VERSION ""

NS_ :

BS_:

BU_:

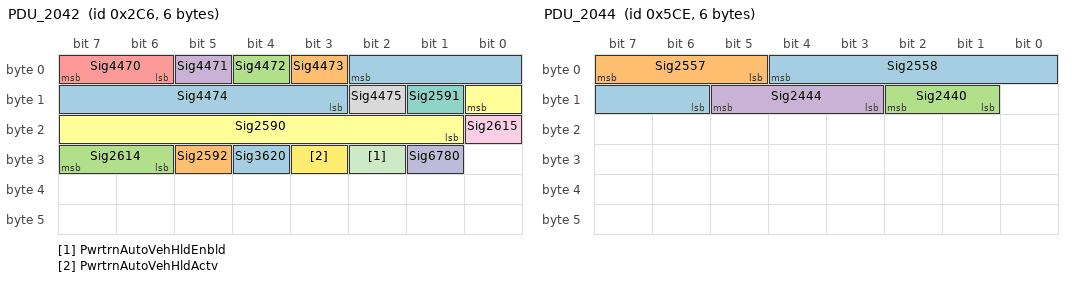
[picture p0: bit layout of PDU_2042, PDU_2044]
BO_ 710 PDU_2042: 6 Vector__XXX
 SG_ Sig4474 : 2|8@0+ (0.1,0) [0|25.5] "Volt" BSM
 SG_ Sig4473 : 3|1@0+ (1,0) [0|1] "" BSM
 SG_ Sig4472 : 4|1@0+ (1,0) [0|1] "" BSM
 SG_ Sig4471 : 5|1@0+ (1,0) [0|1] "" BSM
 SG_ Sig4470 : 7|2@0+ (1,0) [0|3] "" BSM
 SG_ Sig2590 : 8|8@0+ (0.392157,0) [0|100] "%" CGM
 SG_ Sig2591 : 9|1@0+ (1,0) [0|1] "" CGM
 SG_ Sig4475 : 10|1@0+ (1,0) [0|1] "" BSM
 SG_ Sig2615 : 16|1@0+ (1,0) [0|1] "" TCM
 SG_ Sig6780 : 25|1@0+ (1,0) [0|1] "" BSM
 SG_ PwrtrnAutoVehHldEnbld : 26|1@0+ (1,0) [0|1] "" EBCM
 SG_ PwrtrnAutoVehHldActv : 27|1@0+ (1,0) [0|1] "" EBCM
 SG_ Sig3620 : 28|1@0+ (1,0) [0|1] "" BSM,ECP_X1
 SG_ Sig2592 : 29|1@0+ (1,0) [0|1] "" TCM
 SG_ Sig2614 : 31|2@0+ (1,0) [0|3] "" TCM

BO_ 948 PDU_2043: 12 Vector__XXX
 SG_ Sig2550 : 2|12@0+ (0.5,-848) [-848|1199.5] "Nm" RDCM,TCCM,TCM
 SG_ Sig2549 : 6|4@0+ (1,0) [0|15] "" TCM
 SG_ Sig2548 : 7|1@0+ (1,0) [0|1] "" TCM
 SG_ Sig2551 : 22|12@0+ (0.5,-848) [-848|1199.5] "Nm" TCM
 SG_ Sig2552 : 26|12@0+ (0.5,-848) [-848|1199.5] "Nm" TCM
 SG_ Sig2553 : 46|8@0+ (32,0) [0|8160] "rpm" TCM
 SG_ BarPrsAbs : 53|8@0+ (0.5,0) [0|127.5] "kPa" BSM,VICM,CGM,TCM
 SG_ BarPrsAbs_Inv : 54|1@0+ (1,0) [0|1] "" BSM,VICM,CGM,TCM
 SG_ Sig2640 : 60|8@0+ (4,0) [0|1020] "kPa" CGM
 SG_ Sig2642 : 61|1@0+ (1,0) [0|1] "" CGM
 SG_ Sig4942 : 68|8@0+ (0.5,0) [0|127.5] "%" TCM

BO_ 1486 PDU_2044: 6 Vector__XXX
 SG_ Sig2558 : 4|7@0+ (1,0) [0|127] "%" CGM
 SG_ Sig2557 : 7|3@0+ (1,0) [0|5] "" CGM
 SG_ Sig2440 : 10|2@0+ (1,0) [0|1] "" CGM
 SG_ Sig2444 : 13|3@0+ (1,0) [0|7] "" CGM

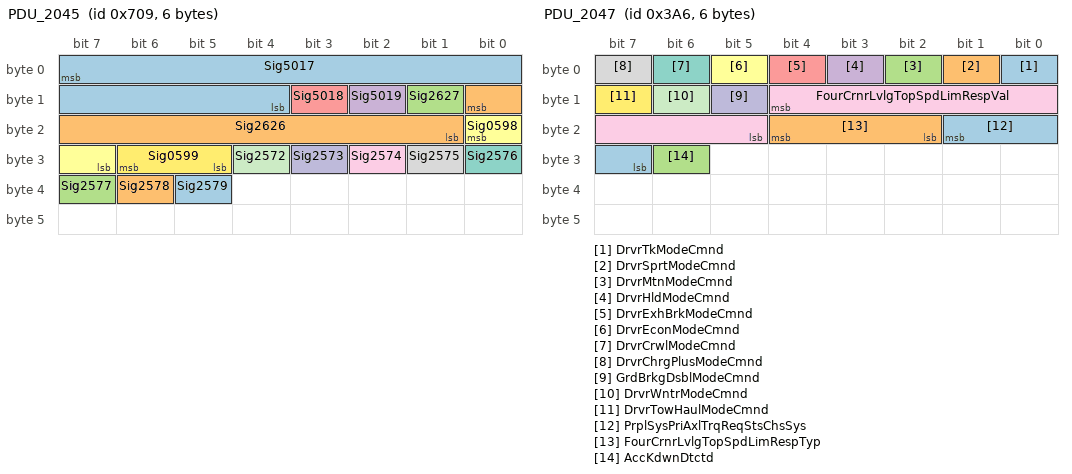
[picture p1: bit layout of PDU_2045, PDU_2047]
BO_ 1801 PDU_2045: 6 Vector__XXX
 SG_ Sig5017 : 7|12@0+ (0.5,0) [0|2047.5] "min" TCM
 SG_ Sig2626 : 8|8@0+ (1,-40) [-40|215] "Deg C" CGM,TCM
 SG_ Sig2627 : 9|1@0+ (1,0) [0|1] "" CGM,TCM
 SG_ Sig5019 : 10|1@0+ (1,0) [0|1] "" TCM
 SG_ Sig5018 : 11|1@0+ (1,0) [0|1] "" TCM
 SG_ Sig0598 : 16|2@0+ (1,0) [0|3] "" TCM
 SG_ Sig2576 : 24|1@0+ (1,0) [0|1] "" CGM
 SG_ Sig2575 : 25|1@0+ (1,0) [0|1] "" CGM
 SG_ Sig2574 : 26|1@0+ (1,0) [0|1] "" CGM
 SG_ Sig2573 : 27|1@0+ (1,0) [0|1] "" CGM
 SG_ Sig2572 : 28|1@0+ (1,0) [0|1] "" CGM
 SG_ Sig0599 : 30|2@0+ (1,0) [0|3] "" TCM
 SG_ Sig2579 : 37|1@0+ (1,0) [0|1] "" CGM
 SG_ Sig2578 : 38|1@0+ (1,0) [0|1] "" CGM
 SG_ Sig2577 : 39|1@0+ (1,0) [0|1] "" CGM

BO_ 63 PDU_2046: 4 Vector__XXX
 SG_ RdLdNomAxlTrq : 7|19@0+ (0.125,-22534) [-22534|43001.9] "Nm" ACP2_MCU,CGM,EOCM,EOCM_HC_Superset,FCM

BO_ 934 PDU_2047: 6 Vector__XXX
 SG_ DrvrTkModeCmnd : 0|1@0+ (1,0) [0|1] "" PCM,TCM,ECP_X1
 SG_ DrvrSprtModeCmnd : 1|1@0+ (1,0) [0|1] "" PCM,TCM,ECP_X1
 SG_ DrvrMtnModeCmnd : 2|1@0+ (1,0) [0|1] "" ECP_X1
 SG_ DrvrHldModeCmnd : 3|1@0+ (1,0) [0|1] "" ECP_X1
 SG_ DrvrExhBrkModeCmnd : 4|1@0+ (1,0) [0|1] "" PCM,TCM
 SG_ DrvrEconModeCmnd : 5|1@0+ (1,0) [0|1] "" PCM,TCM
 SG_ DrvrCrwlModeCmnd : 6|1@0+ (1,0) [0|1] "" CGM,PCM,TCM
 SG_ DrvrChrgPlusModeCmnd : 7|1@0+ (1,0) [0|1] "" ECP_X1
 SG_ FourCrnrLvlgTopSpdLimRespVal : 12|8@0+ (2,0) [0|510] "km/h" CGM
 SG_ GrdBrkgDsblModeCmnd : 13|1@0+ (1,0) [0|1] "" PCM,TCM,ECP_X1
 SG_ DrvrWntrModeCmnd : 14|1@0+ (1,0) [0|1] "" PCM,TCM
 SG_ DrvrTowHaulModeCmnd : 15|1@0+ (1,0) [0|1] "" ACP2_MCU,EOCM,EOCM_HC_Superset,FCM,PCM,TCM,ECP_X1
 SG_ PrplSysPriAxlTrqReqStsChsSys : 17|3@0+ (1,0) [0|6] "" EBCM
 SG_ FourCrnrLvlgTopSpdLimRespTyp : 20|3@0+ (1,0) [0|6] "" CGM
 SG_ AccKdwnDtctd : 30|1@0+ (1,0) [0|1] "" ACP2_MCU,EOCM,EOCM_HC_Superset,FCM,PCM,TCM

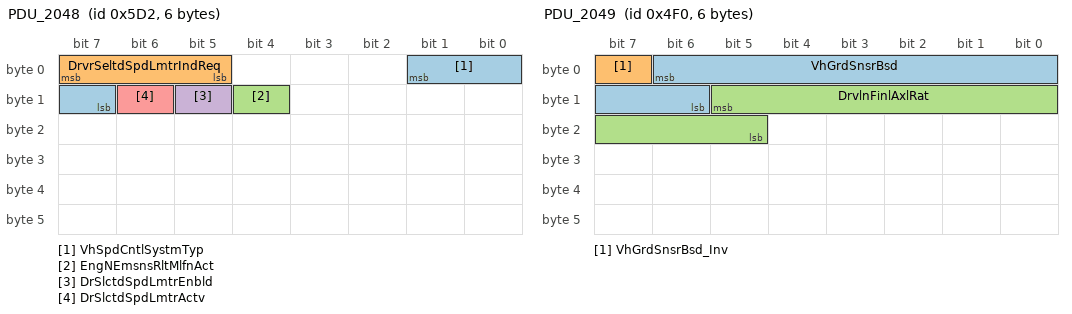
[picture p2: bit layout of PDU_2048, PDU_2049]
BO_ 1490 PDU_2048: 6 Vector__XXX
 SG_ VhSpdCntlSystmTyp : 1|3@0+ (1,0) [0|2] "" ACP2_MCU,CGM,EOCM,EOCM_HC_Superset,FCM
 SG_ DrvrSeltdSpdLmtrIndReq : 7|3@0+ (1,0) [0|4] "" CGM
 SG_ EngNEmsnsRltMlfnAct : 12|1@0+ (1,0) [0|1] "" CGM
 SG_ DrSlctdSpdLmtrEnbld : 13|1@0+ (1,0) [0|1] "" CGM
 SG_ DrSlctdSpdLmtrActv : 14|1@0+ (1,0) [0|1] "" CGM

BO_ 1264 PDU_2049: 6 Vector__XXX
 SG_ VhGrdSnsrBsd : 6|9@0- (0.1945,0) [-49.792|49.5975] "%" ACP2_MCU,VICM,EOCM,EOCM_HC_Superset,E44,PCM,TCM,ECP_S,ECP_S2,ECP_X1
 SG_ VhGrdSnsrBsd_Inv : 7|1@0+ (1,0) [0|1] "" ACP2_MCU,VICM,EOCM,EOCM_HC_Superset,E44,PCM,TCM,ECP_S,ECP_S2,ECP_X1
 SG_ DrvlnFinlAxlRat : 13|9@0+ (0.01,2) [2|7.11] "" DCM,RDCM,TCCM

BO_ 52 PDU_2050: 4 Vector__XXX
 SG_ TrnsOvrllEstTrqRt : 6|15@0- (0.00390625,0) [-64|63.9961] "" CGM,EBCM,ECM,RDCM,TCCM
 SG_ TrnsOvrllEstTrqRt_Inv : 7|1@0+ (1,0) [0|1] "" EBCM,ECM,RDCM,TCCM

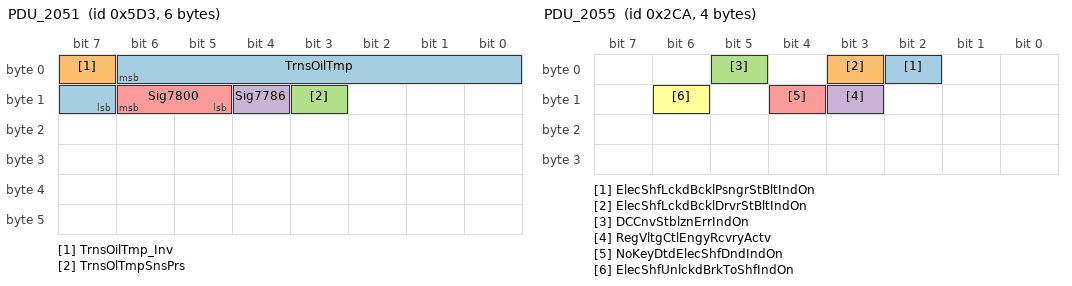
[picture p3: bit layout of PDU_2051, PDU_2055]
BO_ 1491 PDU_2051: 6 Vector__XXX
 SG_ TrnsOilTmp : 6|8@0+ (1,-40) [-40|215] "deg C" BSM,VICM,CGM,DCM,EBCM,ECM,PCM,TCCM,ECP_S,ECP_X1
 SG_ TrnsOilTmp_Inv : 7|1@0+ (1,0) [0|1] "" BSM,VICM,CGM,DCM,EBCM,ECM,PCM,TCCM,ECP_S
 SG_ TrnsOlTmpSnsPrs : 11|1@0+ (1,0) [0|1] "" CGM,TCCM
 SG_ Sig7786 : 12|1@0+ (1,0) [0|1] "" CGM,ECM
 SG_ Sig7800 : 14|2@0+ (1,0) [0|2] "" CGM,ECM

BO_ 99 PDU_2052: 2 Vector__XXX
 SG_ LoVltgSetptCmd : 7|8@0+ (0.07843,0) [0|19.9996] "volt" ECP_X1

BO_ 203 PDU_2053: 2 Vector__XXX
 SG_ RegVltgCtlPwrtrnOvrrdInhbd : 7|1@0+ (1,0) [0|1] "" CGM

BO_ 936 PDU_2054: 6 Vector__XXX
 SG_ GenStptDtCycPtOvrAct : 7|1@0+ (1,0) [0|1] "" CGM

BO_ 714 PDU_2055: 4 Vector__XXX
 SG_ ElecShfLckdBcklPsngrStBltIndOn : 2|1@0+ (1,0) [0|1] "" CGM
 SG_ ElecShfLckdBcklDrvrStBltIndOn : 3|1@0+ (1,0) [0|1] "" CGM
 SG_ DCCnvStblznErrIndOn : 5|1@0+ (1,0) [0|1] "" CGM
 SG_ RegVltgCtlEngyRcvryActv : 11|1@0+ (1,0) [0|1] "" CGM
 SG_ NoKeyDtdElecShfDndIndOn : 12|1@0+ (1,0) [0|1] "" CGM
 SG_ ElecShfUnlckdBrkToShfIndOn : 14|1@0+ (1,0) [0|1] "" CGM

BO_ 1492 PDU_2056: 6 Vector__XXX
 SG_ ElecShfPriTransCtlrMalfIndOn : 0|1@0+ (1,0) [0|1] "" CGM
 SG_ ElecShfPriShfToDrvTryAgnIndOn : 1|1@0+ (1,0) [0|1] "" CGM
 SG_ ElecShfPriRdcSpdForReqdShfIndOn : 2|1@0+ (1,0) [0|1] "" CGM
 SG_ AirCndOffIO : 3|1@0+ (1,0) [0|1] "" CGM
 SG_ EngCmptHotWrnIndReq : 5|2@0+ (1,0) [0|3] "" CGM
 SG_ ElecShftPrTwoGrsSelIndRq : 7|2@0+ (1,0) [0|3] "" CGM
 SG_ ElecShftPrLtdPrfMdIO : 8|1@0+ (1,0) [0|1] "" CGM
 SG_ ElecShftPrHldShftLevEngRngIO : 9|1@0+ (1,0) [0|1] "" CGM
 SG_ ElecShftPrDrPrkIntShftAtmpIO : 10|1@0+ (1,0) [0|1] "" CGM
 SG_ ElecShftPrDrIntShftAtmpIO : 11|1@0+ (1,0) [0|1] "" CGM
 SG_ ElecShftPrDrExitIO : 12|1@0+ (1,0) [0|1] "" CGM
 SG_ ElecShftPrDrDoorStIndIO : 13|1@0+ (1,0) [0|1] "" CGM
 SG_ ElecShftPrAtPrkIO : 14|1@0+ (1,0) [0|1] "" CGM
 SG_ ElecShfPriTrnVehOffForPrkIndOn : 15|1@0+ (1,0) [0|1] "" CGM
 SG_ ElecShftrLckdHldBrkToOvrrdIndOn : 20|1@0+ (1,0) [0|1] "" CGM
 SG_ ElecShftPrTrnMlfIO : 21|1@0+ (1,0) [0|1] "" CGM
 SG_ ElecShftPrRngInvRqIO : 22|1@0+ (1,0) [0|1] "" CGM
 SG_ ElecShftPrPrkInvRqIO : 23|1@0+ (1,0) [0|1] "" CGM

BO_ 1802 PDU_2057: 6 Vector__XXX
 SG_ UndrHdAirFlwCap : 7|9@0+ (2,0) [0|1022] "m^3/min" BSM,PCM,TCM
 SG_ UndrHdAirFlwActPrcnt : 14|7@0+ (0.787402,0) [0|100] "%" BSM,PCM,TCM

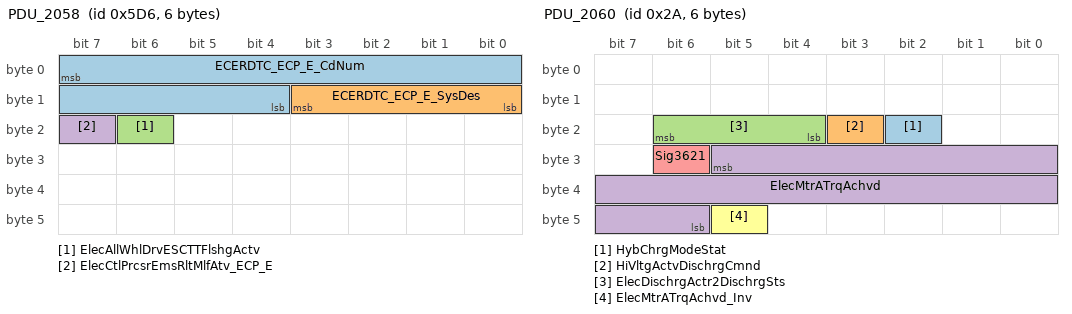
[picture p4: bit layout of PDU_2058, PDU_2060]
BO_ 1494 PDU_2058: 6 Vector__XXX
 SG_ ECERDTC_ECP_E_CdNum : 7|12@0+ (1,0) [0|4095] "count" ECM,PCM
 SG_ ECERDTC_ECP_E_SysDes : 11|4@0+ (1,0) [0|15] "" ECM,PCM
 SG_ ElecAllWhlDrvESCTTFlshgActv : 22|1@0+ (1,0) [0|1] "" EBCM
 SG_ ElecCtlPrcsrEmsRltMlfAtv_ECP_E : 23|1@0+ (1,0) [0|1] "" ECM,PCM

BO_ 1803 PDU_2059: 6 Vector__XXX
 SG_ DrvMtrInvrtMaxTemp : 6|8@0+ (1,-40) [-40|215] "deg C" BSM,VICM,VDM,ECP_S
 SG_ DrvMtrInvrtMaxTemp_Inv : 7|1@0+ (1,0) [0|1] "" BSM,VICM,VDM,ECP_S

BO_ 42 PDU_2060: 6 Vector__XXX
 SG_ HybChrgModeStat : 18|1@0+ (1,0) [0|1] "" BSM,VICM
 SG_ HiVltgActvDischrgCmnd : 19|1@0+ (1,0) [0|1] "" BSM,VICM
 SG_ ElecDischrgActr2DischrgSts : 22|3@0+ (1,0) [0|2] "" BSM,VICM
 SG_ ElecMtrATrqAchvd : 29|16@0- (0.125,0) [-4096|4095.88] "Nm" BSM,VICM,CGM,VDM
 SG_ Sig3621 : 30|1@0+ (1,0) [0|1] "" ECM,PCM
 SG_ ElecMtrATrqAchvd_Inv : 45|1@0+ (1,0) [0|1] "" VDM

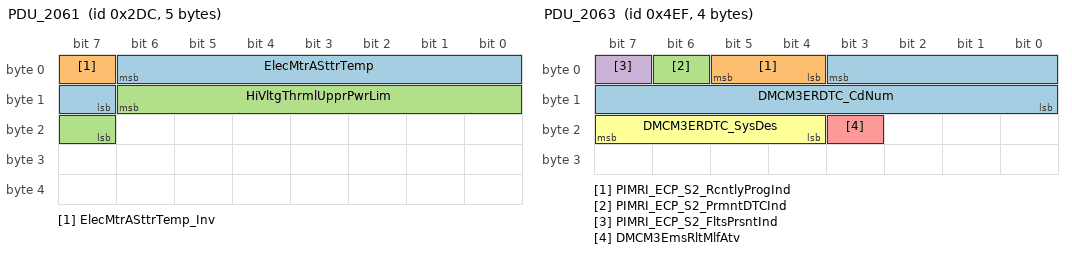
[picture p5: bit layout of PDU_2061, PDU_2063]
BO_ 732 PDU_2061: 5 Vector__XXX
 SG_ ElecMtrASttrTemp : 6|8@0+ (1,-40) [-40|215] "deg C" CGM,VDM
 SG_ ElecMtrASttrTemp_Inv : 7|1@0+ (1,0) [0|1] "" CGM,VDM
 SG_ HiVltgThrmlUpprPwrLim : 14|8@0+ (0.2,0) [0|51] "kW" BSM,VICM

BO_ 43 PDU_2062: 2 Vector__XXX
 SG_ ElecDischrgActr4DischrgSts : 7|3@0+ (1,0) [0|2] "" VICM

BO_ 1263 PDU_2063: 4 Vector__XXX
 SG_ DMCM3ERDTC_CdNum : 3|12@0+ (1,0) [0|4095] "Counts" ECP_E
 SG_ PIMRI_ECP_S2_RcntlyProgInd : 5|2@0+ (1,0) [0|3] "" ECP_E
 SG_ PIMRI_ECP_S2_PrmntDTCInd : 6|1@0+ (1,0) [0|1] "" ECP_E
 SG_ PIMRI_ECP_S2_FltsPrsntInd : 7|1@0+ (1,0) [0|1] "" ECP_E
 SG_ DMCM3EmsRltMlfAtv : 19|1@0+ (1,0) [0|1] "" ECP_E
 SG_ DMCM3ERDTC_SysDes : 23|4@0+ (1,0) [0|15] "" ECP_E

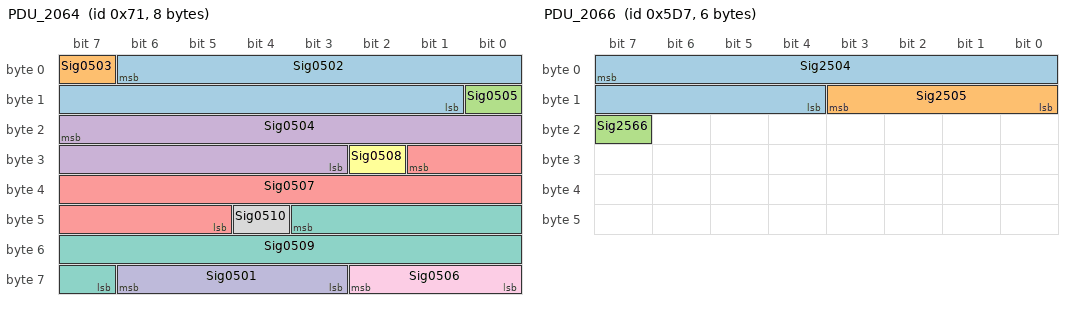
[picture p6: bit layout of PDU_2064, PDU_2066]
BO_ 113 PDU_2064: 8 Vector__XXX
 SG_ Sig0502 : 6|14@0- (0.1,0) [-819.2|819.1] "A" ECM,PCM
 SG_ Sig0503 : 7|1@0+ (1,0) [0|1] "" ECM,PCM
 SG_ Sig0505 : 8|1@0+ (1,0) [0|1] "" ECM,PCM
 SG_ Sig0504 : 23|13@0+ (0.0624,0) [0|511.118] "v" ECM,PCM
 SG_ Sig0507 : 25|13@0- (0.125,0) [-512|511.875] "Nm" ECM,PCM
 SG_ Sig0508 : 26|1@0+ (1,0) [0|1] "" ECM,PCM
 SG_ Sig0509 : 43|13@0- (0.125,0) [-512|511.875] "Nm" ECM,PCM
 SG_ Sig0510 : 44|1@0+ (1,0) [0|1] "" ECM,PCM
 SG_ Sig0506 : 58|3@0+ (1,0) [0|1] "" ECM,PCM
 SG_ Sig0501 : 62|4@0+ (1,0) [0|5] "" ECM,PCM

BO_ 733 PDU_2065: 2 Vector__XXX
 SG_ Sig0511 : 6|7@0+ (1,0) [0|127] "%" ECM,PCM
 SG_ Sig0512 : 7|1@0+ (1,0) [0|1] "" ECM,PCM

BO_ 1495 PDU_2066: 6 Vector__XXX
 SG_ Sig2504 : 7|12@0+ (1,0) [0|4095] "count" ECM,PCM
 SG_ Sig2505 : 11|4@0+ (1,0) [0|15] "" ECM,PCM
 SG_ Sig2566 : 23|1@0+ (1,0) [0|1] "" ECM,PCM

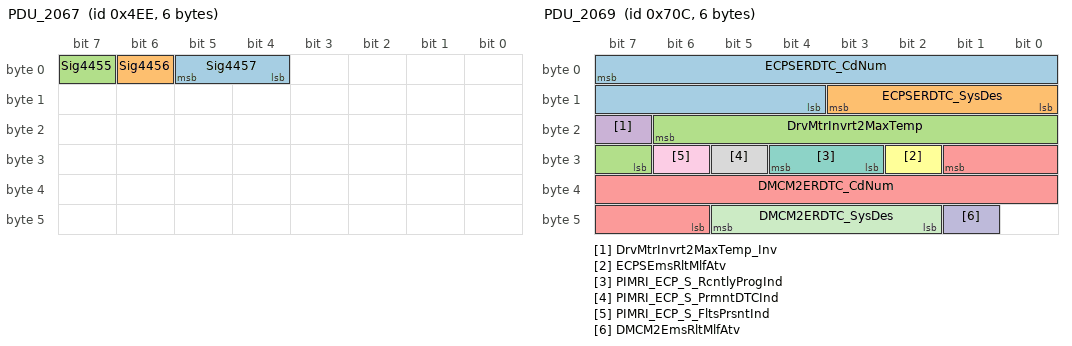
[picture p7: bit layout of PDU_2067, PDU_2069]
BO_ 1262 PDU_2067: 6 Vector__XXX
 SG_ Sig4457 : 5|2@0+ (1,0) [0|3] "" ECM,PCM
 SG_ Sig4456 : 6|1@0+ (1,0) [0|1] "" ECM,PCM
 SG_ Sig4455 : 7|1@0+ (1,0) [0|1] "" ECM,PCM

BO_ 41 PDU_2068: 2 Vector__XXX
 SG_ ElecDischrgActr3DischrgSts : 7|3@0+ (1,0) [0|2] "" VICM

BO_ 1804 PDU_2069: 6 Vector__XXX
 SG_ ECPSERDTC_CdNum : 7|12@0+ (1,0) [0|4095] "" ECP_E
 SG_ ECPSERDTC_SysDes : 11|4@0+ (1,0) [0|15] "" ECP_E
 SG_ DrvMtrInvrt2MaxTemp : 22|8@0+ (1,-40) [-40|215] "deg C" VICM,VDM,ECP_E
 SG_ DrvMtrInvrt2MaxTemp_Inv : 23|1@0+ (1,0) [0|1] "" VICM,VDM,ECP_E
 SG_ DMCM2ERDTC_CdNum : 25|12@0+ (1,0) [0|4095] "Counts" ECP_E
 SG_ ECPSEmsRltMlfAtv : 26|1@0+ (1,0) [0|1] "" ECP_E
 SG_ PIMRI_ECP_S_RcntlyProgInd : 28|2@0+ (1,0) [0|3] "" ECP_E
 SG_ PIMRI_ECP_S_PrmntDTCInd : 29|1@0+ (1,0) [0|1] "" ECP_E
 SG_ PIMRI_ECP_S_FltsPrsntInd : 30|1@0+ (1,0) [0|1] "" ECP_E
 SG_ DMCM2EmsRltMlfAtv : 41|1@0+ (1,0) [0|1] "" ECP_E
 SG_ DMCM2ERDTC_SysDes : 45|4@0+ (1,0) [0|15] "" ECP_E

BO_ 512 PDU_2070: 6 Vector__XXX
 SG_ Sig4937 : 7|19@0- (0.25,0) [-65536|65535.8] "Nm" ECM,PCM
 SG_ Sig4938 : 20|19@0- (0.25,0) [-65536|65535.8] "Nm" ECM,PCM

BO_ 734 PDU_2071: 4 Vector__XXX
 SG_ ElecMtrARotrTemp : 6|8@0+ (1,-40) [-40|215] "deg C" CGM,VDM
 SG_ ElecMtrARotrTemp_Inv : 7|1@0+ (1,0) [0|1] "" CGM,VDM

BO_ 1497 PDU_2072: 6 Vector__XXX
 SG_ Sig2564 : 5|2@0+ (1,0) [0|2] "" CGM
 SG_ Sig2563 : 7|2@0+ (1,0) [0|2] "" CGM

BO_ 1415 PDU_2073: 8 Vector__XXX
 SG_ RCMHSR_HptcStReqSeqNum : 1|2@0+ (1,0) [0|3] "counts" CGM
 SG_ RCMHSR_HptcStReqPuls : 7|6@0+ (1,0) [0|63] "pulses" CGM
 SG_ HtdStrgWhlDrvOutStsGtd : 9|3@0+ (1,0) [0|7] "" CGM
 SG_ HtdStrgWhlDrvOutStsGtd_Inv : 10|1@0+ (1,0) [0|1] "" CGM
 SG_ LnCntrWrnIndRqst : 15|5@0+ (1,0) [0|16] "" CGM
 SG_ LnFllwgHzrdLgtsReq : 16|2@0+ (1,0) [0|2] "" CGM
 SG_ LnCntrEsclnSts : 18|2@0+ (1,0) [0|3] "" CGM
 SG_ HtdStrgWhlStkSwGtd : 19|1@0+ (1,0) [0|1] "" CGM
 SG_ HtdStrgWhlStkSwGtd_Inv : 20|1@0+ (1,0) [0|1] "" CGM
 SG_ HtdStrgWhlExtrnFltPrsntGtd : 21|1@0+ (1,0) [0|1] "" CGM
 SG_ HtdStrgWhlExtrnFltPrsntGtd_Inv : 22|1@0+ (1,0) [0|1] "" CGM
 SG_ CIBAutoBrkRelIndOn : 24|1@0+ (1,0) [0|1] "" CGM
 SG_ RIMIntCllnChmEvStat : 26|2@0+ (1,0) [0|2] "" CGM
 SG_ RIMBrkPlsChEvStat : 28|2@0+ (1,0) [0|2] "" CGM
 SG_ ManHtdStrgWhlReqdGtd : 29|1@0+ (1,0) [0|1] "" CGM
 SG_ ManHtdStrgWhlReqdGtd_Inv : 30|1@0+ (1,0) [0|1] "" CGM
 SG_ RIM_BrkPrfllReq : 32|1@0+ (1,0) [0|1] "" EBCM
 SG_ RIMUnIndOn : 33|1@0+ (1,0) [0|1] "" CGM
 SG_ RIMONIndOn : 34|1@0+ (1,0) [0|1] "" CGM
 SG_ RIMOFFIndOn : 35|1@0+ (1,0) [0|1] "" CGM
 SG_ LnCntrMisuseCond : 36|1@0+ (1,0) [0|1] "" CGM
 SG_ LnCntrDrvAwrIndOn : 37|1@0+ (1,0) [0|1] "" CGM
 SG_ HtdStrgWhlSwActvGtd : 38|1@0+ (1,0) [0|1] "" CGM
 SG_ FIM_CIS_BrkPrfllReq : 39|1@0+ (1,0) [0|1] "" EBCM
 SG_ SuprRmtPrkSptSeltnRmtReq : 40|2@0+ (1,0) [0|3] "" CGM
 SG_ SuprRmtPrkSptSeltnKeepLkReq : 42|2@0+ (1,0) [0|3] "" CGM
 SG_ SuprRmtPrkSptSeltnAcceptReq : 44|2@0+ (1,0) [0|3] "" CGM
 SG_ TnDrvRIMOFFUnvIndOn : 45|1@0+ (1,0) [0|1] "" CGM
 SG_ RrVirtBmpAutoBrkRelIndOn : 46|1@0+ (1,0) [0|1] "" CGM
 SG_ RIM_BrkPulsReq : 47|1@0+ (1,0) [0|1] "" EBCM
 SG_ SuprRmtPrkUnabletoCnctTryAgnReq : 52|2@0+ (1,0) [0|3] "" CGM
 SG_ SuprRmtPrkUnabletoCnctExtReq : 54|2@0+ (1,0) [0|3] "" CGM

BO_ 1431 PDU_2074: 6 Vector__XXX
 SG_ LnChgDmndMomtryLnChgDsbl : 5|1@0+ (1,0) [0|1] "" CGM
 SG_ LnChgDmndLnChgReq : 7|2@0+ (1,0) [0|2] "" CGM

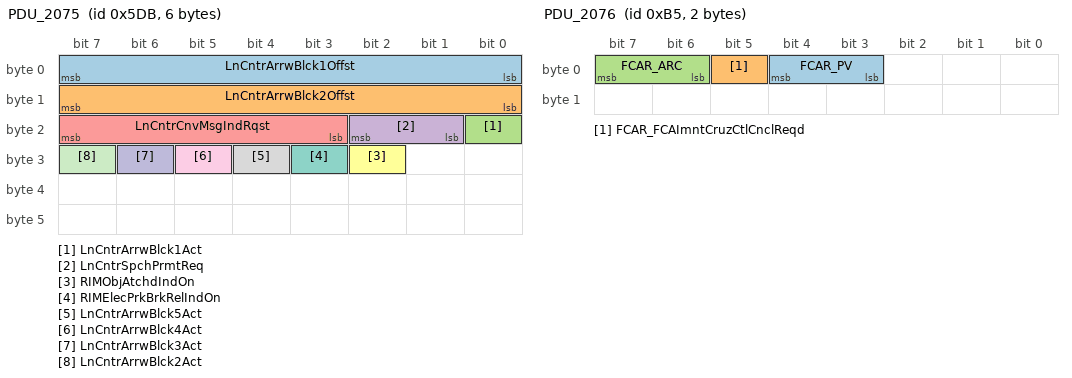
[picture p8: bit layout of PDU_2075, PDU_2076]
BO_ 1499 PDU_2075: 6 Vector__XXX
 SG_ LnCntrArrwBlck1Offst : 7|8@0- (1,0) [-128|127] "" CGM
 SG_ LnCntrArrwBlck2Offst : 15|8@0- (1,0) [-128|127] "" CGM
 SG_ LnCntrArrwBlck1Act : 16|1@0+ (1,0) [0|1] "" CGM
 SG_ LnCntrSpchPrmtReq : 18|2@0+ (1,0) [0|2] "" CGM
 SG_ LnCntrCnvMsgIndRqst : 23|5@0+ (1,0) [0|21] "" CGM
 SG_ RIMObjAtchdIndOn : 26|1@0+ (1,0) [0|1] "" CGM
 SG_ RIMElecPrkBrkRelIndOn : 27|1@0+ (1,0) [0|1] "" CGM
 SG_ LnCntrArrwBlck5Act : 28|1@0+ (1,0) [0|1] "" CGM
 SG_ LnCntrArrwBlck4Act : 29|1@0+ (1,0) [0|1] "" CGM
 SG_ LnCntrArrwBlck3Act : 30|1@0+ (1,0) [0|1] "" CGM
 SG_ LnCntrArrwBlck2Act : 31|1@0+ (1,0) [0|1] "" CGM

BO_ 181 PDU_2076: 2 Vector__XXX
 SG_ FCAR_PV : 4|2@0+ (1,0) [0|3] "" ECM,PCM,ECP_E
 SG_ FCAR_FCAImntCruzCtlCnclReqd : 5|1@0+ (1,0) [0|1] "" ECM,PCM,ECP_E
 SG_ FCAR_ARC : 7|2@0+ (1,0) [0|3] "" ECM,PCM,ECP_E

BO_ 1416 PDU_2077: 12 Vector__XXX
 SG_ ACCHSR_HptcStReqSeqNum : 1|2@0+ (1,0) [0|3] "counts" CGM
 SG_ ACCHSR_HptcStReqPuls : 7|6@0+ (1,0) [0|63] "pulses" CGM
 SG_ FPCMHSR_HptcStReqSeqNum : 9|2@0+ (1,0) [0|3] "counts" CGM
 SG_ FPCMHSR_HptcStReqPuls : 15|6@0+ (1,0) [0|63] "pulses" CGM
 SG_ FCAIAHSR_HptcStReqSeqNum : 17|2@0+ (1,0) [0|3] "pulses" CGM
 SG_ FCAIAHSR_HptcStReqPuls : 23|6@0+ (1,0) [0|63] "pulses" CGM
 SG_ LDWCLHSHSR_HptcStReqSeqNum : 25|2@0+ (1,0) [0|3] "counts" CGM
 SG_ LDWCLHSHSR_HptcStReqPuls : 31|6@0+ (1,0) [0|63] "pulses" CGM
 SG_ LDWCRHSHSR_HptcStReqSeqNum : 33|2@0+ (1,0) [0|3] "counts" CGM
 SG_ LDWCRHSHSR_HptcStReqPuls : 39|6@0+ (1,0) [0|63] "pulses" CGM
 SG_ LKALnMrkgIndLt : 41|3@0+ (1,0) [0|4] "" CGM
 SG_ GoNotfrCstCrStVal : 44|3@0+ (1,0) [0|7] "" CGM
 SG_ FrwdVhImAlrtIndRqst : 47|3@0+ (1,0) [0|7] "" CGM
 SG_ LnDtWrnCntrlVsAlrtCmdGnc : 48|3@0+ (1,0) [0|4] "" CGM
 SG_ LnDtWrnCntrlFtrSt : 51|3@0+ (1,0) [0|4] "" CGM
 SG_ LKALnMrkgIndRt : 54|3@0+ (1,0) [0|4] "" CGM
 SG_ LDWCtrlHndOff1ChmEvntStat : 57|2@0+ (1,0) [0|2] "" CGM
 SG_ FrwdCllsnAlrtImAlrtDrIntAlrtChmE : 59|2@0+ (1,0) [0|2] "" CGM
 SG_ FrntPCMChmEvntStat : 61|2@0+ (1,0) [0|2] "" CGM
 SG_ LDWCtrlRtHndSdChmEvntStat : 65|2@0+ (1,0) [0|2] "" CGM
 SG_ LDWCtrlLtHndSdChmEvntStat : 67|2@0+ (1,0) [0|2] "" CGM
 SG_ LDWCtrlHndOff3ChmEvntStat : 69|2@0+ (1,0) [0|2] "" CGM
 SG_ LDWCtrlHndOff2ChmEvntStat : 71|2@0+ (1,0) [0|2] "" CGM
 SG_ LDWCtrlAudAttnReqd : 75|1@0+ (1,0) [0|1] "" CGM
 SG_ GoNotfrCstStAvl : 76|1@0+ (1,0) [0|1] "" CGM
 SG_ FrwdVhHdwyAlrtIndOn : 77|1@0+ (1,0) [0|1] "" CGM
 SG_ FCA_BrkPrfllReq : 78|1@0+ (1,0) [0|1] "" EBCM
 SG_ AdptCrsCntrlEngd : 79|1@0+ (1,0) [0|1] "" CGM

BO_ 1500 PDU_2078: 8 Vector__XXX
 SG_ ACCTrlrGapSetIndOn : 0|1@0+ (1,0) [0|1] "" CGM
 SG_ FllwgTmIndVal : 7|7@0+ (0.1,0) [0|12.7] "s" CGM
 SG_ FllwgTmDsplyMd : 9|5@0+ (1,0) [0|4] "" CGM
 SG_ FrwdHdwyVisIndCtl : 11|2@0+ (1,0) [0|2] "" CGM
 SG_ FCA_ACCGapSetIndOn : 12|1@0+ (1,0) [0|1] "" CGM
 SG_ FCAACCGapSeltn : 15|3@0+ (1,0) [0|4] "" CGM
 SG_ LAOA_LatAsstHoLFOptAval : 16|1@0+ (1,0) [0|1] "" CGM
 SG_ AdpAndCnvntlCruzCtlIndReq : 20|4@0+ (1,0) [0|9] "" CGM
 SG_ LtAstStsIndRq : 25|3@0+ (1,0) [0|4] "" CGM
 SG_ FCAGpSet : 28|3@0+ (1,0) [0|5] "" CGM
 SG_ LAOA_LatAsstOffOptAval : 29|1@0+ (1,0) [0|1] "" CGM
 SG_ LAOA_LatAsstLKAOptAval : 30|1@0+ (1,0) [0|1] "" CGM
 SG_ LAOA_LatAsstLDWOptAval : 31|1@0+ (1,0) [0|1] "" CGM
 SG_ PdWrnIndRqst : 32|2@0+ (1,0) [0|3] "" CGM
 SG_ LnDprtrWrnCtlSdThrtRtMirIndReq : 34|2@0+ (1,0) [0|3] "" CGM
 SG_ LnDprtrWrnCtlSdThrtLtMirIndReq : 36|2@0+ (1,0) [0|3] "" CGM
 SG_ ACCHdwySttng : 38|2@0+ (1,0) [0|2] "" CGM
 SG_ FrtPedtrnBrkgWrnIndOn : 40|1@0+ (1,0) [0|1] "" CGM
 SG_ ACCTmpUnvIndOn : 41|1@0+ (1,0) [0|1] "" CGM
 SG_ ACCSysSlctdMdDspIndOn : 42|1@0+ (1,0) [0|1] "" CGM
 SG_ ACCShftToPrkBfrExIndOn : 43|1@0+ (1,0) [0|1] "" CGM
 SG_ ACCRtSpdAdVsIndOn : 44|1@0+ (1,0) [0|1] "" CGM
 SG_ ACCHdwySttngIndOn : 45|1@0+ (1,0) [0|1] "" CGM
 SG_ ACCDsngIndOn : 46|1@0+ (1,0) [0|1] "" CGM
 SG_ SrvDvrAsstSystVslMsgRqstOn : 48|1@0+ (1,0) [0|1] "" CGM
 SG_ LnKpAsstUnAvIndOn : 49|1@0+ (1,0) [0|1] "" CGM
 SG_ LnDprtrWrngUnAvIndOn : 50|1@0+ (1,0) [0|1] "" CGM
 SG_ FrwdClsnSysIndOn : 51|1@0+ (1,0) [0|1] "" CGM
 SG_ FrwdCllsnSysUnIndOn : 52|1@0+ (1,0) [0|1] "" CGM
 SG_ FrwdCllsnSysRdIndOn : 53|1@0+ (1,0) [0|1] "" CGM
 SG_ FrwdCllsnSysOffIndOn : 54|1@0+ (1,0) [0|1] "" CGM
 SG_ FrwdCllsnAlrtOffIndOn : 55|1@0+ (1,0) [0|1] "" CGM
 SG_ TnDrvGapAdjUnvIndOn : 61|1@0+ (1,0) [0|1] "" CGM
 SG_ TeenDrvrLnDprtrWrnOffUnvIndOn : 62|1@0+ (1,0) [0|1] "" CGM
 SG_ SrvFrwdCllsnSysIndOn : 63|1@0+ (1,0) [0|1] "" CGM

BO_ 941 PDU_2079: 6 Vector__XXX
 SG_ HstVehTrlrDtd : 7|2@0+ (1,0) [0|3] "" CGM

BO_ 1261 PDU_2080: 12 Vector__XXX
 SG_ Sig6920 : 0|1@0+ (1,0) [0|1] "" ADIMa,ADIMb
 SG_ Sig6919 : 7|7@0+ (1,0) [0|127] "%" ADIMa,ADIMb
 SG_ Sig6922 : 14|7@0+ (1,0) [0|127] "%" ADIMa,ADIMb
 SG_ Sig6921 : 15|1@0+ (1,0) [0|1] "" ADIMa,ADIMb
 SG_ Sig6926 : 21|7@0+ (1,0) [0|127] "%" ADIMa,ADIMb
 SG_ Sig6924 : 22|1@0+ (1,0) [0|1] "" ADIMa,ADIMb
 SG_ Sig6923 : 23|1@0+ (1,0) [0|1] "" ADIMa,ADIMb
 SG_ Sig6929 : 28|7@0+ (1,0) [0|127] "%" ADIMa,ADIMb
 SG_ Sig6928 : 29|1@0+ (1,0) [0|1] "" ADIMa,ADIMb
 SG_ Sig6927 : 30|1@0+ (1,0) [0|1] "" ADIMa,ADIMb
 SG_ Sig6932 : 35|7@0+ (1,0) [0|127] "%" ADIMa,ADIMb
 SG_ Sig6931 : 36|1@0+ (1,0) [0|1] "" ADIMa,ADIMb
 SG_ Sig6930 : 37|1@0+ (1,0) [0|1] "" ADIMa,ADIMb
 SG_ Sig6925 : 42|7@0+ (1,0) [0|127] "%" ADIMa,ADIMb
 SG_ Sig6934 : 43|1@0+ (1,0) [0|1] "" ADIMa,ADIMb
 SG_ Sig6933 : 44|1@0+ (1,0) [0|1] "" ADIMa,ADIMb
 SG_ Sig6935 : 51|7@0+ (1,0) [0|127] "%" ADIMa,ADIMb
 SG_ Sig6954 : 60|7@0+ (1,0) [0|127] "%" ADIMa,ADIMb
 SG_ Sig6955 : 69|7@0+ (1,0) [0|127] "%" ADIMa,ADIMb,CGM

BO_ 1418 PDU_2081: 6 Vector__XXX
 SG_ LSCMB_BrkPrfllReq : 6|1@0+ (1,0) [0|1] "" EBCM
 SG_ Sig4119 : 7|1@0+ (1,0) [0|1] "" CGM

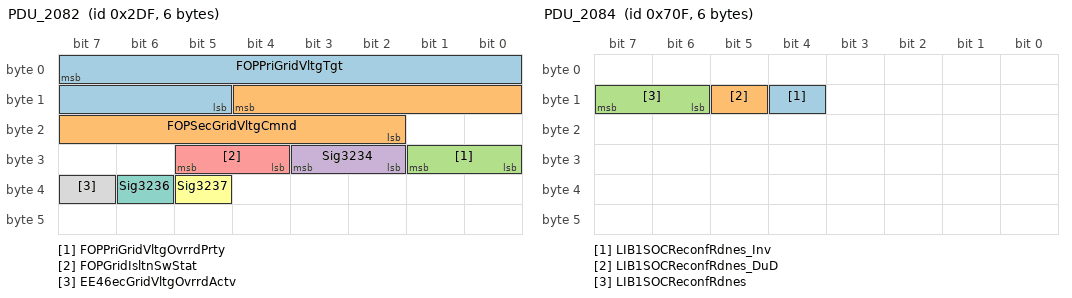
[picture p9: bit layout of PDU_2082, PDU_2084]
BO_ 735 PDU_2082: 6 Vector__XXX
 SG_ FOPPriGridVltgTgt : 7|11@0+ (0.01,0) [0|20.47] "Volts" CGM
 SG_ FOPSecGridVltgCmnd : 12|11@0+ (0.01,0) [0|20.47] "Volts" CGM
 SG_ FOPPriGridVltgOvrrdPrty : 25|2@0+ (1,0) [0|3] "" CGM
 SG_ Sig3234 : 27|2@0+ (1,0) [0|2] "" LIB1
 SG_ FOPGridIsltnSwStat : 29|2@0+ (1,0) [0|3] "" CGM
 SG_ Sig3237 : 37|1@0+ (1,0) [0|1] "" ADIMa,ADIMb
 SG_ Sig3236 : 38|1@0+ (1,0) [0|1] "" ADIMa,ADIMb
 SG_ EE46ecGridVltgOvrrdActv : 39|1@0+ (1,0) [0|1] "" CGM

BO_ 663 PDU_2083: 12 Vector__XXX
 SG_ LIB1PackIntrnlVltg : 6|11@0+ (0.01,3) [3|23.47] "Volts" CGM,FOPM
 SG_ LIB1PackIntrnlVltg_Inv : 7|1@0+ (1,0) [0|1] "" CGM,FOPM
 SG_ LIB1CellMaxVltg : 11|10@0+ (0.005,1.4) [1.4|6.515] "Volts" CGM,FOPM
 SG_ LIB1CellMaxVltg_Inv : 16|1@0+ (1,0) [0|1] "" CGM,FOPM
 SG_ LIB1CellMaxVltg_DuD : 17|1@0+ (1,0) [0|1] "" CGM
 SG_ LIB1CellMinVltg : 30|10@0+ (0.005,1.4) [1.4|6.515] "Volts" CGM,FOPM
 SG_ LIB1CellMinVltg_Inv : 31|1@0+ (1,0) [0|1] "" CGM,FOPM
 SG_ LIB1SOH : 35|8@0+ (0.392156,0) [0|99.9998] "%" CGM,FOPM
 SG_ LIB1SOH_Inv : 36|1@0+ (1,0) [0|1] "" CGM,FOPM
 SG_ Sig3999 : 42|5@0+ (20,0) [0|620] "A" FOPM
 SG_ Sig4000 : 43|1@0+ (1,0) [0|1] "" FOPM
 SG_ Sig4001 : 52|5@0+ (20,0) [0|620] "A" FOPM
 SG_ Sig4002 : 53|1@0+ (1,0) [0|1] "" FOPM
 SG_ Sig4005 : 56|5@0+ (20,0) [0|620] "A" FOPM
 SG_ Sig4006 : 57|1@0+ (1,0) [0|1] "" FOPM
 SG_ Sig4003 : 62|5@0+ (20,0) [0|620] "A" FOPM
 SG_ Sig4004 : 63|1@0+ (1,0) [0|1] "" FOPM
 SG_ LIB1CntctrSlfTstRslts : 66|3@0+ (1,0) [0|2] "" CGM,FOPM
 SG_ LIB1CntctrSlfTstRslts_Inv : 67|1@0+ (1,0) [0|1] "" CGM,FOPM
 SG_ LIB1EOLFlt : 74|2@0+ (1,0) [0|3] "" CGM,FOPM
 SG_ LIB1EOLFlt_Inv : 75|1@0+ (1,0) [0|1] "" CGM,FOPM
 SG_ LIB1TempFlt_Inv : 76|1@0+ (1,0) [0|1] "" ADIMa,ADIMb,CGM,FOPM
 SG_ LIB1TempFlt_DuD : 77|1@0+ (1,0) [0|1] "" CGM
 SG_ LIB1TempFlt : 79|2@0+ (1,0) [0|3] "" ADIMa,ADIMb,CGM,FOPM
 SG_ LIB1CurrFlt : 82|1@0+ (1,0) [0|1] "" CGM,FOPM
 SG_ LIB1CurrFlt_Inv : 83|1@0+ (1,0) [0|1] "" CGM,FOPM
 SG_ Sig3997 : 84|1@0+ (1,0) [0|1] "" FOPM
 SG_ Sig3998 : 85|1@0+ (1,0) [0|1] "" FOPM

BO_ 1807 PDU_2084: 6 Vector__XXX
 SG_ LIB1SOCReconfRdnes_Inv : 12|1@0+ (1,0) [0|1] "" CGM,FOPM
 SG_ LIB1SOCReconfRdnes_DuD : 13|1@0+ (1,0) [0|1] "" CGM
 SG_ LIB1SOCReconfRdnes : 15|2@0+ (1,0) [0|3] "" CGM,FOPM

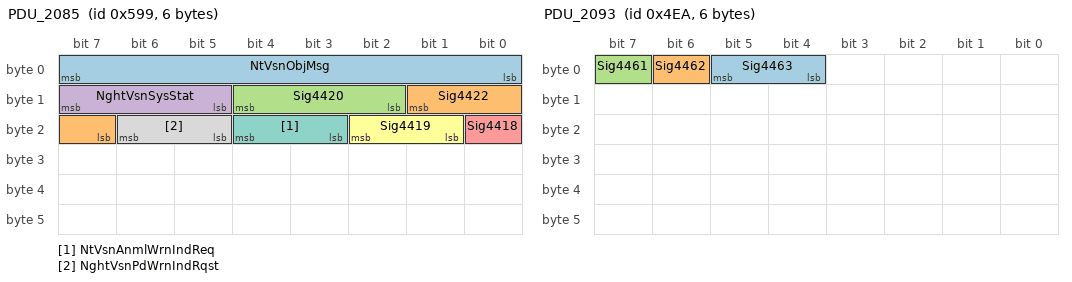
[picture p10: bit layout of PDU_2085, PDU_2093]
BO_ 1433 PDU_2085: 6 Vector__XXX
 SG_ NtVsnObjMsg : 7|8@0+ (1,0) [0|255] "counts" ACP2_MCU,EOCM,EOCM_HC_Superset,FCM
 SG_ Sig4422 : 9|3@0+ (1,0) [0|7] "" CGM
 SG_ Sig4420 : 12|3@0+ (1,0) [0|7] "" CGM
 SG_ NghtVsnSysStat : 15|3@0+ (1,0) [0|7] "" ACP2_MCU,CGM,EOCM,EOCM_HC_Superset,FCM
 SG_ Sig4418 : 16|1@0+ (1,0) [0|1] "" CGM
 SG_ Sig4419 : 18|2@0+ (1,0) [0|3] "" CGM
 SG_ NtVsnAnmlWrnIndReq : 20|2@0+ (1,0) [0|3] "" ACP2_MCU,EOCM,EOCM_HC_Superset,FCM
 SG_ NghtVsnPdWrnIndRqst : 22|2@0+ (1,0) [0|3] "" ACP2_MCU,EOCM,EOCM_HC_Superset,FCM

BO_ 1434 PDU_2086: 6 Vector__XXX
 SG_ Sig8061 : 3|8@0+ (1,0) [0|255] "km/h" CGM
 SG_ Sig3405 : 7|4@0+ (1,0) [0|15] "" CGM

BO_ 1502 PDU_2087: 6 Vector__XXX
 SG_ SecAxl4WDAWDThrCap : 7|9@0+ (0.2,0) [0|102.2] "%" EBCM
 SG_ SecAxlThrmCapPrtRqAct : 14|1@0+ (1,0) [0|1] "" EBCM

BO_ 111 PDU_2088: 12 Vector__XXX
 SG_ Sig7791 : 6|16@0+ (0.0078125,0) [0|511.992] "rot" ECM
 SG_ Sig7793 : 7|1@0+ (1,0) [0|1] "" ECM
 SG_ Sig7794 : 21|15@0- (0.00390625,0) [-64|63.9961] "" ECM
 SG_ Sig7795 : 22|1@0+ (1,0) [0|1] "" ECM
 SG_ Sig7772 : 37|12@0+ (0.5,-848) [-848|1199.5] "Nm" ECM
 SG_ Sig7773 : 38|1@0+ (1,0) [0|1] "" ECM
 SG_ Sig0609 : 41|10@0+ (0.015625,0) [0|15.9844] "" ECM
 SG_ Sig0610 : 63|10@0+ (0.015625,0) [0|15.9844] "" ECM
 SG_ Sig7629 : 69|8@0+ (0.0156,0) [0|3.978] "" ECM
 SG_ Sig7792 : 75|1@0+ (1,0) [0|1] "" ECM
 SG_ AtTrnsGrSftDrct : 77|2@0+ (1,0) [0|2] "" ACP2_MCU,CGM,ECM,EOCM,EOCM_HC_Superset,FCM,PCM,RDCM,TCCM

BO_ 196 PDU_2089: 8 Vector__XXX
 SG_ Sig0589 : 0|1@0+ (1,0) [0|1] "" ECM
 SG_ Sig0588 : 1|1@0+ (1,0) [0|1] "" ECM
 SG_ Sig0587 : 2|1@0+ (1,0) [0|1] "" ECM
 SG_ Sig0586 : 3|1@0+ (1,0) [0|1] "" ECM
 SG_ Sig0585 : 4|1@0+ (1,0) [0|1] "" ECM
 SG_ Sig0584 : 5|1@0+ (1,0) [0|1] "" ECM
 SG_ Sig0583 : 6|1@0+ (1,0) [0|1] "" ECM
 SG_ Sig0582 : 7|1@0+ (1,0) [0|1] "" ECM
 SG_ Sig0597 : 8|1@0+ (1,0) [0|1] "" ECM
 SG_ Sig0596 : 9|1@0+ (1,0) [0|1] "" ECM
 SG_ Sig0595 : 10|1@0+ (1,0) [0|1] "" ECM
 SG_ Sig0594 : 11|1@0+ (1,0) [0|1] "" ECM
 SG_ Sig0593 : 12|1@0+ (1,0) [0|1] "" ECM
 SG_ Sig0592 : 13|1@0+ (1,0) [0|1] "" ECM
 SG_ Sig0591 : 14|1@0+ (1,0) [0|1] "" ECM
 SG_ Sig0590 : 15|1@0+ (1,0) [0|1] "" ECM
 SG_ Sig7803 : 23|12@0- (1,0) [-2048|2047] "rpm" ECM
 SG_ Sig7804 : 27|8@0+ (4,0) [0|1020] "Nm" ECM
 SG_ Sig7621 : 32|1@0+ (1,0) [0|1] "" ECM
 SG_ Sig7801 : 35|3@0+ (1,0) [0|4] "" CGM,ECM
 SG_ Sig7802 : 46|1@0+ (1,0) [0|1] "" CGM,ECM
 SG_ Sig7628 : 47|1@0+ (1,0) [0|1] "" ECM

BO_ 719 PDU_2090: 2 Vector__XXX
 SG_ Sig7775 : 7|1@0+ (1,0) [0|1] "" ECM

BO_ 937 PDU_2091: 12 Vector__XXX
 SG_ Sig7652 : 7|8@0+ (2,0) [0|510] "km / h" ECM
 SG_ Sig7785 : 15|8@0+ (0.07843,0) [0|19.9996] "volts" ECM
 SG_ Sig7784 : 16|1@0+ (1,0) [0|1] "" ECM
 SG_ TrnsTUTDMdSt : 18|2@0+ (1,0) [0|2] "" VICM,CGM,ECM,PCM
 SG_ Sig2416 : 22|4@0+ (1,0) [0|10] "" CGM
 SG_ DrvShftCntrlReqDndIO : 23|1@0+ (1,0) [0|1] "" CGM
 SG_ Sig7796 : 25|3@0+ (1,0) [0|4] "" CGM
 SG_ Sig2421 : 28|3@0+ (1,0) [0|3] "" ECM
 SG_ Sig7783 : 31|3@0+ (1,0) [0|7] "" ECM
 SG_ Sig7643 : 32|2@0+ (1,0) [0|3] "" ECM
 SG_ Sig7642 : 34|2@0+ (1,0) [0|2] "" ECM
 SG_ Sig7630 : 36|2@0+ (1,0) [0|3] "" ECM
 SG_ Sig3595 : 38|2@0+ (1,0) [0|3] "" ECM
 SG_ Sig7647 : 40|2@0+ (1,0) [0|3] "" ECM
 SG_ Sig7646 : 42|2@0+ (1,0) [0|3] "" ECM
 SG_ Sig7645 : 44|2@0+ (1,0) [0|3] "" ECM
 SG_ Sig7644 : 46|2@0+ (1,0) [0|3] "" ECM
 SG_ Sig7782 : 48|2@0+ (1,0) [0|2] "" ECM
 SG_ Sig7774 : 50|2@0+ (1,0) [0|2] "" ECM
 SG_ Sig7649 : 52|2@0+ (1,0) [0|3] "" ECM
 SG_ Sig7648 : 54|2@0+ (1,0) [0|3] "" ECM
 SG_ Sig0436 : 56|1@0+ (1,0) [0|1] "" ECM
 SG_ Sig7797 : 65|1@0+ (1,0) [0|1] "" ECM
 SG_ Sig7781 : 66|1@0+ (1,0) [0|1] "" ECM
 SG_ Sig7779 : 67|1@0+ (1,0) [0|1] "" ECM
 SG_ Sig7641 : 68|1@0+ (1,0) [0|1] "" ECM,ECP_X1
 SG_ Sig7640 : 69|1@0+ (1,0) [0|1] "" ECM
 SG_ Sig2588 : 70|1@0+ (1,0) [0|1] "" ECM
 SG_ DCTLnchCtlAllwd : 71|1@0+ (1,0) [0|1] "" EBCM

BO_ 1256 PDU_2092: 12 Vector__XXX
 SG_ Sig7521 : 3|8@0+ (0.392157,0) [0|100] "%" CGM
 SG_ Sig7520 : 7|4@0+ (1,0) [0|8] "" CGM
 SG_ Sig7522 : 11|8@0+ (0.392157,0) [0|100] "%" CGM
 SG_ Sig7528 : 19|12@0+ (1,0) [0|4095] "" ECM
 SG_ Sig7529 : 39|4@0+ (1,0) [0|15] "" ECM
 SG_ Sig7638 : 41|8@0+ (1,-40) [-40|215] "C" ECM
 SG_ Sig7789 : 49|8@0+ (0.392157,0) [0|100] "%" CGM
 SG_ Sig7639 : 57|3@0+ (1,0) [0|4] "" ECM
 SG_ Sig3509 : 64|1@0+ (1,0) [0|1] "" CGM
 SG_ Sig7798 : 67|3@0+ (1,0) [0|3] "" CGM
 SG_ Sig7650 : 70|3@0+ (1,0) [0|6] "" ECM
 SG_ Sig7790 : 77|1@0+ (1,0) [0|1] "" CGM,ECM
 SG_ Sig7787 : 78|1@0+ (1,0) [0|1] "" CGM
 SG_ Sig7776 : 79|1@0+ (1,0) [0|1] "" CGM,ECM

BO_ 1258 PDU_2093: 6 Vector__XXX
 SG_ Sig4463 : 5|2@0+ (1,0) [0|3] "" ECM
 SG_ Sig4462 : 6|1@0+ (1,0) [0|1] "" ECM
 SG_ Sig4461 : 7|1@0+ (1,0) [0|1] "" ECM

BO_ 737 PDU_2094: 6 Vector__XXX
 SG_ APMLoVltgEnblCmd : 39|4@0+ (1,0) [0|13] "" FOPM

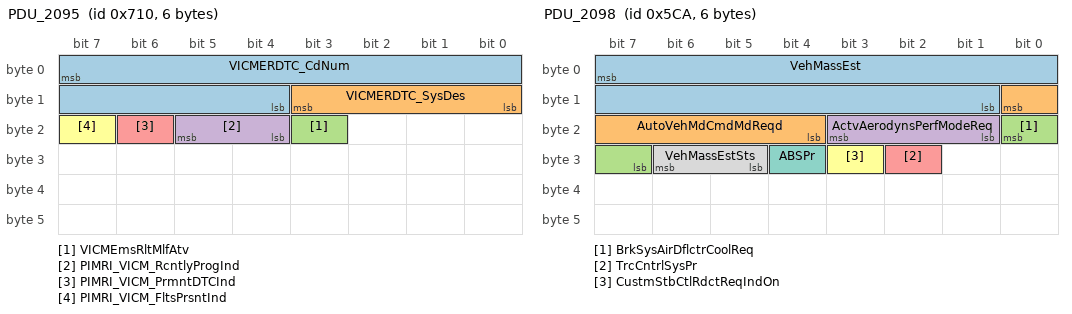
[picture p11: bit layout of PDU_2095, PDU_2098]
BO_ 1808 PDU_2095: 6 Vector__XXX
 SG_ VICMERDTC_CdNum : 7|12@0+ (1,0) [0|4095] "" ECP_E
 SG_ VICMERDTC_SysDes : 11|4@0+ (1,0) [0|15] "" ECP_E
 SG_ VICMEmsRltMlfAtv : 19|1@0+ (1,0) [0|1] "" ECP_E
 SG_ PIMRI_VICM_RcntlyProgInd : 21|2@0+ (1,0) [0|3] "" ECP_E
 SG_ PIMRI_VICM_PrmntDTCInd : 22|1@0+ (1,0) [0|1] "" ECP_E
 SG_ PIMRI_VICM_FltsPrsntInd : 23|1@0+ (1,0) [0|1] "" ECP_E

BO_ 1469 PDU_2097: 6 Vector__XXX
 SG_ SuprCruzSbscrptnActv : 7|1@0+ (1,0) [0|1] "" EOCM_HC_Superset

BO_ 1482 PDU_2098: 6 Vector__XXX
 SG_ VehMassEst : 7|15@0+ (1,0) [0|32767] "kg" CGM
 SG_ AutoVehMdCmdMdReqd : 8|5@0+ (1,0) [0|31] "" CGM
 SG_ BrkSysAirDflctrCoolReq : 16|2@0+ (1,0) [0|3] "" CGM
 SG_ ActvAerodynsPerfModeReq : 19|3@0+ (1,0) [0|7] "" CGM
 SG_ TrcCntrlSysPr : 26|1@0+ (1,0) [0|1] "" CGM,ECM,PCM,TCM
 SG_ CustmStbCtlRdctReqIndOn : 27|1@0+ (1,0) [0|1] "" CGM
 SG_ ABSPr : 28|1@0+ (1,0) [0|1] "" ACP2_MCU,CGM,ECM,EOCM,EOCM_HC_Superset,EPS,EPSb,FCM,PCM,ECP_E
 SG_ VehMassEstSts : 30|2@0+ (1,0) [0|2] "" CGM

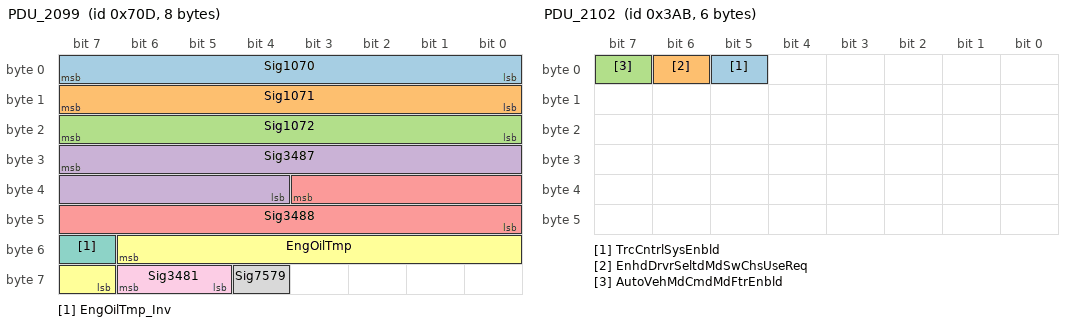
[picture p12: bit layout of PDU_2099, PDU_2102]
BO_ 1805 PDU_2099: 8 Vector__XXX
 SG_ Sig1070 : 7|8@0+ (1,0) [0|255] "km / h" CGM
 SG_ Sig1071 : 15|8@0+ (1,0) [0|255] "km / h" CGM
 SG_ Sig1072 : 23|8@0+ (1,0) [0|255] "km / h" CGM
 SG_ Sig3487 : 31|12@0+ (0.125,0) [0|511.875] "liters" CGM
 SG_ Sig3488 : 35|12@0+ (0.125,0) [0|511.875] "liters" CGM
 SG_ EngOilTmp : 54|8@0+ (1,-40) [-40|215] "deg C" CGM,EPS,EPSb,ECP_X1
 SG_ EngOilTmp_Inv : 55|1@0+ (1,0) [0|1] "" CGM,EPS,EPSb,ECP_X1
 SG_ Sig7579 : 60|1@0+ (1,0) [0|1] "" CGM
 SG_ Sig3481 : 62|2@0+ (1,0) [0|2] "" CGM

BO_ 1487 PDU_2100: 8 Vector__XXX
 SG_ Sig2442 : 3|4@0+ (1,0) [0|15] "" Vector__XXX
 SG_ Sig2441 : 7|4@0+ (1,0) [0|15] "" Vector__XXX
 SG_ Sig2447 : 11|4@0+ (1,0) [0|15] "" Vector__XXX
 SG_ Sig2443 : 15|4@0+ (1,0) [0|15] "" Vector__XXX
 SG_ Sig2450 : 23|15@0+ (2,0) [0|65534] "km" Vector__XXX
 SG_ Sig2451 : 24|1@0+ (1,0) [0|1] "" Vector__XXX
 SG_ Sig2453 : 35|15@0+ (2,0) [0|65534] "km" Vector__XXX
 SG_ Sig2452 : 39|4@0+ (1,0) [0|15] "" Vector__XXX
 SG_ Sig0309 : 48|1@0+ (1,0) [0|1] "" Vector__XXX
 SG_ Sig0308 : 49|1@0+ (1,0) [0|1] "" Vector__XXX
 SG_ Sig0307 : 50|1@0+ (1,0) [0|1] "" Vector__XXX
 SG_ Sig0306 : 51|1@0+ (1,0) [0|1] "" Vector__XXX
 SG_ Sig0305 : 52|1@0+ (1,0) [0|1] "" Vector__XXX
 SG_ Sig0626 : 58|1@0+ (1,0) [0|1] "" Vector__XXX
 SG_ Sig0614 : 59|1@0+ (1,0) [0|1] "" Vector__XXX
 SG_ Sig0434 : 60|1@0+ (1,0) [0|1] "" Vector__XXX
 SG_ Sig0312 : 61|1@0+ (1,0) [0|1] "" Vector__XXX
 SG_ Sig0311 : 62|1@0+ (1,0) [0|1] "" Vector__XXX
 SG_ Sig0310 : 63|1@0+ (1,0) [0|1] "" Vector__XXX

BO_ 1488 PDU_2101: 8 Vector__XXX
 SG_ Sig4815 : 3|4@0+ (1,0) [0|15] "" Vector__XXX
 SG_ Sig4610 : 7|4@0+ (1,0) [0|15] "" Vector__XXX
 SG_ Sig4250 : 8|3@0+ (1,0) [0|3] "" Vector__XXX
 SG_ Sig2586 : 11|3@0+ (1,0) [0|5] "" Vector__XXX
 SG_ Sig4838 : 15|4@0+ (1,0) [0|15] "" Vector__XXX
 SG_ Sig4885 : 18|3@0+ (1,0) [0|7] "" Vector__XXX
 SG_ Sig4863 : 21|3@0+ (1,0) [0|7] "" Vector__XXX
 SG_ Sig2621 : 24|1@0+ (1,0) [0|1] "" Vector__XXX
 SG_ Sig2620 : 25|1@0+ (1,0) [0|1] "" Vector__XXX
 SG_ Sig4689 : 27|2@0+ (1,0) [0|2] "" Vector__XXX
 SG_ Sig4638 : 29|2@0+ (1,0) [0|3] "" Vector__XXX
 SG_ Sig4627 : 31|2@0+ (1,0) [0|2] "" Vector__XXX
 SG_ Sig2671 : 32|1@0+ (1,0) [0|1] "" Vector__XXX
 SG_ Sig2668 : 33|1@0+ (1,0) [0|1] "" Vector__XXX
 SG_ Sig2667 : 34|1@0+ (1,0) [0|1] "" Vector__XXX
 SG_ Sig2644 : 35|1@0+ (1,0) [0|1] "" Vector__XXX
 SG_ Sig2641 : 36|1@0+ (1,0) [0|1] "" Vector__XXX
 SG_ Sig2639 : 37|1@0+ (1,0) [0|1] "" Vector__XXX
 SG_ Sig2637 : 38|1@0+ (1,0) [0|1] "" Vector__XXX
 SG_ Sig2636 : 39|1@0+ (1,0) [0|1] "" Vector__XXX
 SG_ Sig4675 : 40|1@0+ (1,0) [0|1] "" Vector__XXX
 SG_ Sig4636 : 41|1@0+ (1,0) [0|1] "" Vector__XXX
 SG_ Sig4629 : 42|1@0+ (1,0) [0|1] "" Vector__XXX
 SG_ Sig4612 : 43|1@0+ (1,0) [0|1] "" Vector__XXX
 SG_ Sig4539 : 44|1@0+ (1,0) [0|1] "" Vector__XXX
 SG_ Sig4496 : 45|1@0+ (1,0) [0|1] "" Vector__XXX
 SG_ Sig4481 : 46|1@0+ (1,0) [0|1] "" Vector__XXX
 SG_ Sig4479 : 47|1@0+ (1,0) [0|1] "" Vector__XXX
 SG_ Sig4840 : 48|1@0+ (1,0) [0|1] "" Vector__XXX
 SG_ Sig4817 : 49|1@0+ (1,0) [0|1] "" Vector__XXX
 SG_ Sig4798 : 50|1@0+ (1,0) [0|1] "" Vector__XXX
 SG_ Sig4730 : 51|1@0+ (1,0) [0|1] "" Vector__XXX
 SG_ Sig4728 : 52|1@0+ (1,0) [0|1] "" Vector__XXX
 SG_ Sig4726 : 53|1@0+ (1,0) [0|1] "" Vector__XXX
 SG_ Sig4712 : 54|1@0+ (1,0) [0|1] "" Vector__XXX
 SG_ Sig4691 : 55|1@0+ (1,0) [0|1] "" Vector__XXX
 SG_ Sig7799 : 57|1@0+ (1,0) [0|1] "" Vector__XXX
 SG_ Sig6769 : 58|1@0+ (1,0) [0|1] "" Vector__XXX
 SG_ Sig4906 : 59|1@0+ (1,0) [0|1] "" Vector__XXX
 SG_ Sig4893 : 60|1@0+ (1,0) [0|1] "" Vector__XXX
 SG_ Sig4887 : 61|1@0+ (1,0) [0|1] "" Vector__XXX
 SG_ Sig4865 : 62|1@0+ (1,0) [0|1] "" Vector__XXX
 SG_ Sig4846 : 63|1@0+ (1,0) [0|1] "" Vector__XXX

BO_ 939 PDU_2102: 6 Vector__XXX
 SG_ TrcCntrlSysEnbld : 5|1@0+ (1,0) [0|1] "" ECM,PCM,TCM,ECP_E,ECP_S,ECP_S2
 SG_ EnhdDrvrSeltdMdSwChsUseReq : 6|1@0+ (1,0) [0|1] "" Vector__XXX
 SG_ AutoVehMdCmdMdFtrEnbld : 7|1@0+ (1,0) [0|1] "" Vector__XXX

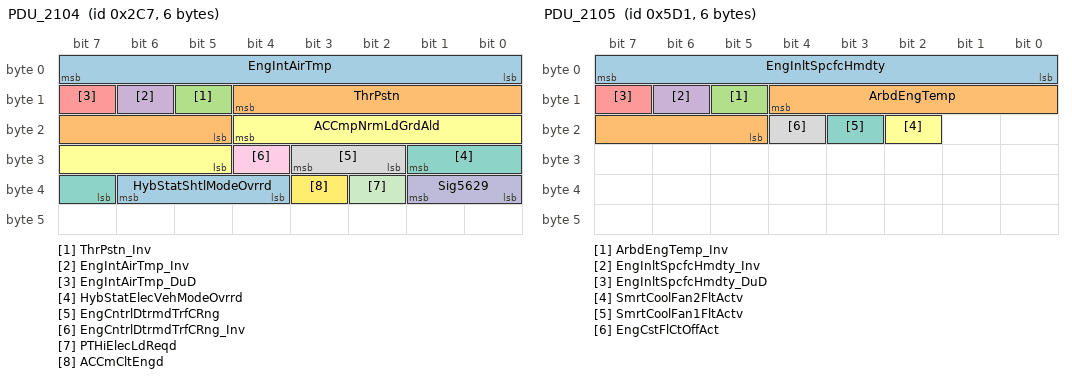
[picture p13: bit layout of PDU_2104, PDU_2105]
BO_ 711 PDU_2104: 6 Vector__XXX
 SG_ EngIntAirTmp : 7|8@0+ (1,-40) [-40|215] "deg C" ADIMa,ADIMb,BSM,VICM,CGM,EBCM,RDCM,TCCM,TCM,ECP_E
 SG_ ThrPstn : 12|8@0+ (0.392157,0) [0|100] "%" CGM,RDCM,TCCM
 SG_ ThrPstn_Inv : 13|1@0+ (1,0) [0|1] "" CGM,RDCM,TCCM
 SG_ EngIntAirTmp_Inv : 14|1@0+ (1,0) [0|1] "" ADIMa,ADIMb,BSM,VICM,CGM,EBCM,RDCM,TCCM,TCM,ECP_E
 SG_ EngIntAirTmp_DuD : 15|1@0+ (1,0) [0|1] "" BSM,VICM,CGM
 SG_ ACCmpNrmLdGrdAld : 20|8@0+ (0.1,0) [0|25.5] "dm3/m/s" CGM
 SG_ HybStatElecVehModeOvrrd : 25|3@0+ (1,0) [0|7] "" CGM
 SG_ EngCntrlDtrmdTrfCRng : 27|2@0+ (1,0) [0|3] "" CGM,TCM
 SG_ EngCntrlDtrmdTrfCRng_Inv : 28|1@0+ (1,0) [0|1] "" CGM,TCM
 SG_ Sig5629 : 33|2@0+ (1,0) [0|3] "" BSM
 SG_ PTHiElecLdReqd : 34|1@0+ (1,0) [0|1] "" CGM
 SG_ ACCmCltEngd : 35|1@0+ (1,0) [0|1] "" CGM,TCM
 SG_ HybStatShtlModeOvrrd : 38|3@0+ (1,0) [0|7] "" CGM

BO_ 1489 PDU_2105: 6 Vector__XXX
 SG_ EngInltSpcfcHmdty : 7|8@0+ (0.0196078,0) [0|4.99999] "% water" CGM,EBCM
 SG_ ArbdEngTemp : 12|8@0+ (1,-40) [-40|215] "deg C" ADIMa,ADIMb,BSM,VICM,CGM,EBCM,EPS,EPSb,TCM,ECP_E,ECP_X1
 SG_ ArbdEngTemp_Inv : 13|1@0+ (1,0) [0|1] "" ADIMa,ADIMb,BSM,VICM,CGM,EBCM,TCM,ECP_E,ECP_X1
 SG_ EngInltSpcfcHmdty_Inv : 14|1@0+ (1,0) [0|1] "" CGM,EBCM
 SG_ EngInltSpcfcHmdty_DuD : 15|1@0+ (1,0) [0|1] "" CGM
 SG_ SmrtCoolFan2FltActv : 18|1@0+ (1,0) [0|1] "" CGM
 SG_ SmrtCoolFan1FltActv : 19|1@0+ (1,0) [0|1] "" CGM
 SG_ EngCstFlCtOffAct : 20|1@0+ (1,0) [0|1] "" BSM,VICM,CGM,TCM

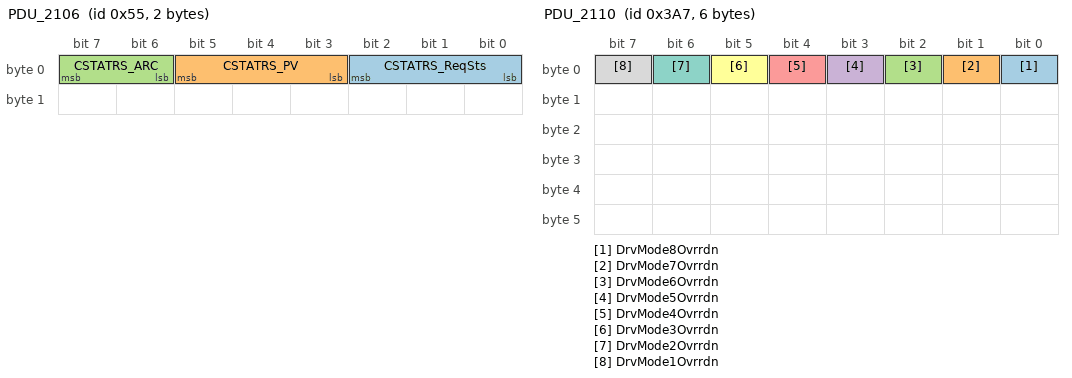
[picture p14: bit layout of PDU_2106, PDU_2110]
BO_ 85 PDU_2106: 2 Vector__XXX
 SG_ CSTATRS_ReqSts : 2|3@0+ (1,0) [0|6] "" EBCM
 SG_ CSTATRS_PV : 5|3@0+ (1,0) [0|7] "" EBCM
 SG_ CSTATRS_ARC : 7|2@0+ (1,0) [0|3] "" EBCM

BO_ 1260 PDU_2107: 6 Vector__XXX
 SG_ OTARC_RejCrdntnECP_X1 : 0|1@0+ (1,0) [0|1] "" BSM,VECM,VICM,BSM_MH,CGM,EBCM,ECP_MC,LIB1,PCM,TCM,ECP_S,ECP_S2,ECP_X1
 SG_ OTARC_RejCrdntnECP_S : 1|1@0+ (1,0) [0|1] "" BSM,VECM,VICM,BSM_MH,CGM,EBCM,ECP_MC,LIB1,PCM,TCM,ECP_S,ECP_S2,ECP_X1
 SG_ OTARC_RejCrdntnECP_MC : 2|1@0+ (1,0) [0|1] "" BSM,VECM,VICM,BSM_MH,CGM,EBCM,ECP_MC,LIB1,PCM,TCM,ECP_S,ECP_S2,ECP_X1
 SG_ OTARC_RejCrdntnECM : 3|1@0+ (1,0) [0|1] "" BSM,VECM,VICM,BSM_MH,CGM,EBCM,ECP_MC,LIB1,PCM,TCM,ECP_S,ECP_S2,ECP_X1
 SG_ OTARC_RejCrdntnEBCM : 4|1@0+ (1,0) [0|1] "" BSM,VECM,VICM,BSM_MH,CGM,EBCM,ECP_MC,LIB1,PCM,TCM,ECP_S,ECP_S2,ECP_X1
 SG_ OTARC_RejCrdntnBSM_MH : 5|1@0+ (1,0) [0|1] "" BSM,VECM,VICM,BSM_MH,CGM,EBCM,ECP_MC,LIB1,PCM,TCM,ECP_S,ECP_S2,ECP_X1
 SG_ OTARC_RejCrdntnBSM : 6|1@0+ (1,0) [0|1] "" BSM,VECM,VICM,BSM_MH,CGM,EBCM,ECP_MC,LIB1,PCM,TCM,ECP_S,ECP_S2,ECP_X1
 SG_ OTARC_RejCrdntnBCM : 7|1@0+ (1,0) [0|1] "" BSM,VECM,VICM,BSM_MH,CGM,EBCM,ECP_MC,LIB1,PCM,TCM,ECP_S,ECP_S2,ECP_X1
 SG_ OTARC_RejCrdntnECU_19 : 8|1@0+ (1,0) [0|1] "" BSM,VECM,VICM,BSM_MH,CGM,EBCM,ECP_MC,LIB1,PCM,TCM,ECP_S,ECP_S2,ECP_X1
 SG_ OTARC_RejCrdntnECU_18 : 9|1@0+ (1,0) [0|1] "" BSM,VECM,VICM,BSM_MH,CGM,EBCM,ECP_MC,LIB1,PCM,TCM,ECP_S,ECP_S2,ECP_X1
 SG_ OTARC_RejCrdntnECU_17 : 10|1@0+ (1,0) [0|1] "" BSM,VECM,VICM,BSM_MH,CGM,EBCM,ECP_MC,LIB1,PCM,TCM,ECP_S,ECP_S2,ECP_X1
 SG_ OTARC_RejCrdntnECU_16 : 11|1@0+ (1,0) [0|1] "" BSM,VECM,VICM,BSM_MH,CGM,EBCM,ECP_MC,LIB1,PCM,TCM,ECP_S,ECP_S2,ECP_X1
 SG_ OTARC_RejCrdntnECU_15 : 12|1@0+ (1,0) [0|1] "" BSM,VECM,VICM,BSM_MH,CGM,EBCM,ECP_MC,LIB1,PCM,TCM,ECP_S,ECP_S2,ECP_X1
 SG_ OTARC_RejCrdntnSBM : 13|1@0+ (1,0) [0|1] "" BSM,VECM,VICM,BSM_MH,CGM,EBCM,ECP_MC,LIB1,PCM,TCM,ECP_S,ECP_S2,ECP_X1
 SG_ OTARC_RejCrdntnCGM : 14|1@0+ (1,0) [0|1] "" BSM,VECM,VICM,BSM_MH,CGM,EBCM,ECP_MC,LIB1,PCM,TCM,ECP_S,ECP_S2,ECP_X1
 SG_ OTARC_RejCrdntnECP_X2 : 15|1@0+ (1,0) [0|1] "" BSM,VECM,VICM,BSM_MH,CGM,EBCM,ECP_MC,LIB1,PCM,TCM,ECP_S,ECP_S2,ECP_X1
 SG_ OTARC_RejCrdntnECU_27 : 16|1@0+ (1,0) [0|1] "" BSM,VECM,VICM,BSM_MH,CGM,EBCM,ECP_MC,LIB1,PCM,TCM,ECP_S,ECP_S2,ECP_X1
 SG_ OTARC_RejCrdntnECU_26 : 17|1@0+ (1,0) [0|1] "" BSM,VECM,VICM,BSM_MH,CGM,EBCM,ECP_MC,LIB1,PCM,TCM,ECP_S,ECP_S2,ECP_X1
 SG_ OTARC_RejCrdntnECU_25 : 18|1@0+ (1,0) [0|1] "" BSM,VECM,VICM,BSM_MH,CGM,EBCM,ECP_MC,LIB1,PCM,TCM,ECP_S,ECP_S2,ECP_X1
 SG_ OTARC_RejCrdntnECU_24 : 19|1@0+ (1,0) [0|1] "" BSM,VECM,VICM,BSM_MH,CGM,EBCM,ECP_MC,LIB1,PCM,TCM,ECP_S,ECP_S2,ECP_X1
 SG_ OTARC_RejCrdntnECU_23 : 20|1@0+ (1,0) [0|1] "" BSM,VECM,VICM,BSM_MH,CGM,EBCM,ECP_MC,LIB1,PCM,TCM,ECP_S,ECP_S2,ECP_X1
 SG_ OTARC_RejCrdntnECU_22 : 21|1@0+ (1,0) [0|1] "" BSM,VECM,VICM,BSM_MH,CGM,EBCM,ECP_MC,LIB1,PCM,TCM,ECP_S,ECP_S2,ECP_X1
 SG_ OTARC_RejCrdntnECU_21 : 22|1@0+ (1,0) [0|1] "" BSM,VECM,VICM,BSM_MH,CGM,EBCM,ECP_MC,LIB1,PCM,TCM,ECP_S,ECP_S2,ECP_X1
 SG_ OTARC_RejCrdntnECU_20 : 23|1@0+ (1,0) [0|1] "" BSM,VECM,VICM,BSM_MH,CGM,EBCM,ECP_MC,LIB1,PCM,TCM,ECP_S,ECP_S2,ECP_X1
 SG_ OTARC_RejCrdntnTCM : 24|1@0+ (1,0) [0|1] "" BSM,VECM,VICM,BSM_MH,CGM,EBCM,ECP_MC,LIB1,PCM,TCM,ECP_S,ECP_S2,ECP_X1
 SG_ OTARC_RejCrdntnICCM : 25|1@0+ (1,0) [0|1] "" BSM,VECM,VICM,BSM_MH,CGM,EBCM,ECP_MC,LIB1,PCM,TCM,ECP_S,ECP_S2,ECP_X1
 SG_ OTARC_RejCrdntnFICM : 26|1@0+ (1,0) [0|1] "" BSM,VECM,VICM,BSM_MH,CGM,EBCM,ECP_MC,LIB1,PCM,TCM,ECP_S,ECP_S2,ECP_X1
 SG_ OTARC_RejCrdntnECU_32 : 27|1@0+ (1,0) [0|1] "" BSM,VECM,VICM,BSM_MH,CGM,EBCM,ECP_MC,LIB1,PCM,TCM,ECP_S,ECP_S2,ECP_X1
 SG_ OTARC_RejCrdntnECU_31 : 28|1@0+ (1,0) [0|1] "" BSM,VECM,VICM,BSM_MH,CGM,EBCM,ECP_MC,LIB1,PCM,TCM,ECP_S,ECP_S2,ECP_X1
 SG_ OTARC_RejCrdntnECU_30 : 29|1@0+ (1,0) [0|1] "" BSM,VECM,VICM,BSM_MH,CGM,EBCM,ECP_MC,LIB1,PCM,TCM,ECP_S,ECP_S2,ECP_X1
 SG_ OTARC_RejCrdntnECU_29 : 30|1@0+ (1,0) [0|1] "" BSM,VECM,VICM,BSM_MH,CGM,EBCM,ECP_MC,LIB1,PCM,TCM,ECP_S,ECP_S2,ECP_X1
 SG_ OTARC_RejCrdntnECU_28 : 31|1@0+ (1,0) [0|1] "" BSM,VECM,VICM,BSM_MH,CGM,EBCM,ECP_MC,LIB1,PCM,TCM,ECP_S,ECP_S2,ECP_X1

BO_ 1806 PDU_2108: 6 Vector__XXX
 SG_ DTCClrInhbd : 7|1@0+ (1,0) [0|1] "" BSM,VECM,VICM,BSM_MH,CGM,EBCM,ECP_MC,LIB1,PCM,TCM,ECP_S,ECP_S2,ECP_X1

BO_ 56 PDU_2109: 2 Vector__XXX
 SG_ PwrtrnShfLvrLckReqd : 7|1@0+ (1,0) [0|1] "" Vector__XXX

BO_ 935 PDU_2110: 6 Vector__XXX
 SG_ DrvMode8Ovrrdn : 0|1@0+ (1,0) [0|1] "" EBCM
 SG_ DrvMode7Ovrrdn : 1|1@0+ (1,0) [0|1] "" EBCM
 SG_ DrvMode6Ovrrdn : 2|1@0+ (1,0) [0|1] "" EBCM
 SG_ DrvMode5Ovrrdn : 3|1@0+ (1,0) [0|1] "" EBCM
 SG_ DrvMode4Ovrrdn : 4|1@0+ (1,0) [0|1] "" EBCM
 SG_ DrvMode3Ovrrdn : 5|1@0+ (1,0) [0|1] "" EBCM
 SG_ DrvMode2Ovrrdn : 6|1@0+ (1,0) [0|1] "" EBCM
 SG_ DrvMode1Ovrrdn : 7|1@0+ (1,0) [0|1] "" EBCM

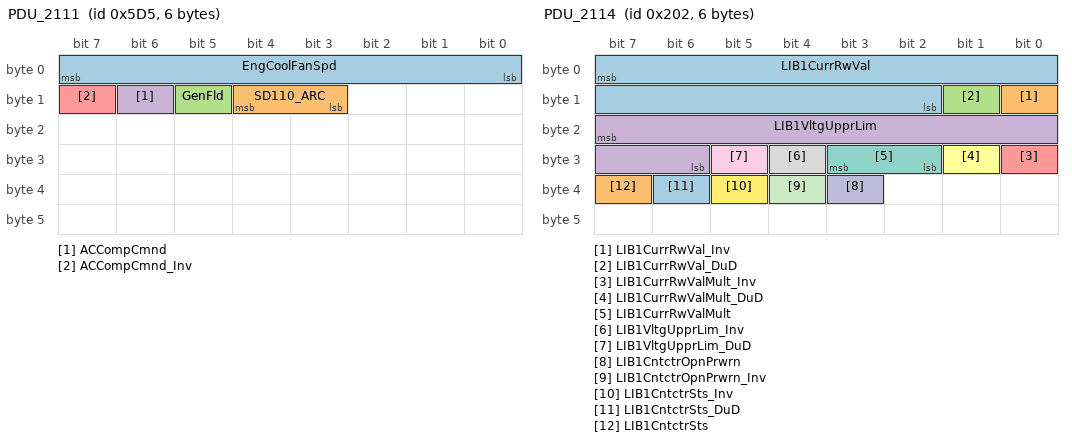
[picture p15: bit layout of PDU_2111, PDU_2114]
BO_ 1493 PDU_2111: 6 Vector__XXX
 SG_ EngCoolFanSpd : 7|8@0+ (0.392157,0) [0|100] "%" BSM,CGM
 SG_ SD110_ARC : 12|2@0+ (1,0) [0|3] "" BSM
 SG_ GenFld : 13|1@0+ (1,0) [0|1] "" CGM
 SG_ ACCompCmnd : 14|1@0+ (1,0) [0|1] "" BSM,CGM,PCM,TCM,VDM
 SG_ ACCompCmnd_Inv : 15|1@0+ (1,0) [0|1] "" BSM,VDM

BO_ 514 PDU_2114: 6 Vector__XXX
 SG_ LIB1CurrRwVal : 7|14@0+ (0.001,-8.192) [-8.192|8.191] "Amps" ECM,FOPM,PCM
 SG_ LIB1CurrRwVal_Inv : 8|1@0+ (1,0) [0|1] "" ECM,FOPM,PCM
 SG_ LIB1CurrRwVal_DuD : 9|1@0+ (1,0) [0|1] "" ECM,PCM
 SG_ LIB1VltgUpprLim : 23|10@0+ (0.01,10) [10|20.23] "Volts" FOPM
 SG_ LIB1CurrRwValMult_Inv : 24|1@0+ (1,0) [0|1] "" ECM,FOPM,PCM
 SG_ LIB1CurrRwValMult_DuD : 25|1@0+ (1,0) [0|1] "" ECM,PCM
 SG_ LIB1CurrRwValMult : 27|2@0+ (1,0) [0|3] "" ECM,FOPM,PCM
 SG_ LIB1VltgUpprLim_Inv : 28|1@0+ (1,0) [0|1] "" FOPM
 SG_ LIB1VltgUpprLim_DuD : 29|1@0+ (1,0) [0|1] "" Vector__XXX
 SG_ LIB1CntctrOpnPrwrn : 35|1@0+ (1,0) [0|1] "" Vector__XXX
 SG_ LIB1CntctrOpnPrwrn_Inv : 36|1@0+ (1,0) [0|1] "" Vector__XXX
 SG_ LIB1CntctrSts_Inv : 37|1@0+ (1,0) [0|1] "" ECM,FOPM,PCM
 SG_ LIB1CntctrSts_DuD : 38|1@0+ (1,0) [0|1] "" ECM,PCM
 SG_ LIB1CntctrSts : 39|1@0+ (1,0) [0|1] "" ECM,FOPM,PCM

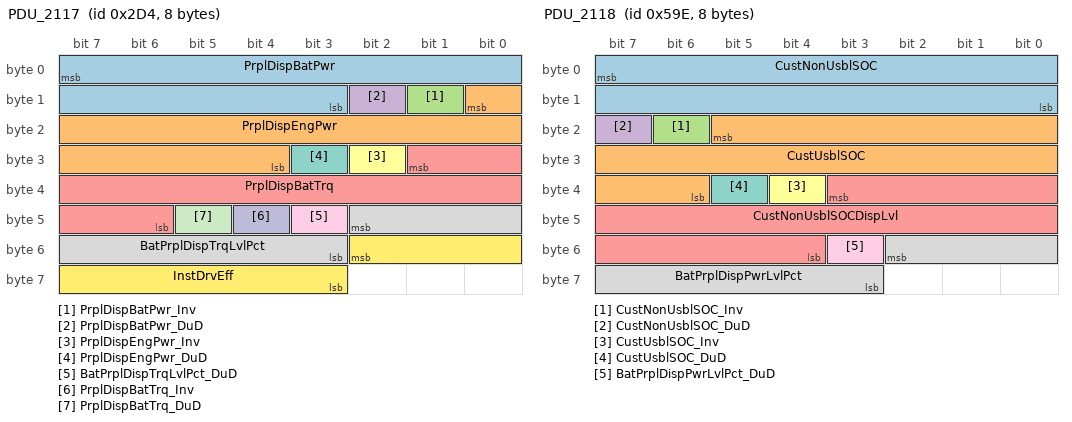
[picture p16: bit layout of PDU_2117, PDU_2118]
BO_ 724 PDU_2117: 8 Vector__XXX
 SG_ PrplDispBatPwr : 7|13@0+ (0.5,-1000) [-1000|3095.5] "" Vector__XXX
 SG_ PrplDispEngPwr : 8|13@0+ (0.5,-325) [-325|3770.5] "" Vector__XXX
 SG_ PrplDispBatPwr_Inv : 9|1@0+ (1,0) [0|1] "" Vector__XXX
 SG_ PrplDispBatPwr_DuD : 10|1@0+ (1,0) [0|1] "" Vector__XXX
 SG_ PrplDispBatTrq : 25|12@0+ (0.5,-848) [-848|1199.5] "Nm" Vector__XXX
 SG_ PrplDispEngPwr_Inv : 26|1@0+ (1,0) [0|1] "" Vector__XXX
 SG_ PrplDispEngPwr_DuD : 27|1@0+ (1,0) [0|1] "" Vector__XXX
 SG_ BatPrplDispTrqLvlPct : 42|8@0- (1,0) [-128|127] "%" Vector__XXX
 SG_ BatPrplDispTrqLvlPct_DuD : 43|1@0+ (1,0) [0|1] "" Vector__XXX
 SG_ PrplDispBatTrq_Inv : 44|1@0+ (1,0) [0|1] "" Vector__XXX
 SG_ PrplDispBatTrq_DuD : 45|1@0+ (1,0) [0|1] "" Vector__XXX
 SG_ InstDrvEff : 50|8@0- (0.78125,0) [-100|99.2188] "%" Vector__XXX

BO_ 1438 PDU_2118: 8 Vector__XXX
 SG_ CustNonUsblSOC : 7|16@0+ (0.00152588,0) [0|99.9985] "%" CGM
 SG_ CustUsblSOC : 21|16@0+ (0.00152588,0) [0|99.9985] "%" ADIMa,ADIMb,CGM,VDM
 SG_ CustNonUsblSOC_Inv : 22|1@0+ (1,0) [0|1] "" CGM
 SG_ CustNonUsblSOC_DuD : 23|1@0+ (1,0) [0|1] "" CGM
 SG_ CustNonUsblSOCDispLvl : 35|16@0+ (0.00152588,0) [0|99.9985] "%" CGM
 SG_ CustUsblSOC_Inv : 36|1@0+ (1,0) [0|1] "" ADIMa,ADIMb,CGM,VDM
 SG_ CustUsblSOC_DuD : 37|1@0+ (1,0) [0|1] "" ADIMa,ADIMb,CGM
 SG_ BatPrplDispPwrLvlPct : 50|8@0- (1,0) [-128|127] "%" CGM
 SG_ BatPrplDispPwrLvlPct_DuD : 51|1@0+ (1,0) [0|1] "" CGM

BO_ 1423 PDU_2119: 8 Vector__XXX
 SG_ EAWDMPTR_Secs : 0|6@0+ (1,0) [0|63] "seconds" Vector__XXX
 SG_ EAWDMPTR_Mins : 7|7@0+ (1,0) [0|127] "minutes" Vector__XXX
 SG_ ElecMtrATach : 10|9@0- (100,0) [-25600|25500] "rpm" Vector__XXX
 SG_ ElecMtrATach_Inv : 16|1@0+ (1,0) [0|1] "" Vector__XXX
 SG_ ElecMtrATach_DuD : 17|1@0+ (1,0) [0|1] "" Vector__XXX
 SG_ HiVltgBatAvgTemp_DuD : 24|1@0+ (1,0) [0|1] "" ECP_E,ECP_S,ECP_X1
 SG_ HiVltgBatAvgTemp : 31|7@0+ (1,-40) [-40|87] "deg C" ECP_E,ECP_S,ECP_X1
 SG_ DischrgPwrLtdDispPct : 38|8@0- (1,0) [-128|127] "%" Vector__XXX
 SG_ HiVltgBatAvgTemp_Inv : 39|1@0+ (1,0) [0|1] "" ECP_E,ECP_S,ECP_X1
 SG_ EngPrplDispPwrLvlPct : 45|7@0+ (1,0) [0|127] "%" Vector__XXX
 SG_ EngPrplDispPwrLvlPct_DuD : 46|1@0+ (1,0) [0|1] "" Vector__XXX
 SG_ EstdEleclPrplCpblty : 54|7@0+ (1,0) [0|127] "%" Vector__XXX
 SG_ EngRnngDueToVehSpdIndOn : 58|1@0+ (1,0) [0|1] "" Vector__XXX
 SG_ ElecAllWhlDrvIndOn : 59|1@0+ (1,0) [0|1] "" Vector__XXX
 SG_ DischrgPwrLtdIndOn : 60|1@0+ (1,0) [0|1] "" Vector__XXX
 SG_ DischrgPwrLtdDispPctVsbl : 61|1@0+ (1,0) [0|1] "" Vector__XXX
 SG_ HiVltgBatLmtnDueToTempInd : 63|2@0+ (1,0) [0|2] "" Vector__XXX

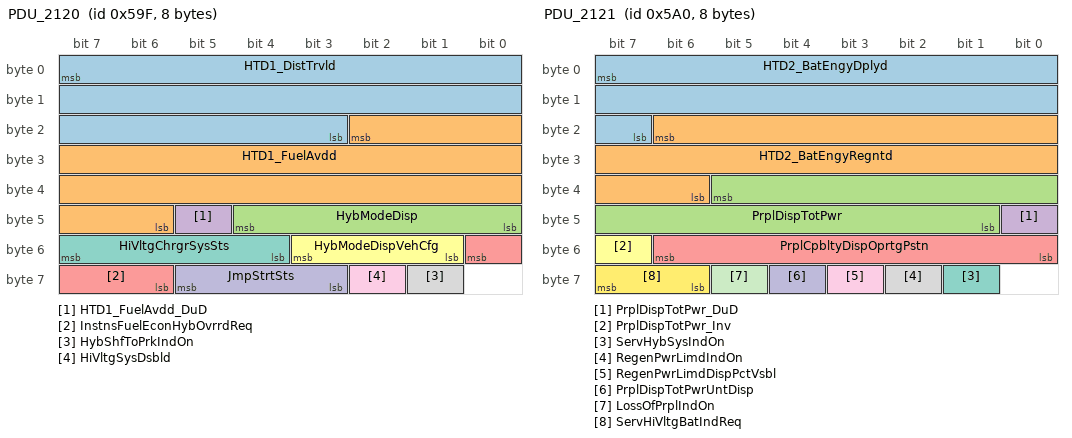
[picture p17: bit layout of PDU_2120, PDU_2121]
BO_ 1439 PDU_2120: 8 Vector__XXX
 SG_ HTD1_DistTrvld : 7|21@0+ (0.1,0) [0|209715] "Km" CGM
 SG_ HTD1_FuelAvdd : 18|21@0+ (0.0378541,0) [0|79385.8] "liters" CGM
 SG_ HybModeDisp : 44|5@0+ (1,0) [0|16] "" CGM
 SG_ HTD1_FuelAvdd_DuD : 45|1@0+ (1,0) [0|1] "" CGM
 SG_ InstnsFuelEconHybOvrrdReq : 48|3@0+ (1,0) [0|4] "" CGM
 SG_ HybModeDispVehCfg : 51|3@0+ (1,0) [0|4] "" CGM
 SG_ HiVltgChrgrSysSts : 55|4@0+ (1,0) [0|11] "" CGM,VDM
 SG_ HybShfToPrkIndOn : 57|1@0+ (1,0) [0|1] "" CGM
 SG_ HiVltgSysDsbld : 58|1@0+ (1,0) [0|1] "" CGM
 SG_ JmpStrtSts : 61|3@0+ (1,0) [0|4] "" CGM

BO_ 1440 PDU_2121: 8 Vector__XXX
 SG_ HTD2_BatEngyDplyd : 7|17@0+ (0.1,0) [0|13107.1] "kWh" Vector__XXX
 SG_ HTD2_BatEngyRegntd : 22|17@0+ (0.1,0) [0|13107.1] "kWh" Vector__XXX
 SG_ PrplDispTotPwr : 37|13@0+ (0.5,-1000) [-1000|3095.5] "" Vector__XXX
 SG_ PrplDispTotPwr_DuD : 40|1@0+ (1,0) [0|1] "" Vector__XXX
 SG_ PrplCpbltyDispOprtgPstn : 54|7@0+ (1,0) [0|127] "%" Vector__XXX
 SG_ PrplDispTotPwr_Inv : 55|1@0+ (1,0) [0|1] "" Vector__XXX
 SG_ ServHybSysIndOn : 57|1@0+ (1,0) [0|1] "" VDM
 SG_ RegenPwrLimdIndOn : 58|1@0+ (1,0) [0|1] "" Vector__XXX
 SG_ RegenPwrLimdDispPctVsbl : 59|1@0+ (1,0) [0|1] "" Vector__XXX
 SG_ PrplDispTotPwrUntDisp : 60|1@0+ (1,0) [0|1] "" Vector__XXX
 SG_ LossOfPrplIndOn : 61|1@0+ (1,0) [0|1] "" Vector__XXX
 SG_ ServHiVltgBatIndReq : 63|2@0+ (1,0) [0|2] "" Vector__XXX

BO_ 1483 PDU_2124: 8 Vector__XXX
 SG_ BrkPadLifeFrtDistRmn : 7|8@0+ (100,0) [0|25500] "counts" Vector__XXX
 SG_ BrkPadLifeRrDistRmn : 13|8@0+ (100,0) [0|25500] "counts" Vector__XXX
 SG_ BrkPadLifeFrtDistWrnIndReq : 15|2@0+ (1,0) [0|2] "" Vector__XXX
 SG_ ESCSpdLtdCntdwnVal : 16|6@0+ (1,0) [0|63] "Trips" Vector__XXX
 SG_ BrkPadLifeStsIndReq : 19|3@0+ (1,0) [0|6] "" Vector__XXX
 SG_ BrkPadLifeRrDistWrnIndReq : 21|2@0+ (1,0) [0|2] "" Vector__XXX
 SG_ ESCVehTopSpdLimDispVal : 24|7@0+ (1,0) [0|127] "kph" Vector__XXX
 SG_ ESCSpdLtdIndReq : 26|2@0+ (1,0) [0|2] "" Vector__XXX
 SG_ HillDscntCtlRdcVehSpdIndOn : 32|1@0+ (1,0) [0|1] "" Vector__XXX
 SG_ HillDscntCtlDispActvIndOn : 33|1@0+ (1,0) [0|1] "" Vector__XXX
 SG_ HillDscntCtlTgtSetSpd : 47|10@0+ (0.1,0) [0|102.3] "km/h" Vector__XXX
 SG_ BrkPadLifeFrtCnfrmRplcmtIndOn : 48|1@0+ (1,0) [0|1] "" Vector__XXX
 SG_ BrkOvrhtdIndOn : 49|1@0+ (1,0) [0|1] "" Vector__XXX
 SG_ AllWhlDrvRcmndIndOn : 50|1@0+ (1,0) [0|1] "" Vector__XXX
 SG_ CrwlModeDndRsnIndReq : 53|3@0+ (1,0) [0|4] "" Vector__XXX
 SG_ BrksOvrht : 59|1@0+ (1,0) [0|1] "" ACP2_MCU,EOCM,EOCM_HC_Superset,FCM
 SG_ BrkSysTwoFtdDrvDtdIndOn : 60|1@0+ (1,0) [0|1] "" Vector__XXX
 SG_ BrkSysHillStrtAsstAvl : 61|1@0+ (1,0) [0|1] "" PCM,TCM
 SG_ BrkPadWrnIO : 62|1@0+ (1,0) [0|1] "" Vector__XXX
 SG_ BrkPadLifeRrCnfrmRplcmtIndOn : 63|1@0+ (1,0) [0|1] "" Vector__XXX

BA_DEF_ SG_  "SignalType" STRING ;
BA_DEF_ SG_  "SignalLongName" STRING ;
BA_DEF_ BO_  "GenMsgCycleTime" INT 0 10000;
BA_DEF_ BO_  "GenMsgSendType" ENUM "cyclicX","spontanX","cyclicIfActiveX","spontanWithDelay","cyclicAndSpontanX","cyclicAndSpontanWithDelay","spontanWithRepetition","cyclicIfActiveAndSpontanWD";
BA_DEF_ BO_  "VFrameFormat" ENUM  "StandardCAN","ExtendedCAN","reserved","reserved","reserved","reserved","reserved","reserved","reserved","reserved","reserved","reserved","reserved","reserved","StandardCAN_FD","ExtendedCAN_FD";
BA_DEF_DEF_  "SignalType" "";
BA_DEF_DEF_  "SignalLongName" "";
BA_DEF_DEF_  "GenMsgCycleTime" 0;
BA_DEF_DEF_  "GenMsgSendType" "cyclicX";
BA_DEF_DEF_  "VFrameFormat" "StandardCAN";
BA_ "GenMsgCycleTime" BO_ 710 100;
BA_ "VFrameFormat" BO_ 710 14;
BA_ "GenMsgCycleTime" BO_ 948 500;
BA_ "VFrameFormat" BO_ 948 14;
BA_ "GenMsgCycleTime" BO_ 1486 1000;
BA_ "VFrameFormat" BO_ 1486 14;
BA_ "GenMsgCycleTime" BO_ 1801 1000;
BA_ "VFrameFormat" BO_ 1801 14;
BA_ "GenMsgCycleTime" BO_ 63 12.5;
BA_ "VFrameFormat" BO_ 63 14;
BA_ "GenMsgCycleTime" BO_ 934 250;
BA_ "VFrameFormat" BO_ 934 14;
BA_ "GenMsgCycleTime" BO_ 1490 1000;
BA_ "VFrameFormat" BO_ 1490 14;
BA_ "GenMsgCycleTime" BO_ 1264 1000;
BA_ "VFrameFormat" BO_ 1264 14;
BA_ "GenMsgCycleTime" BO_ 52 12.5;
BA_ "VFrameFormat" BO_ 52 14;
BA_ "GenMsgCycleTime" BO_ 1491 1000;
BA_ "VFrameFormat" BO_ 1491 14;
BA_ "GenMsgCycleTime" BO_ 99 12.5;
BA_ "VFrameFormat" BO_ 99 14;
BA_ "GenMsgCycleTime" BO_ 203 25;
BA_ "VFrameFormat" BO_ 203 14;
BA_ "GenMsgCycleTime" BO_ 936 250;
BA_ "VFrameFormat" BO_ 936 14;
BA_ "GenMsgCycleTime" BO_ 714 100;
BA_ "VFrameFormat" BO_ 714 14;
BA_ "GenMsgCycleTime" BO_ 1492 1000;
BA_ "VFrameFormat" BO_ 1492 14;
BA_ "GenMsgCycleTime" BO_ 1802 1000;
BA_ "VFrameFormat" BO_ 1802 14;
BA_ "GenMsgCycleTime" BO_ 1494 1000;
BA_ "VFrameFormat" BO_ 1494 14;
BA_ "GenMsgCycleTime" BO_ 1803 1000;
BA_ "VFrameFormat" BO_ 1803 14;
BA_ "GenMsgCycleTime" BO_ 42 12.5;
BA_ "VFrameFormat" BO_ 42 14;
BA_ "GenMsgCycleTime" BO_ 732 100;
BA_ "VFrameFormat" BO_ 732 14;
BA_ "GenMsgCycleTime" BO_ 43 12.5;
BA_ "VFrameFormat" BO_ 43 14;
BA_ "GenMsgCycleTime" BO_ 1263 1000;
BA_ "VFrameFormat" BO_ 1263 14;
BA_ "GenMsgCycleTime" BO_ 113 20;
BA_ "VFrameFormat" BO_ 113 14;
BA_ "GenMsgCycleTime" BO_ 733 100;
BA_ "VFrameFormat" BO_ 733 14;
BA_ "GenMsgCycleTime" BO_ 1495 1000;
BA_ "VFrameFormat" BO_ 1495 14;
BA_ "GenMsgCycleTime" BO_ 1262 1000;
BA_ "VFrameFormat" BO_ 1262 14;
BA_ "GenMsgCycleTime" BO_ 41 12.5;
BA_ "VFrameFormat" BO_ 41 14;
BA_ "GenMsgCycleTime" BO_ 1804 1000;
BA_ "VFrameFormat" BO_ 1804 14;
BA_ "GenMsgCycleTime" BO_ 512 25;
BA_ "VFrameFormat" BO_ 512 14;
BA_ "GenMsgCycleTime" BO_ 734 100;
BA_ "VFrameFormat" BO_ 734 14;
BA_ "GenMsgCycleTime" BO_ 1497 1000;
BA_ "VFrameFormat" BO_ 1497 14;
BA_ "GenMsgCycleTime" BO_ 1415 1000;
BA_ "VFrameFormat" BO_ 1415 14;
BA_ "GenMsgCycleTime" BO_ 1431 1000;
BA_ "VFrameFormat" BO_ 1431 14;
BA_ "GenMsgCycleTime" BO_ 1499 1000;
BA_ "VFrameFormat" BO_ 1499 14;
BA_ "GenMsgCycleTime" BO_ 181 50;
BA_ "VFrameFormat" BO_ 181 14;
BA_ "GenMsgCycleTime" BO_ 1416 1000;
BA_ "VFrameFormat" BO_ 1416 14;
BA_ "GenMsgCycleTime" BO_ 1500 1000;
BA_ "VFrameFormat" BO_ 1500 14;
BA_ "GenMsgCycleTime" BO_ 941 250;
BA_ "VFrameFormat" BO_ 941 14;
BA_ "GenMsgCycleTime" BO_ 1261 1000;
BA_ "VFrameFormat" BO_ 1261 14;
BA_ "GenMsgCycleTime" BO_ 1418 1000;
BA_ "VFrameFormat" BO_ 1418 14;
BA_ "GenMsgCycleTime" BO_ 735 100;
BA_ "VFrameFormat" BO_ 735 14;
BA_ "GenMsgCycleTime" BO_ 663 100;
BA_ "VFrameFormat" BO_ 663 14;
BA_ "GenMsgCycleTime" BO_ 1807 1000;
BA_ "VFrameFormat" BO_ 1807 14;
BA_ "GenMsgCycleTime" BO_ 1433 1000;
BA_ "VFrameFormat" BO_ 1433 14;
BA_ "GenMsgCycleTime" BO_ 1434 1000;
BA_ "VFrameFormat" BO_ 1434 14;
BA_ "GenMsgCycleTime" BO_ 1502 1000;
BA_ "VFrameFormat" BO_ 1502 14;
BA_ "GenMsgCycleTime" BO_ 111 12.5;
BA_ "VFrameFormat" BO_ 111 14;
BA_ "GenMsgCycleTime" BO_ 196 25;
BA_ "VFrameFormat" BO_ 196 14;
BA_ "GenMsgCycleTime" BO_ 719 100;
BA_ "VFrameFormat" BO_ 719 14;
BA_ "GenMsgCycleTime" BO_ 937 250;
BA_ "VFrameFormat" BO_ 937 14;
BA_ "GenMsgCycleTime" BO_ 1256 1000;
BA_ "VFrameFormat" BO_ 1256 14;
BA_ "GenMsgCycleTime" BO_ 1258 1000;
BA_ "VFrameFormat" BO_ 1258 14;
BA_ "GenMsgCycleTime" BO_ 737 100;
BA_ "VFrameFormat" BO_ 737 14;
BA_ "GenMsgCycleTime" BO_ 1808 1000;
BA_ "VFrameFormat" BO_ 1808 14;
BA_ "GenMsgCycleTime" BO_ 1469 1000;
BA_ "VFrameFormat" BO_ 1469 14;
BA_ "GenMsgCycleTime" BO_ 1482 1000;
BA_ "VFrameFormat" BO_ 1482 14;
BA_ "GenMsgCycleTime" BO_ 1805 1000;
BA_ "VFrameFormat" BO_ 1805 14;
BA_ "GenMsgCycleTime" BO_ 1487 1000;
BA_ "VFrameFormat" BO_ 1487 14;
BA_ "GenMsgCycleTime" BO_ 1488 1000;
BA_ "VFrameFormat" BO_ 1488 14;
BA_ "GenMsgCycleTime" BO_ 939 250;
BA_ "VFrameFormat" BO_ 939 14;
BA_ "GenMsgCycleTime" BO_ 711 100;
BA_ "VFrameFormat" BO_ 711 14;
BA_ "GenMsgCycleTime" BO_ 1489 1000;
BA_ "VFrameFormat" BO_ 1489 14;
BA_ "GenMsgCycleTime" BO_ 85 12.5;
BA_ "VFrameFormat" BO_ 85 14;
BA_ "GenMsgCycleTime" BO_ 1260 1000;
BA_ "VFrameFormat" BO_ 1260 14;
BA_ "GenMsgCycleTime" BO_ 1806 1000;
BA_ "VFrameFormat" BO_ 1806 14;
BA_ "GenMsgCycleTime" BO_ 56 12.5;
BA_ "VFrameFormat" BO_ 56 14;
BA_ "GenMsgCycleTime" BO_ 935 250;
BA_ "VFrameFormat" BO_ 935 14;
BA_ "GenMsgCycleTime" BO_ 1493 1000;
BA_ "VFrameFormat" BO_ 1493 14;
BA_ "GenMsgCycleTime" BO_ 514 25;
BA_ "VFrameFormat" BO_ 514 14;
BA_ "GenMsgCycleTime" BO_ 724 100;
BA_ "VFrameFormat" BO_ 724 14;
BA_ "GenMsgCycleTime" BO_ 1438 1000;
BA_ "VFrameFormat" BO_ 1438 14;
BA_ "GenMsgCycleTime" BO_ 1423 1000;
BA_ "VFrameFormat" BO_ 1423 14;
BA_ "GenMsgCycleTime" BO_ 1439 1000;
BA_ "VFrameFormat" BO_ 1439 14;
BA_ "GenMsgCycleTime" BO_ 1440 1000;
BA_ "VFrameFormat" BO_ 1440 14;
BA_ "GenMsgCycleTime" BO_ 1483 1000;
BA_ "VFrameFormat" BO_ 1483 14;
BA_ "SignalLongName" SG_ 710 Sig4474 "Signal5069";
BA_ "SignalType" SG_ 710 Sig4473 "ENM";
BA_ "SignalLongName" SG_ 710 Sig4473 "Signal5068";
BA_ "SignalType" SG_ 710 Sig4472 "ENM";
BA_ "SignalLongName" SG_ 710 Sig4472 "Signal5067";
BA_ "SignalType" SG_ 710 Sig4471 "ENM";
BA_ "SignalLongName" SG_ 710 Sig4471 "Signal5066";
BA_ "SignalLongName" SG_ 710 Sig4470 "Signal5065";
BA_ "SignalLongName" SG_ 710 Sig2590 "Signal2587";
BA_ "SignalType" SG_ 710 Sig2591 "ENM";
BA_ "SignalLongName" SG_ 710 Sig2591 "Signal2588";
BA_ "SignalType" SG_ 710 Sig4475 "ENM";
BA_ "SignalLongName" SG_ 710 Sig4475 "Signal5070";
BA_ "SignalType" SG_ 710 Sig2615 "ENM";
BA_ "SignalLongName" SG_ 710 Sig2615 "Signal2622";
BA_ "SignalType" SG_ 710 Sig6780 "ENM";
BA_ "SignalLongName" SG_ 710 Sig6780 "Signal5071";
BA_ "SignalType" SG_ 710 PwrtrnAutoVehHldEnbld "ENM";
BA_ "SignalLongName" SG_ 710 PwrtrnAutoVehHldEnbld "Powertrain Auto Vehicle Hold Enabled";
BA_ "SignalType" SG_ 710 PwrtrnAutoVehHldActv "ENM";
BA_ "SignalLongName" SG_ 710 PwrtrnAutoVehHldActv "Powertrain Auto Vehicle Hold Active";
BA_ "SignalType" SG_ 710 Sig3620 "ENM";
BA_ "SignalLongName" SG_ 710 Sig3620 "Signal3990";
BA_ "SignalType" SG_ 710 Sig2592 "ENM";
BA_ "SignalLongName" SG_ 710 Sig2592 "Signal2596";
BA_ "SignalType" SG_ 710 Sig2614 "ENM";
BA_ "SignalLongName" SG_ 710 Sig2614 "Signal2621";
BA_ "SignalLongName" SG_ 948 Sig2550 "Signal2679";
BA_ "SignalLongName" SG_ 948 Sig2549 "Signal2678";
BA_ "SignalType" SG_ 948 Sig2548 "ENM";
BA_ "SignalLongName" SG_ 948 Sig2548 "Signal2677";
BA_ "SignalLongName" SG_ 948 Sig2551 "Signal2680";
BA_ "SignalLongName" SG_ 948 Sig2552 "Signal2681";
BA_ "SignalLongName" SG_ 948 Sig2553 "Signal2682";
BA_ "SignalLongName" SG_ 948 BarPrsAbs "Barometric Pressure Absolute";
BA_ "SignalType" SG_ 948 BarPrsAbs_Inv "ENM";
BA_ "SignalLongName" SG_ 948 BarPrsAbs_Inv "Barometric Pressure Absolute Invalid";
BA_ "SignalLongName" SG_ 948 Sig2640 "Signal2646";
BA_ "SignalType" SG_ 948 Sig2642 "ENM";
BA_ "SignalLongName" SG_ 948 Sig2642 "Signal2647";
BA_ "SignalLongName" SG_ 948 Sig4942 "Signal5100";
BA_ "SignalLongName" SG_ 1486 Sig2558 "Signal2556";
BA_ "SignalType" SG_ 1486 Sig2557 "ENM";
BA_ "SignalLongName" SG_ 1486 Sig2557 "Signal2555";
BA_ "SignalType" SG_ 1486 Sig2440 "ENM";
BA_ "SignalLongName" SG_ 1486 Sig2440 "Signal1903";
BA_ "SignalType" SG_ 1486 Sig2444 "ENM";
BA_ "SignalLongName" SG_ 1486 Sig2444 "Signal2256";
BA_ "SignalLongName" SG_ 1801 Sig5017 "Signal5056";
BA_ "SignalLongName" SG_ 1801 Sig2626 "Signal2634";
BA_ "SignalType" SG_ 1801 Sig2627 "ENM";
BA_ "SignalLongName" SG_ 1801 Sig2627 "Signal2635";
BA_ "SignalType" SG_ 1801 Sig5019 "ENM";
BA_ "SignalLongName" SG_ 1801 Sig5019 "Signal5058";
BA_ "SignalType" SG_ 1801 Sig5018 "ENM";
BA_ "SignalLongName" SG_ 1801 Sig5018 "Signal5057";
BA_ "SignalLongName" SG_ 1801 Sig0598 "Signal0500";
BA_ "SignalType" SG_ 1801 Sig2576 "ENM";
BA_ "SignalLongName" SG_ 1801 Sig2576 "Signal2570";
BA_ "SignalType" SG_ 1801 Sig2575 "ENM";
BA_ "SignalLongName" SG_ 1801 Sig2575 "Signal2569";
BA_ "SignalType" SG_ 1801 Sig2574 "ENM";
BA_ "SignalLongName" SG_ 1801 Sig2574 "Signal2568";
BA_ "SignalType" SG_ 1801 Sig2573 "ENM";
BA_ "SignalLongName" SG_ 1801 Sig2573 "Signal2567";
BA_ "SignalType" SG_ 1801 Sig2572 "ENM";
BA_ "SignalLongName" SG_ 1801 Sig2572 "Signal2574";
BA_ "SignalType" SG_ 1801 Sig0599 "ENM";
BA_ "SignalLongName" SG_ 1801 Sig0599 "Signal0501";
BA_ "SignalType" SG_ 1801 Sig2579 "ENM";
BA_ "SignalLongName" SG_ 1801 Sig2579 "Signal2573";
BA_ "SignalType" SG_ 1801 Sig2578 "ENM";
BA_ "SignalLongName" SG_ 1801 Sig2578 "Signal2572";
BA_ "SignalType" SG_ 1801 Sig2577 "ENM";
BA_ "SignalLongName" SG_ 1801 Sig2577 "Signal2571";
BA_ "SignalLongName" SG_ 63 RdLdNomAxlTrq "Road Load Nominal Axle Torque";
BA_ "SignalType" SG_ 934 DrvrTkModeCmnd "ENM";
BA_ "SignalLongName" SG_ 934 DrvrTkModeCmnd "Driver Mode Commanded Information : Driver Track Mode Commanded";
BA_ "SignalType" SG_ 934 DrvrSprtModeCmnd "ENM";
BA_ "SignalLongName" SG_ 934 DrvrSprtModeCmnd "Driver Mode Commanded Information : Driver Sport Mode Commanded";
BA_ "SignalType" SG_ 934 DrvrMtnModeCmnd "ENM";
BA_ "SignalLongName" SG_ 934 DrvrMtnModeCmnd "Driver Mode Commanded Information : Driver Mountain Mode Commanded";
BA_ "SignalType" SG_ 934 DrvrHldModeCmnd "ENM";
BA_ "SignalLongName" SG_ 934 DrvrHldModeCmnd "Driver Mode Commanded Information : Driver Hold Mode Commanded";
BA_ "SignalType" SG_ 934 DrvrExhBrkModeCmnd "ENM";
BA_ "SignalLongName" SG_ 934 DrvrExhBrkModeCmnd "Driver Mode Commanded Information : Driver Exhaust Brake Mode Commanded";
BA_ "SignalType" SG_ 934 DrvrEconModeCmnd "ENM";
BA_ "SignalLongName" SG_ 934 DrvrEconModeCmnd "Driver Mode Commanded Information : Driver Economy Mode Commanded";
BA_ "SignalType" SG_ 934 DrvrCrwlModeCmnd "ENM";
BA_ "SignalLongName" SG_ 934 DrvrCrwlModeCmnd "Driver Mode Commanded Information : Driver Crawl Mode Commanded";
BA_ "SignalType" SG_ 934 DrvrChrgPlusModeCmnd "ENM";
BA_ "SignalLongName" SG_ 934 DrvrChrgPlusModeCmnd "Driver Mode Commanded Information : Driver Charge Plus Mode Commanded";
BA_ "SignalLongName" SG_ 934 FourCrnrLvlgTopSpdLimRespVal "Four Corner Leveling Top Speed Limit Response Value";
BA_ "SignalType" SG_ 934 GrdBrkgDsblModeCmnd "ENM";
BA_ "SignalLongName" SG_ 934 GrdBrkgDsblModeCmnd "Driver Mode Commanded Information : Grade Braking Disable Mode Commanded";
BA_ "SignalType" SG_ 934 DrvrWntrModeCmnd "ENM";
BA_ "SignalLongName" SG_ 934 DrvrWntrModeCmnd "Driver Mode Commanded Information : Driver Winter Mode Commanded";
BA_ "SignalType" SG_ 934 DrvrTowHaulModeCmnd "ENM";
BA_ "SignalLongName" SG_ 934 DrvrTowHaulModeCmnd "Driver Mode Commanded Information : Driver Tow Haul Mode Commanded";
BA_ "SignalType" SG_ 934 PrplSysPriAxlTrqReqStsChsSys "ENM";
BA_ "SignalLongName" SG_ 934 PrplSysPriAxlTrqReqStsChsSys "Propulsion System Primary Axle Torque Request Status Chassis System";
BA_ "SignalType" SG_ 934 FourCrnrLvlgTopSpdLimRespTyp "ENM";
BA_ "SignalLongName" SG_ 934 FourCrnrLvlgTopSpdLimRespTyp "Four Corner Leveling Top Speed Limit Response Type";
BA_ "SignalType" SG_ 934 AccKdwnDtctd "ENM";
BA_ "SignalLongName" SG_ 934 AccKdwnDtctd "Accelerator Kick Down Detected";
BA_ "SignalType" SG_ 1490 VhSpdCntlSystmTyp "ENM";
BA_ "SignalLongName" SG_ 1490 VhSpdCntlSystmTyp "Vehicle Speed Control System Type";
BA_ "SignalType" SG_ 1490 DrvrSeltdSpdLmtrIndReq "ENM";
BA_ "SignalLongName" SG_ 1490 DrvrSeltdSpdLmtrIndReq "Driver Selected Speed Limiter Indication Request";
BA_ "SignalType" SG_ 1490 EngNEmsnsRltMlfnAct "ENM";
BA_ "SignalLongName" SG_ 1490 EngNEmsnsRltMlfnAct "Engine Non Emissions Related Malfunction Active";
BA_ "SignalType" SG_ 1490 DrSlctdSpdLmtrEnbld "ENM";
BA_ "SignalLongName" SG_ 1490 DrSlctdSpdLmtrEnbld "Driver Selected Speed Limiter Enabled";
BA_ "SignalType" SG_ 1490 DrSlctdSpdLmtrActv "ENM";
BA_ "SignalLongName" SG_ 1490 DrSlctdSpdLmtrActv "Driver Selected Speed Limiter Active";
BA_ "SignalLongName" SG_ 1264 VhGrdSnsrBsd "Vehicle Grade Sensor Based";
BA_ "SignalType" SG_ 1264 VhGrdSnsrBsd_Inv "ENM";
BA_ "SignalLongName" SG_ 1264 VhGrdSnsrBsd_Inv "Vehicle Grade Sensor Based Invalid";
BA_ "SignalLongName" SG_ 1264 DrvlnFinlAxlRat "Driveline Final Axle Ratio";
BA_ "SignalLongName" SG_ 52 TrnsOvrllEstTrqRt "Transmission Overall Estimated Torque Ratio";
BA_ "SignalType" SG_ 52 TrnsOvrllEstTrqRt_Inv "ENM";
BA_ "SignalLongName" SG_ 52 TrnsOvrllEstTrqRt_Inv "Transmission Overall Estimated Torque Ratio Invalid";
BA_ "SignalLongName" SG_ 1491 TrnsOilTmp "Transmission Oil Temperature";
BA_ "SignalType" SG_ 1491 TrnsOilTmp_Inv "ENM";
BA_ "SignalLongName" SG_ 1491 TrnsOilTmp_Inv "Transmission Oil Temperature Invalid";
BA_ "SignalType" SG_ 1491 TrnsOlTmpSnsPrs "ENM";
BA_ "SignalLongName" SG_ 1491 TrnsOlTmpSnsPrs "Transmission Oil Temperature Sensor Present";
BA_ "SignalType" SG_ 1491 Sig7786 "ENM";
BA_ "SignalLongName" SG_ 1491 Sig7786 "Signal7749";
BA_ "SignalType" SG_ 1491 Sig7800 "ENM";
BA_ "SignalLongName" SG_ 1491 Sig7800 "Signal7779";
BA_ "SignalLongName" SG_ 99 LoVltgSetptCmd "Low Voltage Setpoint Command";
BA_ "SignalType" SG_ 203 RegVltgCtlPwrtrnOvrrdInhbd "ENM";
BA_ "SignalLongName" SG_ 203 RegVltgCtlPwrtrnOvrrdInhbd "Regulated Voltage Control Powertrain Override Inhibited";
BA_ "SignalType" SG_ 936 GenStptDtCycPtOvrAct "ENM";
BA_ "SignalLongName" SG_ 936 GenStptDtCycPtOvrAct "Generator Setpoint Duty Cycle Powertrain Override Active";
BA_ "SignalType" SG_ 714 ElecShfLckdBcklPsngrStBltIndOn "ENM";
BA_ "SignalLongName" SG_ 714 ElecShfLckdBcklPsngrStBltIndOn "Electronic Shift Locked Buckle Passenger Seatbelt Indication On";
BA_ "SignalType" SG_ 714 ElecShfLckdBcklDrvrStBltIndOn "ENM";
BA_ "SignalLongName" SG_ 714 ElecShfLckdBcklDrvrStBltIndOn "Electronic Shift Locked Buckle Driver Seatbelt Indication On";
BA_ "SignalType" SG_ 714 DCCnvStblznErrIndOn "ENM";
BA_ "SignalLongName" SG_ 714 DCCnvStblznErrIndOn "DCDC Converter Stabilization Error Indication On";
BA_ "SignalType" SG_ 714 RegVltgCtlEngyRcvryActv "ENM";
BA_ "SignalLongName" SG_ 714 RegVltgCtlEngyRcvryActv "Regulated Voltage Control Energy Recovery Active";
BA_ "SignalType" SG_ 714 NoKeyDtdElecShfDndIndOn "ENM";
BA_ "SignalLongName" SG_ 714 NoKeyDtdElecShfDndIndOn "No Key Detected Electronic Shift Denied Indication On";
BA_ "SignalType" SG_ 714 ElecShfUnlckdBrkToShfIndOn "ENM";
BA_ "SignalLongName" SG_ 714 ElecShfUnlckdBrkToShfIndOn "Electronic Shift Unlocked Brake To Shift Indication On";
BA_ "SignalType" SG_ 1492 ElecShfPriTransCtlrMalfIndOn "ENM";
BA_ "SignalLongName" SG_ 1492 ElecShfPriTransCtlrMalfIndOn "Electronic Shift Primary Transmission Controller Malfunction Indication On";
BA_ "SignalType" SG_ 1492 ElecShfPriShfToDrvTryAgnIndOn "ENM";
BA_ "SignalLongName" SG_ 1492 ElecShfPriShfToDrvTryAgnIndOn "Electronic Shift Primary Shift To Drive Try Again Indication On";
BA_ "SignalType" SG_ 1492 ElecShfPriRdcSpdForReqdShfIndOn "ENM";
BA_ "SignalLongName" SG_ 1492 ElecShfPriRdcSpdForReqdShfIndOn "Electronic Shift Primary Reduce Speed For Requested Shift Indication On";
BA_ "SignalType" SG_ 1492 AirCndOffIO "ENM";
BA_ "SignalLongName" SG_ 1492 AirCndOffIO "Air Conditioning Off Indication On";
BA_ "SignalType" SG_ 1492 EngCmptHotWrnIndReq "ENM";
BA_ "SignalLongName" SG_ 1492 EngCmptHotWrnIndReq "Engine Compartment Hot Warning Indication Request";
BA_ "SignalType" SG_ 1492 ElecShftPrTwoGrsSelIndRq "ENM";
BA_ "SignalLongName" SG_ 1492 ElecShftPrTwoGrsSelIndRq "Electronic Shift Primary Two Gears Selected Indication Request";
BA_ "SignalType" SG_ 1492 ElecShftPrLtdPrfMdIO "ENM";
BA_ "SignalLongName" SG_ 1492 ElecShftPrLtdPrfMdIO "Electronic Shift Primary Limited Performance Mode Indication On";
BA_ "SignalType" SG_ 1492 ElecShftPrHldShftLevEngRngIO "ENM";
BA_ "SignalLongName" SG_ 1492 ElecShftPrHldShftLevEngRngIO "Electronic Shift Primary Hold Shift Lever to Engage Range Indication On";
BA_ "SignalType" SG_ 1492 ElecShftPrDrPrkIntShftAtmpIO "ENM";
BA_ "SignalLongName" SG_ 1492 ElecShftPrDrPrkIntShftAtmpIO "Electronic Shift Primary Driver Park Interlock Shift Attempted Indication On";
BA_ "SignalType" SG_ 1492 ElecShftPrDrIntShftAtmpIO "ENM";
BA_ "SignalLongName" SG_ 1492 ElecShftPrDrIntShftAtmpIO "Electronic Shift Primary Driver Interlock Shift Attempted Indication On";
BA_ "SignalType" SG_ 1492 ElecShftPrDrExitIO "ENM";
BA_ "SignalLongName" SG_ 1492 ElecShftPrDrExitIO "Electronic Shift Primary Driver Exit Indication On";
BA_ "SignalType" SG_ 1492 ElecShftPrDrDoorStIndIO "ENM";
BA_ "SignalLongName" SG_ 1492 ElecShftPrDrDoorStIndIO "ETRS Driver Door State Indeterminate Indication On";
BA_ "SignalType" SG_ 1492 ElecShftPrAtPrkIO "ENM";
BA_ "SignalLongName" SG_ 1492 ElecShftPrAtPrkIO "Electronic Shift Primary Auto Park Indication On";
BA_ "SignalType" SG_ 1492 ElecShfPriTrnVehOffForPrkIndOn "ENM";
BA_ "SignalLongName" SG_ 1492 ElecShfPriTrnVehOffForPrkIndOn "Electronic Shift Primary Turn Vehicle Off For Park Indication On";
BA_ "SignalType" SG_ 1492 ElecShftrLckdHldBrkToOvrrdIndOn "ENM";
BA_ "SignalLongName" SG_ 1492 ElecShftrLckdHldBrkToOvrrdIndOn "Electronic Shifter Locked Hold Brake To Override Indication On";
BA_ "SignalType" SG_ 1492 ElecShftPrTrnMlfIO "ENM";
BA_ "SignalLongName" SG_ 1492 ElecShftPrTrnMlfIO "Electronic Shift Primary Transmission Malfunction Indication On";
BA_ "SignalType" SG_ 1492 ElecShftPrRngInvRqIO "ENM";
BA_ "SignalLongName" SG_ 1492 ElecShftPrRngInvRqIO "Electronic Shift Primary Range Invalid Request Indication On";
BA_ "SignalType" SG_ 1492 ElecShftPrPrkInvRqIO "ENM";
BA_ "SignalLongName" SG_ 1492 ElecShftPrPrkInvRqIO "Electronic Shift Primary Park Invalid Request Indication On";
BA_ "SignalLongName" SG_ 1802 UndrHdAirFlwCap "Under Hood Air Flow Capacity";
BA_ "SignalLongName" SG_ 1802 UndrHdAirFlwActPrcnt "Under Hood Air Flow Actual Percent";
BA_ "SignalLongName" SG_ 1494 ECERDTC_ECP_E_CdNum "Electrification Controls Processor Emissions Related DTC - ECP_E : Code Number";
BA_ "SignalType" SG_ 1494 ECERDTC_ECP_E_SysDes "ENM";
BA_ "SignalLongName" SG_ 1494 ECERDTC_ECP_E_SysDes "Electrification Controls Processor Emissions Related DTC - ECP_E : System Designator";
BA_ "SignalType" SG_ 1494 ElecAllWhlDrvESCTTFlshgActv "ENM";
BA_ "SignalLongName" SG_ 1494 ElecAllWhlDrvESCTTFlshgActv "Electric All Wheel Drive Electronic Stability Control Telltale Flashing Active";
BA_ "SignalType" SG_ 1494 ElecCtlPrcsrEmsRltMlfAtv_ECP_E "ENM";
BA_ "SignalLongName" SG_ 1494 ElecCtlPrcsrEmsRltMlfAtv_ECP_E "Electrification Controls Processor Emissions Related Malfunction Active - ECP_E";
BA_ "SignalLongName" SG_ 1803 DrvMtrInvrtMaxTemp "Drive Motor Inverter Maximum Temperature";
BA_ "SignalType" SG_ 1803 DrvMtrInvrtMaxTemp_Inv "ENM";
BA_ "SignalLongName" SG_ 1803 DrvMtrInvrtMaxTemp_Inv "Drive Motor Inverter Maximum Temperature Invalid";
BA_ "SignalType" SG_ 42 HybChrgModeStat "ENM";
BA_ "SignalLongName" SG_ 42 HybChrgModeStat "Hybrid Charge Mode State";
BA_ "SignalType" SG_ 42 HiVltgActvDischrgCmnd "ENM";
BA_ "SignalLongName" SG_ 42 HiVltgActvDischrgCmnd "High Voltage Active Discharge Commanded";
BA_ "SignalType" SG_ 42 ElecDischrgActr2DischrgSts "ENM";
BA_ "SignalLongName" SG_ 42 ElecDischrgActr2DischrgSts "Electric Discharge Actuator 2 Discharge Status";
BA_ "SignalLongName" SG_ 42 ElecMtrATrqAchvd "Propulsion System Motor A Torque Achieved";
BA_ "SignalType" SG_ 42 Sig3621 "ENM";
BA_ "SignalLongName" SG_ 42 Sig3621 "Signal3991";
BA_ "SignalType" SG_ 42 ElecMtrATrqAchvd_Inv "ENM";
BA_ "SignalLongName" SG_ 42 ElecMtrATrqAchvd_Inv "Propulsion System Motor A Torque Achieved Invalid";
BA_ "SignalLongName" SG_ 732 ElecMtrASttrTemp "Propulsion System Motor A Stator Temperature";
BA_ "SignalType" SG_ 732 ElecMtrASttrTemp_Inv "ENM";
BA_ "SignalLongName" SG_ 732 ElecMtrASttrTemp_Inv "Propulsion System Motor A Stator Temperature Invalid";
BA_ "SignalLongName" SG_ 732 HiVltgThrmlUpprPwrLim "High Voltage Thermal Upper Power Limit";
BA_ "SignalType" SG_ 43 ElecDischrgActr4DischrgSts "ENM";
BA_ "SignalLongName" SG_ 43 ElecDischrgActr4DischrgSts "Electric Discharge Actuator 4 Discharge Status";
BA_ "SignalLongName" SG_ 1263 DMCM3ERDTC_CdNum "Drive Motor Control Module 3 Emissions Related DTC : Code Number";
BA_ "SignalLongName" SG_ 1263 PIMRI_ECP_S2_RcntlyProgInd "Programming Inspection and Maintenance Readiness Indication - ECP_S2 : Recently Programmed Indicator";
BA_ "SignalType" SG_ 1263 PIMRI_ECP_S2_PrmntDTCInd "ENM";
BA_ "SignalLongName" SG_ 1263 PIMRI_ECP_S2_PrmntDTCInd "Programming Inspection and Maintenance Readiness Indication - ECP_S2 : Permanent DTC Indicator";
BA_ "SignalType" SG_ 1263 PIMRI_ECP_S2_FltsPrsntInd "ENM";
BA_ "SignalLongName" SG_ 1263 PIMRI_ECP_S2_FltsPrsntInd "Programming Inspection and Maintenance Readiness Indication - ECP_S2 : Faults Present Indicator";
BA_ "SignalType" SG_ 1263 DMCM3EmsRltMlfAtv "ENM";
BA_ "SignalLongName" SG_ 1263 DMCM3EmsRltMlfAtv "Drive Motor Control Module 3 Emissions Related Malfunction Active";
BA_ "SignalType" SG_ 1263 DMCM3ERDTC_SysDes "ENM";
BA_ "SignalLongName" SG_ 1263 DMCM3ERDTC_SysDes "Drive Motor Control Module 3 Emissions Related DTC : System Designator";
BA_ "SignalLongName" SG_ 113 Sig0502 "Signal0426";
BA_ "SignalType" SG_ 113 Sig0503 "ENM";
BA_ "SignalLongName" SG_ 113 Sig0503 "Signal0427";
BA_ "SignalType" SG_ 113 Sig0505 "ENM";
BA_ "SignalLongName" SG_ 113 Sig0505 "Signal0429";
BA_ "SignalLongName" SG_ 113 Sig0504 "Signal0428";
BA_ "SignalLongName" SG_ 113 Sig0507 "Signal0431";
BA_ "SignalType" SG_ 113 Sig0508 "ENM";
BA_ "SignalLongName" SG_ 113 Sig0508 "Signal0432";
BA_ "SignalLongName" SG_ 113 Sig0509 "Signal0433";
BA_ "SignalType" SG_ 113 Sig0510 "ENM";
BA_ "SignalLongName" SG_ 113 Sig0510 "Signal0434";
BA_ "SignalType" SG_ 113 Sig0506 "ENM";
BA_ "SignalLongName" SG_ 113 Sig0506 "Signal0430";
BA_ "SignalType" SG_ 113 Sig0501 "ENM";
BA_ "SignalLongName" SG_ 113 Sig0501 "Signal0425";
BA_ "SignalLongName" SG_ 733 Sig0511 "Signal0435";
BA_ "SignalType" SG_ 733 Sig0512 "ENM";
BA_ "SignalLongName" SG_ 733 Sig0512 "Signal0436";
BA_ "SignalLongName" SG_ 1495 Sig2504 "Signal2560";
BA_ "SignalType" SG_ 1495 Sig2505 "ENM";
BA_ "SignalLongName" SG_ 1495 Sig2505 "Signal2561";
BA_ "SignalType" SG_ 1495 Sig2566 "ENM";
BA_ "SignalLongName" SG_ 1495 Sig2566 "Signal2562";
BA_ "SignalLongName" SG_ 1262 Sig4457 "Signal5081";
BA_ "SignalType" SG_ 1262 Sig4456 "ENM";
BA_ "SignalLongName" SG_ 1262 Sig4456 "Signal5080";
BA_ "SignalType" SG_ 1262 Sig4455 "ENM";
BA_ "SignalLongName" SG_ 1262 Sig4455 "Signal5079";
BA_ "SignalType" SG_ 41 ElecDischrgActr3DischrgSts "ENM";
BA_ "SignalLongName" SG_ 41 ElecDischrgActr3DischrgSts "Electric Discharge Actuator 3 Discharge Status";
BA_ "SignalLongName" SG_ 1804 ECPSERDTC_CdNum "Electrification Controls Processor Secondary Emissions Related DTC : Code Number";
BA_ "SignalType" SG_ 1804 ECPSERDTC_SysDes "ENM";
BA_ "SignalLongName" SG_ 1804 ECPSERDTC_SysDes "Electrification Controls Processor Secondary Emissions Related DTC : System Designator";
BA_ "SignalLongName" SG_ 1804 DrvMtrInvrt2MaxTemp "Drive Motor Inverter 2 Maximum Temperature";
BA_ "SignalType" SG_ 1804 DrvMtrInvrt2MaxTemp_Inv "ENM";
BA_ "SignalLongName" SG_ 1804 DrvMtrInvrt2MaxTemp_Inv "Drive Motor Inverter 2 Maximum Temperature Invalid";
BA_ "SignalLongName" SG_ 1804 DMCM2ERDTC_CdNum "Drive Motor Control Module 2 Emissions Related DTC : Code Number";
BA_ "SignalType" SG_ 1804 ECPSEmsRltMlfAtv "ENM";
BA_ "SignalLongName" SG_ 1804 ECPSEmsRltMlfAtv "Electrification Controls Processor Secondary Emissions Related Malfunction Active";
BA_ "SignalLongName" SG_ 1804 PIMRI_ECP_S_RcntlyProgInd "Programming Inspection and Maintenance Readiness Indication - ECP_S : Recently Programmed Indicator";
BA_ "SignalType" SG_ 1804 PIMRI_ECP_S_PrmntDTCInd "ENM";
BA_ "SignalLongName" SG_ 1804 PIMRI_ECP_S_PrmntDTCInd "Programming Inspection and Maintenance Readiness Indication - ECP_S : Permanent DTC Indicator";
BA_ "SignalType" SG_ 1804 PIMRI_ECP_S_FltsPrsntInd "ENM";
BA_ "SignalLongName" SG_ 1804 PIMRI_ECP_S_FltsPrsntInd "Programming Inspection and Maintenance Readiness Indication - ECP_S : Faults Present Indicator";
BA_ "SignalType" SG_ 1804 DMCM2EmsRltMlfAtv "ENM";
BA_ "SignalLongName" SG_ 1804 DMCM2EmsRltMlfAtv "Drive Motor Control Module 2 Emissions Related Malfunction Active";
BA_ "SignalType" SG_ 1804 DMCM2ERDTC_SysDes "ENM";
BA_ "SignalLongName" SG_ 1804 DMCM2ERDTC_SysDes "Drive Motor Control Module 2 Emissions Related DTC : System Designator";
BA_ "SignalLongName" SG_ 512 Sig4937 "Signal5096";
BA_ "SignalLongName" SG_ 512 Sig4938 "Signal5097";
BA_ "SignalLongName" SG_ 734 ElecMtrARotrTemp "Propulsion System Motor A Rotor Temperature";
BA_ "SignalType" SG_ 734 ElecMtrARotrTemp_Inv "ENM";
BA_ "SignalLongName" SG_ 734 ElecMtrARotrTemp_Inv "Propulsion System Motor A Rotor Temperature Invalid";
BA_ "SignalType" SG_ 1497 Sig2564 "ENM";
BA_ "SignalLongName" SG_ 1497 Sig2564 "Signal2548";
BA_ "SignalType" SG_ 1497 Sig2563 "ENM";
BA_ "SignalLongName" SG_ 1497 Sig2563 "Signal2547";
BA_ "SignalLongName" SG_ 1415 RCMHSR_HptcStReqSeqNum "Rear Collision Mitigation Haptic Seat Request : Haptic Seat Request Sequence Number";
BA_ "SignalLongName" SG_ 1415 RCMHSR_HptcStReqPuls "Rear Collision Mitigation Haptic Seat Request : Haptic Seat Request Pulses";
BA_ "SignalType" SG_ 1415 HtdStrgWhlDrvOutStsGtd "ENM";
BA_ "SignalLongName" SG_ 1415 HtdStrgWhlDrvOutStsGtd "Heated Steering Wheel Drive Output Status Gated";
BA_ "SignalType" SG_ 1415 HtdStrgWhlDrvOutStsGtd_Inv "ENM";
BA_ "SignalLongName" SG_ 1415 HtdStrgWhlDrvOutStsGtd_Inv "Heated Steering Wheel Drive Output Status Gated Invalid";
BA_ "SignalType" SG_ 1415 LnCntrWrnIndRqst "ENM";
BA_ "SignalLongName" SG_ 1415 LnCntrWrnIndRqst "Lane Centering Warning Indication Request";
BA_ "SignalType" SG_ 1415 LnFllwgHzrdLgtsReq "ENM";
BA_ "SignalLongName" SG_ 1415 LnFllwgHzrdLgtsReq "Lane Following Hazard Lights Request";
BA_ "SignalType" SG_ 1415 LnCntrEsclnSts "ENM";
BA_ "SignalLongName" SG_ 1415 LnCntrEsclnSts "Lane Centering Escalation Status";
BA_ "SignalType" SG_ 1415 HtdStrgWhlStkSwGtd "ENM";
BA_ "SignalLongName" SG_ 1415 HtdStrgWhlStkSwGtd "Heated Steering Wheel Stuck Switch Gated";
BA_ "SignalType" SG_ 1415 HtdStrgWhlStkSwGtd_Inv "ENM";
BA_ "SignalLongName" SG_ 1415 HtdStrgWhlStkSwGtd_Inv "Heated Steering Wheel Stuck Switch Gated Invalid";
BA_ "SignalType" SG_ 1415 HtdStrgWhlExtrnFltPrsntGtd "ENM";
BA_ "SignalLongName" SG_ 1415 HtdStrgWhlExtrnFltPrsntGtd "Heated Steering Wheel External Fault Present Gated";
BA_ "SignalType" SG_ 1415 HtdStrgWhlExtrnFltPrsntGtd_Inv "ENM";
BA_ "SignalLongName" SG_ 1415 HtdStrgWhlExtrnFltPrsntGtd_Inv "Heated Steering Wheel External Fault Present Gated Invalid";
BA_ "SignalType" SG_ 1415 CIBAutoBrkRelIndOn "ENM";
BA_ "SignalLongName" SG_ 1415 CIBAutoBrkRelIndOn "Collision Imminent Braking Autonomous Brake Release Indication On";
BA_ "SignalType" SG_ 1415 RIMIntCllnChmEvStat "ENM";
BA_ "SignalLongName" SG_ 1415 RIMIntCllnChmEvStat "Rearward Impact Mitigation Initial Collision Chime Event State";
BA_ "SignalType" SG_ 1415 RIMBrkPlsChEvStat "ENM";
BA_ "SignalLongName" SG_ 1415 RIMBrkPlsChEvStat "Rearward Impact Mitigation Brake Pulse Chime Event State";
BA_ "SignalType" SG_ 1415 ManHtdStrgWhlReqdGtd "ENM";
BA_ "SignalLongName" SG_ 1415 ManHtdStrgWhlReqdGtd "Manual Heated Steering Wheel Requested Gated";
BA_ "SignalType" SG_ 1415 ManHtdStrgWhlReqdGtd_Inv "ENM";
BA_ "SignalLongName" SG_ 1415 ManHtdStrgWhlReqdGtd_Inv "Manual Heated Steering Wheel Requested Gated Invalid";
BA_ "SignalType" SG_ 1415 RIM_BrkPrfllReq "ENM";
BA_ "SignalLongName" SG_ 1415 RIM_BrkPrfllReq "Rear Impact Mitigation Brake Prefill Request";
BA_ "SignalType" SG_ 1415 RIMUnIndOn "ENM";
BA_ "SignalLongName" SG_ 1415 RIMUnIndOn "Rearward Impact Mitigation Unavailable Indication On";
BA_ "SignalType" SG_ 1415 RIMONIndOn "ENM";
BA_ "SignalLongName" SG_ 1415 RIMONIndOn "Rearward Impact Mitigation ON Indication On";
BA_ "SignalType" SG_ 1415 RIMOFFIndOn "ENM";
BA_ "SignalLongName" SG_ 1415 RIMOFFIndOn "Rearward Impact Mitigation OFF Indication On";
BA_ "SignalType" SG_ 1415 LnCntrMisuseCond "ENM";
BA_ "SignalLongName" SG_ 1415 LnCntrMisuseCond "Lane Centering Misuse Condition";
BA_ "SignalType" SG_ 1415 LnCntrDrvAwrIndOn "ENM";
BA_ "SignalLongName" SG_ 1415 LnCntrDrvAwrIndOn "Lane Centering Driver Awareness Indication On";
BA_ "SignalType" SG_ 1415 HtdStrgWhlSwActvGtd "ENM";
BA_ "SignalLongName" SG_ 1415 HtdStrgWhlSwActvGtd "Heated Steering Wheel Switch Active Gated";
BA_ "SignalType" SG_ 1415 FIM_CIS_BrkPrfllReq "ENM";
BA_ "SignalLongName" SG_ 1415 FIM_CIS_BrkPrfllReq "Front Impact Mitigation Collision Inminent Steering Brake Prefill Request";
BA_ "SignalType" SG_ 1415 SuprRmtPrkSptSeltnRmtReq "ENM";
BA_ "SignalLongName" SG_ 1415 SuprRmtPrkSptSeltnRmtReq "Supervised Remote Parking Spot Selection Request : Supervised Remote Parking Spot Selection Remote Request";
BA_ "SignalType" SG_ 1415 SuprRmtPrkSptSeltnKeepLkReq "ENM";
BA_ "SignalLongName" SG_ 1415 SuprRmtPrkSptSeltnKeepLkReq "Supervised Remote Parking Spot Selection Request : Supervised Remote Parking Spot Selection Keep Looking Request";
BA_ "SignalType" SG_ 1415 SuprRmtPrkSptSeltnAcceptReq "ENM";
BA_ "SignalLongName" SG_ 1415 SuprRmtPrkSptSeltnAcceptReq "Supervised Remote Parking Spot Selection Request : Supervised Remote Parking Spot Selection Accept Request";
BA_ "SignalType" SG_ 1415 TnDrvRIMOFFUnvIndOn "ENM";
BA_ "SignalLongName" SG_ 1415 TnDrvRIMOFFUnvIndOn "Teen Driver Rearward Impact Mitigation OFF Unavailable Indication On";
BA_ "SignalType" SG_ 1415 RrVirtBmpAutoBrkRelIndOn "ENM";
BA_ "SignalLongName" SG_ 1415 RrVirtBmpAutoBrkRelIndOn "Rear Virtual Bumper Autonomous Brake Release Indication On";
BA_ "SignalType" SG_ 1415 RIM_BrkPulsReq "ENM";
BA_ "SignalLongName" SG_ 1415 RIM_BrkPulsReq "Rear Impact Mitigation Brake Pulse Request";
BA_ "SignalType" SG_ 1415 SuprRmtPrkUnabletoCnctTryAgnReq "ENM";
BA_ "SignalLongName" SG_ 1415 SuprRmtPrkUnabletoCnctTryAgnReq "Supervised Remote Parking Unable To Connect Request : Supervised Remote Parking Unable to Connect Try Again Request";
BA_ "SignalType" SG_ 1415 SuprRmtPrkUnabletoCnctExtReq "ENM";
BA_ "SignalLongName" SG_ 1415 SuprRmtPrkUnabletoCnctExtReq "Supervised Remote Parking Unable To Connect Request : Supervised Remote Parking Unable to Connect Exit Request";
BA_ "SignalType" SG_ 1431 LnChgDmndMomtryLnChgDsbl "ENM";
BA_ "SignalLongName" SG_ 1431 LnChgDmndMomtryLnChgDsbl "Lane Change on Demand Momentary Lane Change Disable";
BA_ "SignalType" SG_ 1431 LnChgDmndLnChgReq "ENM";
BA_ "SignalLongName" SG_ 1431 LnChgDmndLnChgReq "Lane Change on Demand Lane Change Request";
BA_ "SignalLongName" SG_ 1499 LnCntrArrwBlck1Offst "Lane Centering Arrow Block 1 Offset";
BA_ "SignalLongName" SG_ 1499 LnCntrArrwBlck2Offst "Lane Centering Arrow Block 2 Offset";
BA_ "SignalType" SG_ 1499 LnCntrArrwBlck1Act "ENM";
BA_ "SignalLongName" SG_ 1499 LnCntrArrwBlck1Act "Lane Centering Arrow Block 1 Active";
BA_ "SignalType" SG_ 1499 LnCntrSpchPrmtReq "ENM";
BA_ "SignalLongName" SG_ 1499 LnCntrSpchPrmtReq "Lane Centering Speech Prompt Request";
BA_ "SignalType" SG_ 1499 LnCntrCnvMsgIndRqst "ENM";
BA_ "SignalLongName" SG_ 1499 LnCntrCnvMsgIndRqst "Lane Centering Convenience Message Indication Request";
BA_ "SignalType" SG_ 1499 RIMObjAtchdIndOn "ENM";
BA_ "SignalLongName" SG_ 1499 RIMObjAtchdIndOn "Rearward Impact Mitigation Object Attached Indication On";
BA_ "SignalType" SG_ 1499 RIMElecPrkBrkRelIndOn "ENM";
BA_ "SignalLongName" SG_ 1499 RIMElecPrkBrkRelIndOn "Rearward Impact Mitigation Electric Park Brake Release Indication On";
BA_ "SignalType" SG_ 1499 LnCntrArrwBlck5Act "ENM";
BA_ "SignalLongName" SG_ 1499 LnCntrArrwBlck5Act "Lane Centering Arrow Block 5 Active";
BA_ "SignalType" SG_ 1499 LnCntrArrwBlck4Act "ENM";
BA_ "SignalLongName" SG_ 1499 LnCntrArrwBlck4Act "Lane Centering Arrow Block 4 Active";
BA_ "SignalType" SG_ 1499 LnCntrArrwBlck3Act "ENM";
BA_ "SignalLongName" SG_ 1499 LnCntrArrwBlck3Act "Lane Centering Arrow Block 3 Active";
BA_ "SignalType" SG_ 1499 LnCntrArrwBlck2Act "ENM";
BA_ "SignalLongName" SG_ 1499 LnCntrArrwBlck2Act "Lane Centering Arrow Block 2 Active";
BA_ "SignalLongName" SG_ 181 FCAR_PV "Forward Collision Alert Request : Protected Value";
BA_ "SignalType" SG_ 181 FCAR_FCAImntCruzCtlCnclReqd "ENM";
BA_ "SignalLongName" SG_ 181 FCAR_FCAImntCruzCtlCnclReqd "Forward Collision Alert Request : Forward Collision Alert Imminent Cruise Control Cancel Requested";
BA_ "SignalLongName" SG_ 181 FCAR_ARC "Forward Collision Alert Request : Alive Rolling Count";
BA_ "SignalLongName" SG_ 1416 ACCHSR_HptcStReqSeqNum "Adaptive Cruise Control Haptic Seat Request : Haptic Seat Request Sequence Number";
BA_ "SignalLongName" SG_ 1416 ACCHSR_HptcStReqPuls "Adaptive Cruise Control Haptic Seat Request : Haptic Seat Request Pulses";
BA_ "SignalLongName" SG_ 1416 FPCMHSR_HptcStReqSeqNum "Front Pedestrian Collision Mitigation Haptic Seat Request : Haptic Seat Request Sequence";
BA_ "SignalLongName" SG_ 1416 FPCMHSR_HptcStReqPuls "Front Pedestrian Collision Mitigation Haptic Seat Request : Haptic Seat Request Pulses";
BA_ "SignalLongName" SG_ 1416 FCAIAHSR_HptcStReqSeqNum "Forward Collision Alert Imminent Haptic Seat Request : Haptic Seat Request Sequence";
BA_ "SignalLongName" SG_ 1416 FCAIAHSR_HptcStReqPuls "Forward Collision Alert Imminent Haptic Seat Request : Haptic Seat Request Pulses";
BA_ "SignalLongName" SG_ 1416 LDWCLHSHSR_HptcStReqSeqNum "Lane Detection Warning and Control Left Hand Side Haptic Seat Request : Haptic Seat Request Sequence Number";
BA_ "SignalLongName" SG_ 1416 LDWCLHSHSR_HptcStReqPuls "Lane Detection Warning and Control Left Hand Side Haptic Seat Request : Haptic Seat Request Pulses";
BA_ "SignalLongName" SG_ 1416 LDWCRHSHSR_HptcStReqSeqNum "Lane Detection Warning and Control Right Hand Side Haptic Seat Request : Haptic Seat Request Sequence Number";
BA_ "SignalLongName" SG_ 1416 LDWCRHSHSR_HptcStReqPuls "Lane Detection Warning and Control Right Hand Side Haptic Seat Request : Haptic Seat Request Pulses";
BA_ "SignalType" SG_ 1416 LKALnMrkgIndLt "ENM";
BA_ "SignalLongName" SG_ 1416 LKALnMrkgIndLt "Lane Keep Assist Lane Marking Indication Left";
BA_ "SignalType" SG_ 1416 GoNotfrCstCrStVal "ENM";
BA_ "SignalLongName" SG_ 1416 GoNotfrCstCrStVal "Go Notifier Customization Current Setting Value";
BA_ "SignalType" SG_ 1416 FrwdVhImAlrtIndRqst "ENM";
BA_ "SignalLongName" SG_ 1416 FrwdVhImAlrtIndRqst "Forward Vehicle Imminent Alert Indication Request";
BA_ "SignalType" SG_ 1416 LnDtWrnCntrlVsAlrtCmdGnc "ENM";
BA_ "SignalLongName" SG_ 1416 LnDtWrnCntrlVsAlrtCmdGnc "Lane Detection Warning and Control Visual Alert Command Generic";
BA_ "SignalType" SG_ 1416 LnDtWrnCntrlFtrSt "ENM";
BA_ "SignalLongName" SG_ 1416 LnDtWrnCntrlFtrSt "Lane Detection Warning and Control Feature State";
BA_ "SignalType" SG_ 1416 LKALnMrkgIndRt "ENM";
BA_ "SignalLongName" SG_ 1416 LKALnMrkgIndRt "Lane Keep Assist Lane Marking Indication Right";
BA_ "SignalType" SG_ 1416 LDWCtrlHndOff1ChmEvntStat "ENM";
BA_ "SignalLongName" SG_ 1416 LDWCtrlHndOff1ChmEvntStat "Lane Detection Warning and Control Hands Off 1 Chime Event State";
BA_ "SignalType" SG_ 1416 FrwdCllsnAlrtImAlrtDrIntAlrtChmE "ENM";
BA_ "SignalLongName" SG_ 1416 FrwdCllsnAlrtImAlrtDrIntAlrtChmE "Forward Collision Alert Imminent Alert Driver Intervention Alert Chime Event State";
BA_ "SignalType" SG_ 1416 FrntPCMChmEvntStat "ENM";
BA_ "SignalLongName" SG_ 1416 FrntPCMChmEvntStat "Front Pedestrian Collision Mitigation Chime Event State";
BA_ "SignalType" SG_ 1416 LDWCtrlRtHndSdChmEvntStat "ENM";
BA_ "SignalLongName" SG_ 1416 LDWCtrlRtHndSdChmEvntStat "Lane Detection Warning and Control Right Hand Side Chime Event State";
BA_ "SignalType" SG_ 1416 LDWCtrlLtHndSdChmEvntStat "ENM";
BA_ "SignalLongName" SG_ 1416 LDWCtrlLtHndSdChmEvntStat "Lane Detection Warning and Control Left Hand Side Chime Event State";
BA_ "SignalType" SG_ 1416 LDWCtrlHndOff3ChmEvntStat "ENM";
BA_ "SignalLongName" SG_ 1416 LDWCtrlHndOff3ChmEvntStat "Lane Detection Warning and Control Hands Off 3 Chime Event State";
BA_ "SignalType" SG_ 1416 LDWCtrlHndOff2ChmEvntStat "ENM";
BA_ "SignalLongName" SG_ 1416 LDWCtrlHndOff2ChmEvntStat "Lane Detection Warning and Control Hands Off 2 Chime Event State";
BA_ "SignalType" SG_ 1416 LDWCtrlAudAttnReqd "ENM";
BA_ "SignalLongName" SG_ 1416 LDWCtrlAudAttnReqd "Lane Detection Warning and Control Audio Attenuation Requested";
BA_ "SignalType" SG_ 1416 GoNotfrCstStAvl "ENM";
BA_ "SignalLongName" SG_ 1416 GoNotfrCstStAvl "Go Notifier Customization Setting Available";
BA_ "SignalType" SG_ 1416 FrwdVhHdwyAlrtIndOn "ENM";
BA_ "SignalLongName" SG_ 1416 FrwdVhHdwyAlrtIndOn "Forward Vehicle Headway Alert Indication On";
BA_ "SignalType" SG_ 1416 FCA_BrkPrfllReq "ENM";
BA_ "SignalLongName" SG_ 1416 FCA_BrkPrfllReq "Forward Collision Alert Brake Prefill Request";
BA_ "SignalType" SG_ 1416 AdptCrsCntrlEngd "ENM";
BA_ "SignalLongName" SG_ 1416 AdptCrsCntrlEngd "Adaptive Cruise Control Engaged";
BA_ "SignalType" SG_ 1500 ACCTrlrGapSetIndOn "ENM";
BA_ "SignalLongName" SG_ 1500 ACCTrlrGapSetIndOn "Adaptive Cruise Control Information 2 : Adaptive Cruise Control Trailer Gap Setting Indication On";
BA_ "SignalLongName" SG_ 1500 FllwgTmIndVal "Following Time Indicator Value";
BA_ "SignalType" SG_ 1500 FllwgTmDsplyMd "ENM";
BA_ "SignalLongName" SG_ 1500 FllwgTmDsplyMd "Following Time Display Mode";
BA_ "SignalType" SG_ 1500 FrwdHdwyVisIndCtl "ENM";
BA_ "SignalLongName" SG_ 1500 FrwdHdwyVisIndCtl "Adaptive Cruise Control Information 2 : Forward Headway Visual Indicator Control";
BA_ "SignalType" SG_ 1500 FCA_ACCGapSetIndOn "ENM";
BA_ "SignalLongName" SG_ 1500 FCA_ACCGapSetIndOn "Adaptive Cruise Control Information 2 : Forward Collision Alert Adaptive Cruise Control Gap Setting Indication On";
BA_ "SignalType" SG_ 1500 FCAACCGapSeltn "ENM";
BA_ "SignalLongName" SG_ 1500 FCAACCGapSeltn "Adaptive Cruise Control Information 2 : Forward Collision Alert - Adaptive Cruise Control Gap Selection";
BA_ "SignalType" SG_ 1500 LAOA_LatAsstHoLFOptAval "ENM";
BA_ "SignalLongName" SG_ 1500 LAOA_LatAsstHoLFOptAval "Lateral Assist Options Available : HoLF";
BA_ "SignalType" SG_ 1500 AdpAndCnvntlCruzCtlIndReq "ENM";
BA_ "SignalLongName" SG_ 1500 AdpAndCnvntlCruzCtlIndReq "Adaptive and Conventional Cruise Control Indication Request";
BA_ "SignalType" SG_ 1500 LtAstStsIndRq "ENM";
BA_ "SignalLongName" SG_ 1500 LtAstStsIndRq "Lateral Assist Status Indication Request";
BA_ "SignalType" SG_ 1500 FCAGpSet "ENM";
BA_ "SignalLongName" SG_ 1500 FCAGpSet "Forward Collision Alert Gap Setting";
BA_ "SignalType" SG_ 1500 LAOA_LatAsstOffOptAval "ENM";
BA_ "SignalLongName" SG_ 1500 LAOA_LatAsstOffOptAval "Lateral Assist Options Available : Off";
BA_ "SignalType" SG_ 1500 LAOA_LatAsstLKAOptAval "ENM";
BA_ "SignalLongName" SG_ 1500 LAOA_LatAsstLKAOptAval "Lateral Assist Options Available : LKA";
BA_ "SignalType" SG_ 1500 LAOA_LatAsstLDWOptAval "ENM";
BA_ "SignalLongName" SG_ 1500 LAOA_LatAsstLDWOptAval "Lateral Assist Options Available : LDW";
BA_ "SignalType" SG_ 1500 PdWrnIndRqst "ENM";
BA_ "SignalLongName" SG_ 1500 PdWrnIndRqst "Pedestrian Warning Indication Request";
BA_ "SignalType" SG_ 1500 LnDprtrWrnCtlSdThrtRtMirIndReq "ENM";
BA_ "SignalLongName" SG_ 1500 LnDprtrWrnCtlSdThrtRtMirIndReq "Lane Departure Warning and Control Side Threat Right Mirror Indication Request";
BA_ "SignalType" SG_ 1500 LnDprtrWrnCtlSdThrtLtMirIndReq "ENM";
BA_ "SignalLongName" SG_ 1500 LnDprtrWrnCtlSdThrtLtMirIndReq "Lane Departure Warning and Control Side Threat Left Mirror Indication Request";
BA_ "SignalType" SG_ 1500 ACCHdwySttng "ENM";
BA_ "SignalLongName" SG_ 1500 ACCHdwySttng "Adaptive Cruise Control Headway Setting";
BA_ "SignalType" SG_ 1500 FrtPedtrnBrkgWrnIndOn "ENM";
BA_ "SignalLongName" SG_ 1500 FrtPedtrnBrkgWrnIndOn "Front Pedestrian Braking Warning Indication On";
BA_ "SignalType" SG_ 1500 ACCTmpUnvIndOn "ENM";
BA_ "SignalLongName" SG_ 1500 ACCTmpUnvIndOn "Adaptive Cruise Control Temporary Unavailable Indication On";
BA_ "SignalType" SG_ 1500 ACCSysSlctdMdDspIndOn "ENM";
BA_ "SignalLongName" SG_ 1500 ACCSysSlctdMdDspIndOn "Adaptive Cruise Control System Selected Mode Display Indication On";
BA_ "SignalType" SG_ 1500 ACCShftToPrkBfrExIndOn "ENM";
BA_ "SignalLongName" SG_ 1500 ACCShftToPrkBfrExIndOn "Adaptive Cruise Control Shift To Park Before Exiting Vehicle Indication On";
BA_ "SignalType" SG_ 1500 ACCRtSpdAdVsIndOn "ENM";
BA_ "SignalLongName" SG_ 1500 ACCRtSpdAdVsIndOn "Adaptive Cruise Control Route Speed Adaptation Visual Indication On";
BA_ "SignalType" SG_ 1500 ACCHdwySttngIndOn "ENM";
BA_ "SignalLongName" SG_ 1500 ACCHdwySttngIndOn "Adaptive Cruise Control Headway Setting Indication On";
BA_ "SignalType" SG_ 1500 ACCDsngIndOn "ENM";
BA_ "SignalLongName" SG_ 1500 ACCDsngIndOn "Adaptive Cruise Control Disengaging Indication On";
BA_ "SignalType" SG_ 1500 SrvDvrAsstSystVslMsgRqstOn "ENM";
BA_ "SignalLongName" SG_ 1500 SrvDvrAsstSystVslMsgRqstOn "Service Driver Assist System Visual Message Request On";
BA_ "SignalType" SG_ 1500 LnKpAsstUnAvIndOn "ENM";
BA_ "SignalLongName" SG_ 1500 LnKpAsstUnAvIndOn "Lane Keep Assist Unavailable Indication On";
BA_ "SignalType" SG_ 1500 LnDprtrWrngUnAvIndOn "ENM";
BA_ "SignalLongName" SG_ 1500 LnDprtrWrngUnAvIndOn "Lane Departure Warning Unavailable Indication On";
BA_ "SignalType" SG_ 1500 FrwdClsnSysIndOn "ENM";
BA_ "SignalLongName" SG_ 1500 FrwdClsnSysIndOn "Forward Collision System Indication On";
BA_ "SignalType" SG_ 1500 FrwdCllsnSysUnIndOn "ENM";
BA_ "SignalLongName" SG_ 1500 FrwdCllsnSysUnIndOn "Forward Collision System Unavailable Indication On";
BA_ "SignalType" SG_ 1500 FrwdCllsnSysRdIndOn "ENM";
BA_ "SignalLongName" SG_ 1500 FrwdCllsnSysRdIndOn "Forward Collision System Reduced Indication On";
BA_ "SignalType" SG_ 1500 FrwdCllsnSysOffIndOn "ENM";
BA_ "SignalLongName" SG_ 1500 FrwdCllsnSysOffIndOn "Forward Collision System Off Indication On";
BA_ "SignalType" SG_ 1500 FrwdCllsnAlrtOffIndOn "ENM";
BA_ "SignalLongName" SG_ 1500 FrwdCllsnAlrtOffIndOn "Forward Collision Alert Off Indication On";
BA_ "SignalType" SG_ 1500 TnDrvGapAdjUnvIndOn "ENM";
BA_ "SignalLongName" SG_ 1500 TnDrvGapAdjUnvIndOn "Teen Driver Gap Adjust Unavailable Indication On";
BA_ "SignalType" SG_ 1500 TeenDrvrLnDprtrWrnOffUnvIndOn "ENM";
BA_ "SignalLongName" SG_ 1500 TeenDrvrLnDprtrWrnOffUnvIndOn "Teen Driver Lane Departure Warning Off Unavailable Indication On";
BA_ "SignalType" SG_ 1500 SrvFrwdCllsnSysIndOn "ENM";
BA_ "SignalLongName" SG_ 1500 SrvFrwdCllsnSysIndOn "Service Forward Collision System Indication On";
BA_ "SignalType" SG_ 941 HstVehTrlrDtd "ENM";
BA_ "SignalLongName" SG_ 941 HstVehTrlrDtd "Host Vehicle Trailer Detected";
BA_ "SignalType" SG_ 1261 Sig6920 "ENM";
BA_ "SignalLongName" SG_ 1261 Sig6920 "Signal6937";
BA_ "SignalLongName" SG_ 1261 Sig6919 "Signal6936";
BA_ "SignalLongName" SG_ 1261 Sig6922 "Signal6939";
BA_ "SignalType" SG_ 1261 Sig6921 "ENM";
BA_ "SignalLongName" SG_ 1261 Sig6921 "Signal6938";
BA_ "SignalLongName" SG_ 1261 Sig6926 "Signal6943";
BA_ "SignalType" SG_ 1261 Sig6924 "ENM";
BA_ "SignalLongName" SG_ 1261 Sig6924 "Signal6941";
BA_ "SignalType" SG_ 1261 Sig6923 "ENM";
BA_ "SignalLongName" SG_ 1261 Sig6923 "Signal6940";
BA_ "SignalLongName" SG_ 1261 Sig6929 "Signal6946";
BA_ "SignalType" SG_ 1261 Sig6928 "ENM";
BA_ "SignalLongName" SG_ 1261 Sig6928 "Signal6945";
BA_ "SignalType" SG_ 1261 Sig6927 "ENM";
BA_ "SignalLongName" SG_ 1261 Sig6927 "Signal6944";
BA_ "SignalLongName" SG_ 1261 Sig6932 "Signal6949";
BA_ "SignalType" SG_ 1261 Sig6931 "ENM";
BA_ "SignalLongName" SG_ 1261 Sig6931 "Signal6948";
BA_ "SignalType" SG_ 1261 Sig6930 "ENM";
BA_ "SignalLongName" SG_ 1261 Sig6930 "Signal6947";
BA_ "SignalLongName" SG_ 1261 Sig6925 "Signal6942";
BA_ "SignalType" SG_ 1261 Sig6934 "ENM";
BA_ "SignalLongName" SG_ 1261 Sig6934 "Signal6951";
BA_ "SignalType" SG_ 1261 Sig6933 "ENM";
BA_ "SignalLongName" SG_ 1261 Sig6933 "Signal6950";
BA_ "SignalLongName" SG_ 1261 Sig6935 "Signal6952";
BA_ "SignalLongName" SG_ 1261 Sig6954 "Signal6970";
BA_ "SignalLongName" SG_ 1261 Sig6955 "Signal6971";
BA_ "SignalType" SG_ 1418 LSCMB_BrkPrfllReq "ENM";
BA_ "SignalLongName" SG_ 1418 LSCMB_BrkPrfllReq "LSCMB Brake Prefill Request";
BA_ "SignalType" SG_ 1418 Sig4119 "ENM";
BA_ "SignalLongName" SG_ 1418 Sig4119 "Signal4055";
BA_ "SignalLongName" SG_ 735 FOPPriGridVltgTgt "Fail Operational Power Primary Grid Voltage Target";
BA_ "SignalLongName" SG_ 735 FOPSecGridVltgCmnd "Fail Operational Power Secondary Grid Voltage Commanded";
BA_ "SignalType" SG_ 735 FOPPriGridVltgOvrrdPrty "ENM";
BA_ "SignalLongName" SG_ 735 FOPPriGridVltgOvrrdPrty "Fail Operational Power Primary Grid Voltage Override Priority";
BA_ "SignalType" SG_ 735 Sig3234 "ENM";
BA_ "SignalLongName" SG_ 735 Sig3234 "Signal3215";
BA_ "SignalType" SG_ 735 FOPGridIsltnSwStat "ENM";
BA_ "SignalLongName" SG_ 735 FOPGridIsltnSwStat "Fail Operational Power Grid Isolation Switch State";
BA_ "SignalType" SG_ 735 Sig3237 "ENM";
BA_ "SignalLongName" SG_ 735 Sig3237 "Signal3219";
BA_ "SignalType" SG_ 735 Sig3236 "ENM";
BA_ "SignalLongName" SG_ 735 Sig3236 "Signal3216";
BA_ "SignalType" SG_ 735 EE46ecGridVltgOvrrdActv "ENM";
BA_ "SignalLongName" SG_ 735 EE46ecGridVltgOvrrdActv "Electrical Power Management Secondary Grid Voltage Override Active";
BA_ "SignalLongName" SG_ 663 LIB1PackIntrnlVltg "Lithium Ion Battery1 Pack Internal Voltage";
BA_ "SignalType" SG_ 663 LIB1PackIntrnlVltg_Inv "ENM";
BA_ "SignalLongName" SG_ 663 LIB1PackIntrnlVltg_Inv "Lithium Ion Battery1 Pack Internal Voltage Invalid";
BA_ "SignalLongName" SG_ 663 LIB1CellMaxVltg "Lithium Ion Battery 1 Cell Maximum Voltage";
BA_ "SignalType" SG_ 663 LIB1CellMaxVltg_Inv "ENM";
BA_ "SignalLongName" SG_ 663 LIB1CellMaxVltg_Inv "Lithium Ion Battery 1 Cell Maximum Voltage Invalid";
BA_ "SignalType" SG_ 663 LIB1CellMaxVltg_DuD "ENM";
BA_ "SignalLongName" SG_ 663 LIB1CellMaxVltg_DuD "Lithium Ion Battery 1 Cell Maximum Voltage Don't Use Data";
BA_ "SignalLongName" SG_ 663 LIB1CellMinVltg "Lithium Ion Battery1 Cell Minimum Voltage";
BA_ "SignalType" SG_ 663 LIB1CellMinVltg_Inv "ENM";
BA_ "SignalLongName" SG_ 663 LIB1CellMinVltg_Inv "Lithium Ion Battery1 Cell Minimum Voltage Invalid";
BA_ "SignalLongName" SG_ 663 LIB1SOH "Lithium Ion Battery1 State Of Health";
BA_ "SignalType" SG_ 663 LIB1SOH_Inv "ENM";
BA_ "SignalLongName" SG_ 663 LIB1SOH_Inv "Lithium Ion Battery1 State Of Health Invalid";
BA_ "SignalLongName" SG_ 663 Sig3999 "Signal4346";
BA_ "SignalType" SG_ 663 Sig4000 "ENM";
BA_ "SignalLongName" SG_ 663 Sig4000 "Signal4347";
BA_ "SignalLongName" SG_ 663 Sig4001 "Signal4348";
BA_ "SignalType" SG_ 663 Sig4002 "ENM";
BA_ "SignalLongName" SG_ 663 Sig4002 "Signal4349";
BA_ "SignalLongName" SG_ 663 Sig4005 "Signal4352";
BA_ "SignalType" SG_ 663 Sig4006 "ENM";
BA_ "SignalLongName" SG_ 663 Sig4006 "Signal4353";
BA_ "SignalLongName" SG_ 663 Sig4003 "Signal4350";
BA_ "SignalType" SG_ 663 Sig4004 "ENM";
BA_ "SignalLongName" SG_ 663 Sig4004 "Signal4351";
BA_ "SignalType" SG_ 663 LIB1CntctrSlfTstRslts "ENM";
BA_ "SignalLongName" SG_ 663 LIB1CntctrSlfTstRslts "Lithium Ion Battery 1 Contactor Self Test Results";
BA_ "SignalType" SG_ 663 LIB1CntctrSlfTstRslts_Inv "ENM";
BA_ "SignalLongName" SG_ 663 LIB1CntctrSlfTstRslts_Inv "Lithium Ion Battery 1 Contactor Self Test Results Invalid";
BA_ "SignalType" SG_ 663 LIB1EOLFlt "ENM";
BA_ "SignalLongName" SG_ 663 LIB1EOLFlt "Lithium Ion Battery 1 End Of Life Fault";
BA_ "SignalType" SG_ 663 LIB1EOLFlt_Inv "ENM";
BA_ "SignalLongName" SG_ 663 LIB1EOLFlt_Inv "Lithium Ion Battery 1 End Of Life Fault Invalid";
BA_ "SignalType" SG_ 663 LIB1TempFlt_Inv "ENM";
BA_ "SignalLongName" SG_ 663 LIB1TempFlt_Inv "Lithium Ion Battery 1 Temperature Fault Invalid";
BA_ "SignalType" SG_ 663 LIB1TempFlt_DuD "ENM";
BA_ "SignalLongName" SG_ 663 LIB1TempFlt_DuD "Lithium Ion Battery 1 Temperature Fault Don't Use Data";
BA_ "SignalType" SG_ 663 LIB1TempFlt "ENM";
BA_ "SignalLongName" SG_ 663 LIB1TempFlt "Lithium Ion Battery 1 Temperature Fault";
BA_ "SignalType" SG_ 663 LIB1CurrFlt "ENM";
BA_ "SignalLongName" SG_ 663 LIB1CurrFlt "Lithium Ion Battery 1 Current Fault";
BA_ "SignalType" SG_ 663 LIB1CurrFlt_Inv "ENM";
BA_ "SignalLongName" SG_ 663 LIB1CurrFlt_Inv "Lithium Ion Battery 1 Current Fault Invalid";
BA_ "SignalType" SG_ 663 Sig3997 "ENM";
BA_ "SignalLongName" SG_ 663 Sig3997 "Signal4291";
BA_ "SignalType" SG_ 663 Sig3998 "ENM";
BA_ "SignalLongName" SG_ 663 Sig3998 "Signal4292";
BA_ "SignalType" SG_ 1807 LIB1SOCReconfRdnes_Inv "ENM";
BA_ "SignalLongName" SG_ 1807 LIB1SOCReconfRdnes_Inv "Lithium Ion Battery 1 State Of Charge Reconfirmation Readiness Invalid";
BA_ "SignalType" SG_ 1807 LIB1SOCReconfRdnes_DuD "ENM";
BA_ "SignalLongName" SG_ 1807 LIB1SOCReconfRdnes_DuD "Lithium Ion Battery 1 State Of Charge Reconfirmation Readiness Don't Use Data";
BA_ "SignalType" SG_ 1807 LIB1SOCReconfRdnes "ENM";
BA_ "SignalLongName" SG_ 1807 LIB1SOCReconfRdnes "Lithium Ion Battery 1 State Of Charge Reconfirmation Readiness";
BA_ "SignalLongName" SG_ 1433 NtVsnObjMsg "Night Vision Object Message";
BA_ "SignalType" SG_ 1433 Sig4422 "ENM";
BA_ "SignalLongName" SG_ 1433 Sig4422 "Signal4613";
BA_ "SignalType" SG_ 1433 Sig4420 "ENM";
BA_ "SignalLongName" SG_ 1433 Sig4420 "Signal4611";
BA_ "SignalType" SG_ 1433 NghtVsnSysStat "ENM";
BA_ "SignalLongName" SG_ 1433 NghtVsnSysStat "Night Vision System Status";
BA_ "SignalType" SG_ 1433 Sig4418 "ENM";
BA_ "SignalLongName" SG_ 1433 Sig4418 "Signal4609";
BA_ "SignalType" SG_ 1433 Sig4419 "ENM";
BA_ "SignalLongName" SG_ 1433 Sig4419 "Signal4610";
BA_ "SignalType" SG_ 1433 NtVsnAnmlWrnIndReq "ENM";
BA_ "SignalLongName" SG_ 1433 NtVsnAnmlWrnIndReq "Night Vision Animal Warning Indication Request";
BA_ "SignalType" SG_ 1433 NghtVsnPdWrnIndRqst "ENM";
BA_ "SignalLongName" SG_ 1433 NghtVsnPdWrnIndRqst "Night Vision Pedestrian Warning Indication Request";
BA_ "SignalLongName" SG_ 1434 Sig8061 "Signal3248";
BA_ "SignalType" SG_ 1434 Sig3405 "ENM";
BA_ "SignalLongName" SG_ 1434 Sig3405 "Signal3247";
BA_ "SignalLongName" SG_ 1502 SecAxl4WDAWDThrCap "Secondary Axle 4WD AWD Thermal Capacity";
BA_ "SignalType" SG_ 1502 SecAxlThrmCapPrtRqAct "ENM";
BA_ "SignalLongName" SG_ 1502 SecAxlThrmCapPrtRqAct "Secondary Axle Thermal Capacity Protection Request Active";
BA_ "SignalLongName" SG_ 111 Sig7791 "Signal7758";
BA_ "SignalType" SG_ 111 Sig7793 "ENM";
BA_ "SignalLongName" SG_ 111 Sig7793 "Signal7759";
BA_ "SignalLongName" SG_ 111 Sig7794 "Signal7761";
BA_ "SignalType" SG_ 111 Sig7795 "ENM";
BA_ "SignalLongName" SG_ 111 Sig7795 "Signal7762";
BA_ "SignalLongName" SG_ 111 Sig7772 "Signal7716";
BA_ "SignalType" SG_ 111 Sig7773 "ENM";
BA_ "SignalLongName" SG_ 111 Sig7773 "Signal7717";
BA_ "SignalLongName" SG_ 111 Sig0609 "Signal0562";
BA_ "SignalLongName" SG_ 111 Sig0610 "Signal0563";
BA_ "SignalLongName" SG_ 111 Sig7629 "Signal7720";
BA_ "SignalType" SG_ 111 Sig7792 "ENM";
BA_ "SignalLongName" SG_ 111 Sig7792 "Signal7760";
BA_ "SignalType" SG_ 111 AtTrnsGrSftDrct "ENM";
BA_ "SignalLongName" SG_ 111 AtTrnsGrSftDrct "Automatic Transmission Gear Shift Direction";
BA_ "SignalType" SG_ 196 Sig0589 "ENM";
BA_ "SignalLongName" SG_ 196 Sig0589 "Signal0553";
BA_ "SignalType" SG_ 196 Sig0588 "ENM";
BA_ "SignalLongName" SG_ 196 Sig0588 "Signal0552";
BA_ "SignalType" SG_ 196 Sig0587 "ENM";
BA_ "SignalLongName" SG_ 196 Sig0587 "Signal0551";
BA_ "SignalType" SG_ 196 Sig0586 "ENM";
BA_ "SignalLongName" SG_ 196 Sig0586 "Signal0550";
BA_ "SignalType" SG_ 196 Sig0585 "ENM";
BA_ "SignalLongName" SG_ 196 Sig0585 "Signal0549";
BA_ "SignalType" SG_ 196 Sig0584 "ENM";
BA_ "SignalLongName" SG_ 196 Sig0584 "Signal0548";
BA_ "SignalType" SG_ 196 Sig0583 "ENM";
BA_ "SignalLongName" SG_ 196 Sig0583 "Signal0547";
BA_ "SignalType" SG_ 196 Sig0582 "ENM";
BA_ "SignalLongName" SG_ 196 Sig0582 "Signal0546";
BA_ "SignalType" SG_ 196 Sig0597 "ENM";
BA_ "SignalLongName" SG_ 196 Sig0597 "Signal0561";
BA_ "SignalType" SG_ 196 Sig0596 "ENM";
BA_ "SignalLongName" SG_ 196 Sig0596 "Signal0560";
BA_ "SignalType" SG_ 196 Sig0595 "ENM";
BA_ "SignalLongName" SG_ 196 Sig0595 "Signal0559";
BA_ "SignalType" SG_ 196 Sig0594 "ENM";
BA_ "SignalLongName" SG_ 196 Sig0594 "Signal0558";
BA_ "SignalType" SG_ 196 Sig0593 "ENM";
BA_ "SignalLongName" SG_ 196 Sig0593 "Signal0557";
BA_ "SignalType" SG_ 196 Sig0592 "ENM";
BA_ "SignalLongName" SG_ 196 Sig0592 "Signal0556";
BA_ "SignalType" SG_ 196 Sig0591 "ENM";
BA_ "SignalLongName" SG_ 196 Sig0591 "Signal0555";
BA_ "SignalType" SG_ 196 Sig0590 "ENM";
BA_ "SignalLongName" SG_ 196 Sig0590 "Signal0554";
BA_ "SignalLongName" SG_ 196 Sig7803 "Signal7783";
BA_ "SignalLongName" SG_ 196 Sig7804 "Signal7780";
BA_ "SignalType" SG_ 196 Sig7621 "ENM";
BA_ "SignalLongName" SG_ 196 Sig7621 "Signal7712";
BA_ "SignalType" SG_ 196 Sig7801 "ENM";
BA_ "SignalLongName" SG_ 196 Sig7801 "Signal7781";
BA_ "SignalType" SG_ 196 Sig7802 "ENM";
BA_ "SignalLongName" SG_ 196 Sig7802 "Signal7782";
BA_ "SignalType" SG_ 196 Sig7628 "ENM";
BA_ "SignalLongName" SG_ 196 Sig7628 "Signal7718";
BA_ "SignalType" SG_ 719 Sig7775 "ENM";
BA_ "SignalLongName" SG_ 719 Sig7775 "Signal7721";
BA_ "SignalLongName" SG_ 937 Sig7652 "Signal7784";
BA_ "SignalLongName" SG_ 937 Sig7785 "Signal7748";
BA_ "SignalType" SG_ 937 Sig7784 "ENM";
BA_ "SignalLongName" SG_ 937 Sig7784 "Signal7747";
BA_ "SignalType" SG_ 937 TrnsTUTDMdSt "ENM";
BA_ "SignalLongName" SG_ 937 TrnsTUTDMdSt "Transmission Information 1 : Transmission Tap Up/Tap Down Mode State";
BA_ "SignalType" SG_ 937 Sig2416 "ENM";
BA_ "SignalLongName" SG_ 937 Sig2416 "Signal7745";
BA_ "SignalType" SG_ 937 DrvShftCntrlReqDndIO "ENM";
BA_ "SignalLongName" SG_ 937 DrvShftCntrlReqDndIO "Transmission Information 1 : Driver Shift Control Request Denied Indication On";
BA_ "SignalType" SG_ 937 Sig7796 "ENM";
BA_ "SignalLongName" SG_ 937 Sig7796 "Signal7766";
BA_ "SignalType" SG_ 937 Sig2421 "ENM";
BA_ "SignalLongName" SG_ 937 Sig2421 "Signal2333";
BA_ "SignalType" SG_ 937 Sig7783 "ENM";
BA_ "SignalLongName" SG_ 937 Sig7783 "Signal7746";
BA_ "SignalType" SG_ 937 Sig7643 "ENM";
BA_ "SignalLongName" SG_ 937 Sig7643 "Signal7771";
BA_ "SignalType" SG_ 937 Sig7642 "ENM";
BA_ "SignalLongName" SG_ 937 Sig7642 "Signal7770";
BA_ "SignalType" SG_ 937 Sig7630 "ENM";
BA_ "SignalLongName" SG_ 937 Sig7630 "Signal7725";
BA_ "SignalType" SG_ 937 Sig3595 "ENM";
BA_ "SignalLongName" SG_ 937 Sig3595 "Signal3937";
BA_ "SignalType" SG_ 937 Sig7647 "ENM";
BA_ "SignalLongName" SG_ 937 Sig7647 "Signal7776";
BA_ "SignalType" SG_ 937 Sig7646 "ENM";
BA_ "SignalLongName" SG_ 937 Sig7646 "Signal7774";
BA_ "SignalType" SG_ 937 Sig7645 "ENM";
BA_ "SignalLongName" SG_ 937 Sig7645 "Signal7773";
BA_ "SignalType" SG_ 937 Sig7644 "ENM";
BA_ "SignalLongName" SG_ 937 Sig7644 "Signal7772";
BA_ "SignalType" SG_ 937 Sig7782 "ENM";
BA_ "SignalLongName" SG_ 937 Sig7782 "Signal7744";
BA_ "SignalType" SG_ 937 Sig7774 "ENM";
BA_ "SignalLongName" SG_ 937 Sig7774 "Signal7719";
BA_ "SignalType" SG_ 937 Sig7649 "ENM";
BA_ "SignalLongName" SG_ 937 Sig7649 "Signal7777";
BA_ "SignalType" SG_ 937 Sig7648 "ENM";
BA_ "SignalLongName" SG_ 937 Sig7648 "Signal7775";
BA_ "SignalType" SG_ 937 Sig0436 "ENM";
BA_ "SignalLongName" SG_ 937 Sig0436 "Signal0331";
BA_ "SignalType" SG_ 937 Sig7797 "ENM";
BA_ "SignalLongName" SG_ 937 Sig7797 "Signal7767";
BA_ "SignalType" SG_ 937 Sig7781 "ENM";
BA_ "SignalLongName" SG_ 937 Sig7781 "Signal7729";
BA_ "SignalType" SG_ 937 Sig7779 "ENM";
BA_ "SignalLongName" SG_ 937 Sig7779 "Signal7728";
BA_ "SignalType" SG_ 937 Sig7641 "ENM";
BA_ "SignalLongName" SG_ 937 Sig7641 "Signal7763";
BA_ "SignalType" SG_ 937 Sig7640 "ENM";
BA_ "SignalLongName" SG_ 937 Sig7640 "Signal7765";
BA_ "SignalType" SG_ 937 Sig2588 "ENM";
BA_ "SignalLongName" SG_ 937 Sig2588 "Signal2589";
BA_ "SignalType" SG_ 937 DCTLnchCtlAllwd "ENM";
BA_ "SignalLongName" SG_ 937 DCTLnchCtlAllwd "DCT Launch Control Allowed";
BA_ "SignalLongName" SG_ 1256 Sig7521 "Signal7714";
BA_ "SignalType" SG_ 1256 Sig7520 "ENM";
BA_ "SignalLongName" SG_ 1256 Sig7520 "Signal7713";
BA_ "SignalLongName" SG_ 1256 Sig7522 "Signal7715";
BA_ "SignalLongName" SG_ 1256 Sig7528 "Signal7722";
BA_ "SignalType" SG_ 1256 Sig7529 "ENM";
BA_ "SignalLongName" SG_ 1256 Sig7529 "Signal7723";
BA_ "SignalLongName" SG_ 1256 Sig7638 "Signal7756";
BA_ "SignalLongName" SG_ 1256 Sig7789 "Signal7755";
BA_ "SignalType" SG_ 1256 Sig7639 "ENM";
BA_ "SignalLongName" SG_ 1256 Sig7639 "Signal7764";
BA_ "SignalType" SG_ 1256 Sig3509 "ENM";
BA_ "SignalLongName" SG_ 1256 Sig3509 "Signal3898";
BA_ "SignalType" SG_ 1256 Sig7798 "ENM";
BA_ "SignalLongName" SG_ 1256 Sig7798 "Signal7768";
BA_ "SignalType" SG_ 1256 Sig7650 "ENM";
BA_ "SignalLongName" SG_ 1256 Sig7650 "Signal7778";
BA_ "SignalType" SG_ 1256 Sig7790 "ENM";
BA_ "SignalLongName" SG_ 1256 Sig7790 "Signal7757";
BA_ "SignalType" SG_ 1256 Sig7787 "ENM";
BA_ "SignalLongName" SG_ 1256 Sig7787 "Signal7750";
BA_ "SignalType" SG_ 1256 Sig7776 "ENM";
BA_ "SignalLongName" SG_ 1256 Sig7776 "Signal7724";
BA_ "SignalLongName" SG_ 1258 Sig4463 "Signal5087";
BA_ "SignalType" SG_ 1258 Sig4462 "ENM";
BA_ "SignalLongName" SG_ 1258 Sig4462 "Signal5086";
BA_ "SignalType" SG_ 1258 Sig4461 "ENM";
BA_ "SignalLongName" SG_ 1258 Sig4461 "Signal5085";
BA_ "SignalType" SG_ 737 APMLoVltgEnblCmd "ENM";
BA_ "SignalLongName" SG_ 737 APMLoVltgEnblCmd "Auxiliary Power Module Low Voltage Enable Command";
BA_ "SignalLongName" SG_ 1808 VICMERDTC_CdNum "Vehicle Integrated Control Module Emissions Related DTC : Code Number";
BA_ "SignalType" SG_ 1808 VICMERDTC_SysDes "ENM";
BA_ "SignalLongName" SG_ 1808 VICMERDTC_SysDes "Vehicle Integrated Control Module Emissions Related DTC : System Designator";
BA_ "SignalType" SG_ 1808 VICMEmsRltMlfAtv "ENM";
BA_ "SignalLongName" SG_ 1808 VICMEmsRltMlfAtv "Vehicle Integrated Control Module Emissions Related Malfunction Active";
BA_ "SignalLongName" SG_ 1808 PIMRI_VICM_RcntlyProgInd "Programming Inspection and Maintenance Readiness Indication - VICM : Recently Programmed Indicator";
BA_ "SignalType" SG_ 1808 PIMRI_VICM_PrmntDTCInd "ENM";
BA_ "SignalLongName" SG_ 1808 PIMRI_VICM_PrmntDTCInd "Programming Inspection and Maintenance Readiness Indication - VICM : Permanent DTC Indicator";
BA_ "SignalType" SG_ 1808 PIMRI_VICM_FltsPrsntInd "ENM";
BA_ "SignalLongName" SG_ 1808 PIMRI_VICM_FltsPrsntInd "Programming Inspection and Maintenance Readiness Indication - VICM : Faults Present Indicator";
BA_ "SignalType" SG_ 1469 SuprCruzSbscrptnActv "ENM";
BA_ "SignalLongName" SG_ 1469 SuprCruzSbscrptnActv "Super Cruise Subscription Active";
BA_ "SignalLongName" SG_ 1482 VehMassEst "Vehicle Mass Estimate";
BA_ "SignalType" SG_ 1482 AutoVehMdCmdMdReqd "ENM";
BA_ "SignalLongName" SG_ 1482 AutoVehMdCmdMdReqd "Automatic Vehicle Mode Command Mode Requested";
BA_ "SignalType" SG_ 1482 BrkSysAirDflctrCoolReq "ENM";
BA_ "SignalLongName" SG_ 1482 BrkSysAirDflctrCoolReq "Brake System Air Deflector Cooling Request";
BA_ "SignalType" SG_ 1482 ActvAerodynsPerfModeReq "ENM";
BA_ "SignalLongName" SG_ 1482 ActvAerodynsPerfModeReq "Active Aerodynamics Performance Mode Request";
BA_ "SignalType" SG_ 1482 TrcCntrlSysPr "ENM";
BA_ "SignalLongName" SG_ 1482 TrcCntrlSysPr "Traction Control System Present";
BA_ "SignalType" SG_ 1482 CustmStbCtlRdctReqIndOn "ENM";
BA_ "SignalLongName" SG_ 1482 CustmStbCtlRdctReqIndOn "Custom Stability Control Reduction Request Indication On";
BA_ "SignalType" SG_ 1482 ABSPr "ENM";
BA_ "SignalLongName" SG_ 1482 ABSPr "Antilock Brake System Present";
BA_ "SignalType" SG_ 1482 VehMassEstSts "ENM";
BA_ "SignalLongName" SG_ 1482 VehMassEstSts "Vehicle Mass Estimate Status";
BA_ "SignalLongName" SG_ 1805 Sig1070 "Signal2257";
BA_ "SignalLongName" SG_ 1805 Sig1071 "Signal2258";
BA_ "SignalLongName" SG_ 1805 Sig1072 "Signal2259";
BA_ "SignalLongName" SG_ 1805 Sig3487 "Signal3493";
BA_ "SignalLongName" SG_ 1805 Sig3488 "Signal3494";
BA_ "SignalLongName" SG_ 1805 EngOilTmp "Engine Oil Temperature";
BA_ "SignalType" SG_ 1805 EngOilTmp_Inv "ENM";
BA_ "SignalLongName" SG_ 1805 EngOilTmp_Inv "Engine Oil Temperature Invalid";
BA_ "SignalType" SG_ 1805 Sig7579 "ENM";
BA_ "SignalLongName" SG_ 1805 Sig7579 "Signal7558";
BA_ "SignalType" SG_ 1805 Sig3481 "ENM";
BA_ "SignalLongName" SG_ 1805 Sig3481 "Signal3339";
BA_ "SignalType" SG_ 1487 Sig2442 "ENM";
BA_ "SignalLongName" SG_ 1487 Sig2442 "Signal2266";
BA_ "SignalType" SG_ 1487 Sig2441 "ENM";
BA_ "SignalLongName" SG_ 1487 Sig2441 "Signal2260";
BA_ "SignalType" SG_ 1487 Sig2447 "ENM";
BA_ "SignalLongName" SG_ 1487 Sig2447 "Signal2263";
BA_ "SignalType" SG_ 1487 Sig2443 "ENM";
BA_ "SignalLongName" SG_ 1487 Sig2443 "Signal2267";
BA_ "SignalLongName" SG_ 1487 Sig2450 "Signal2264";
BA_ "SignalType" SG_ 1487 Sig2451 "ENM";
BA_ "SignalLongName" SG_ 1487 Sig2451 "Signal2265";
BA_ "SignalLongName" SG_ 1487 Sig2453 "Signal2261";
BA_ "SignalType" SG_ 1487 Sig2452 "ENM";
BA_ "SignalLongName" SG_ 1487 Sig2452 "Signal2262";
BA_ "SignalType" SG_ 1487 Sig0309 "ENM";
BA_ "SignalLongName" SG_ 1487 Sig0309 "Signal0316";
BA_ "SignalType" SG_ 1487 Sig0308 "ENM";
BA_ "SignalLongName" SG_ 1487 Sig0308 "Signal0315";
BA_ "SignalType" SG_ 1487 Sig0307 "ENM";
BA_ "SignalLongName" SG_ 1487 Sig0307 "Signal0314";
BA_ "SignalType" SG_ 1487 Sig0306 "ENM";
BA_ "SignalLongName" SG_ 1487 Sig0306 "Signal0313";
BA_ "SignalType" SG_ 1487 Sig0305 "ENM";
BA_ "SignalLongName" SG_ 1487 Sig0305 "Signal0312";
BA_ "SignalType" SG_ 1487 Sig0626 "ENM";
BA_ "SignalLongName" SG_ 1487 Sig0626 "Signal0520";
BA_ "SignalType" SG_ 1487 Sig0614 "ENM";
BA_ "SignalLongName" SG_ 1487 Sig0614 "Signal0502";
BA_ "SignalType" SG_ 1487 Sig0434 "ENM";
BA_ "SignalLongName" SG_ 1487 Sig0434 "Signal0229";
BA_ "SignalType" SG_ 1487 Sig0312 "ENM";
BA_ "SignalLongName" SG_ 1487 Sig0312 "Signal0319";
BA_ "SignalType" SG_ 1487 Sig0311 "ENM";
BA_ "SignalLongName" SG_ 1487 Sig0311 "Signal0318";
BA_ "SignalType" SG_ 1487 Sig0310 "ENM";
BA_ "SignalLongName" SG_ 1487 Sig0310 "Signal0317";
BA_ "SignalType" SG_ 1488 Sig4815 "ENM";
BA_ "SignalLongName" SG_ 1488 Sig4815 "Signal4999";
BA_ "SignalType" SG_ 1488 Sig4610 "ENM";
BA_ "SignalLongName" SG_ 1488 Sig4610 "Signal4917";
BA_ "SignalType" SG_ 1488 Sig4250 "ENM";
BA_ "SignalLongName" SG_ 1488 Sig4250 "Signal4376";
BA_ "SignalType" SG_ 1488 Sig2586 "ENM";
BA_ "SignalLongName" SG_ 1488 Sig2586 "Signal2581";
BA_ "SignalType" SG_ 1488 Sig4838 "ENM";
BA_ "SignalLongName" SG_ 1488 Sig4838 "Signal5020";
BA_ "SignalType" SG_ 1488 Sig4885 "ENM";
BA_ "SignalLongName" SG_ 1488 Sig4885 "Signal5047";
BA_ "SignalType" SG_ 1488 Sig4863 "ENM";
BA_ "SignalLongName" SG_ 1488 Sig4863 "Signal5034";
BA_ "SignalType" SG_ 1488 Sig2621 "ENM";
BA_ "SignalLongName" SG_ 1488 Sig2621 "Signal2626";
BA_ "SignalType" SG_ 1488 Sig2620 "ENM";
BA_ "SignalLongName" SG_ 1488 Sig2620 "Signal2627";
BA_ "SignalType" SG_ 1488 Sig4689 "ENM";
BA_ "SignalLongName" SG_ 1488 Sig4689 "Signal4935";
BA_ "SignalType" SG_ 1488 Sig4638 "ENM";
BA_ "SignalLongName" SG_ 1488 Sig4638 "Signal4901";
BA_ "SignalType" SG_ 1488 Sig4627 "ENM";
BA_ "SignalLongName" SG_ 1488 Sig4627 "Signal4925";
BA_ "SignalType" SG_ 1488 Sig2671 "ENM";
BA_ "SignalLongName" SG_ 1488 Sig2671 "Signal2687";
BA_ "SignalType" SG_ 1488 Sig2668 "ENM";
BA_ "SignalLongName" SG_ 1488 Sig2668 "Signal2674";
BA_ "SignalType" SG_ 1488 Sig2667 "ENM";
BA_ "SignalLongName" SG_ 1488 Sig2667 "Signal2673";
BA_ "SignalType" SG_ 1488 Sig2644 "ENM";
BA_ "SignalLongName" SG_ 1488 Sig2644 "Signal2650";
BA_ "SignalType" SG_ 1488 Sig2641 "ENM";
BA_ "SignalLongName" SG_ 1488 Sig2641 "Signal2648";
BA_ "SignalType" SG_ 1488 Sig2639 "ENM";
BA_ "SignalLongName" SG_ 1488 Sig2639 "Signal2644";
BA_ "SignalType" SG_ 1488 Sig2637 "ENM";
BA_ "SignalLongName" SG_ 1488 Sig2637 "Signal2643";
BA_ "SignalType" SG_ 1488 Sig2636 "ENM";
BA_ "SignalLongName" SG_ 1488 Sig2636 "Signal2642";
BA_ "SignalType" SG_ 1488 Sig4675 "ENM";
BA_ "SignalLongName" SG_ 1488 Sig4675 "Signal4932";
BA_ "SignalType" SG_ 1488 Sig4636 "ENM";
BA_ "SignalLongName" SG_ 1488 Sig4636 "Signal4900";
BA_ "SignalType" SG_ 1488 Sig4629 "ENM";
BA_ "SignalLongName" SG_ 1488 Sig4629 "Signal4927";
BA_ "SignalType" SG_ 1488 Sig4612 "ENM";
BA_ "SignalLongName" SG_ 1488 Sig4612 "Signal4919";
BA_ "SignalType" SG_ 1488 Sig4539 "ENM";
BA_ "SignalLongName" SG_ 1488 Sig4539 "Signal4731";
BA_ "SignalType" SG_ 1488 Sig4496 "ENM";
BA_ "SignalLongName" SG_ 1488 Sig4496 "Signal4705";
BA_ "SignalType" SG_ 1488 Sig4481 "ENM";
BA_ "SignalLongName" SG_ 1488 Sig4481 "Signal5064";
BA_ "SignalType" SG_ 1488 Sig4479 "ENM";
BA_ "SignalLongName" SG_ 1488 Sig4479 "Signal5062";
BA_ "SignalType" SG_ 1488 Sig4840 "ENM";
BA_ "SignalLongName" SG_ 1488 Sig4840 "Signal5022";
BA_ "SignalType" SG_ 1488 Sig4817 "ENM";
BA_ "SignalLongName" SG_ 1488 Sig4817 "Signal5001";
BA_ "SignalType" SG_ 1488 Sig4798 "ENM";
BA_ "SignalLongName" SG_ 1488 Sig4798 "Signal4983";
BA_ "SignalType" SG_ 1488 Sig4730 "ENM";
BA_ "SignalLongName" SG_ 1488 Sig4730 "Signal4952";
BA_ "SignalType" SG_ 1488 Sig4728 "ENM";
BA_ "SignalLongName" SG_ 1488 Sig4728 "Signal4951";
BA_ "SignalType" SG_ 1488 Sig4726 "ENM";
BA_ "SignalLongName" SG_ 1488 Sig4726 "Signal4950";
BA_ "SignalType" SG_ 1488 Sig4712 "ENM";
BA_ "SignalLongName" SG_ 1488 Sig4712 "Signal4949";
BA_ "SignalType" SG_ 1488 Sig4691 "ENM";
BA_ "SignalLongName" SG_ 1488 Sig4691 "Signal4937";
BA_ "SignalType" SG_ 1488 Sig7799 "ENM";
BA_ "SignalLongName" SG_ 1488 Sig7799 "Signal7769";
BA_ "SignalType" SG_ 1488 Sig6769 "ENM";
BA_ "SignalLongName" SG_ 1488 Sig6769 "Signal6776";
BA_ "SignalType" SG_ 1488 Sig4906 "ENM";
BA_ "SignalLongName" SG_ 1488 Sig4906 "Signal5072";
BA_ "SignalType" SG_ 1488 Sig4893 "ENM";
BA_ "SignalLongName" SG_ 1488 Sig4893 "Signal5053";
BA_ "SignalType" SG_ 1488 Sig4887 "ENM";
BA_ "SignalLongName" SG_ 1488 Sig4887 "Signal5049";
BA_ "SignalType" SG_ 1488 Sig4865 "ENM";
BA_ "SignalLongName" SG_ 1488 Sig4865 "Signal5036";
BA_ "SignalType" SG_ 1488 Sig4846 "ENM";
BA_ "SignalLongName" SG_ 1488 Sig4846 "Signal5026";
BA_ "SignalType" SG_ 939 TrcCntrlSysEnbld "ENM";
BA_ "SignalLongName" SG_ 939 TrcCntrlSysEnbld "Traction Control System Enabled";
BA_ "SignalType" SG_ 939 EnhdDrvrSeltdMdSwChsUseReq "ENM";
BA_ "SignalLongName" SG_ 939 EnhdDrvrSeltdMdSwChsUseReq "Enhanced Driver Selected Mode Switch Chassis Use Request";
BA_ "SignalType" SG_ 939 AutoVehMdCmdMdFtrEnbld "ENM";
BA_ "SignalLongName" SG_ 939 AutoVehMdCmdMdFtrEnbld "Automatic Vehicle Mode Command Mode Feature Enabled";
BA_ "SignalLongName" SG_ 711 EngIntAirTmp "Serial Data 119 : Engine Intake Air Temperature";
BA_ "SignalLongName" SG_ 711 ThrPstn "Throttle Position";
BA_ "SignalType" SG_ 711 ThrPstn_Inv "ENM";
BA_ "SignalLongName" SG_ 711 ThrPstn_Inv "Throttle Position Invalid";
BA_ "SignalType" SG_ 711 EngIntAirTmp_Inv "ENM";
BA_ "SignalLongName" SG_ 711 EngIntAirTmp_Inv "Serial Data 119 : Engine Intake Air Temperature Invalid";
BA_ "SignalType" SG_ 711 EngIntAirTmp_DuD "ENM";
BA_ "SignalLongName" SG_ 711 EngIntAirTmp_DuD "Serial Data 119 : Engine Intake Air Temperature Don't Use Data";
BA_ "SignalLongName" SG_ 711 ACCmpNrmLdGrdAld "Air Conditioning Compressor Normalized Load Gradient Allowed";
BA_ "SignalType" SG_ 711 HybStatElecVehModeOvrrd "ENM";
BA_ "SignalLongName" SG_ 711 HybStatElecVehModeOvrrd "Hybrid State Electric Vehicle Mode Override";
BA_ "SignalType" SG_ 711 EngCntrlDtrmdTrfCRng "ENM";
BA_ "SignalLongName" SG_ 711 EngCntrlDtrmdTrfCRng "Engine Controller Determined Transfer Case Range";
BA_ "SignalType" SG_ 711 EngCntrlDtrmdTrfCRng_Inv "ENM";
BA_ "SignalLongName" SG_ 711 EngCntrlDtrmdTrfCRng_Inv "Engine Controller Determined Transfer Case Range Invalid";
BA_ "SignalLongName" SG_ 711 Sig5629 "Signal5510";
BA_ "SignalType" SG_ 711 PTHiElecLdReqd "ENM";
BA_ "SignalLongName" SG_ 711 PTHiElecLdReqd "Powertrain High Electrical Load Requested";
BA_ "SignalType" SG_ 711 ACCmCltEngd "ENM";
BA_ "SignalLongName" SG_ 711 ACCmCltEngd "Air Conditioning Compressor Clutch Engaged";
BA_ "SignalType" SG_ 711 HybStatShtlModeOvrrd "ENM";
BA_ "SignalLongName" SG_ 711 HybStatShtlModeOvrrd "Hybrid State Shuttle Mode Override";
BA_ "SignalLongName" SG_ 1489 EngInltSpcfcHmdty "Engine Inlet Specific Humidity";
BA_ "SignalLongName" SG_ 1489 ArbdEngTemp "Arbitrated Engine Temperature";
BA_ "SignalType" SG_ 1489 ArbdEngTemp_Inv "ENM";
BA_ "SignalLongName" SG_ 1489 ArbdEngTemp_Inv "Arbitrated Engine Temperature Invalid";
BA_ "SignalType" SG_ 1489 EngInltSpcfcHmdty_Inv "ENM";
BA_ "SignalLongName" SG_ 1489 EngInltSpcfcHmdty_Inv "Engine Inlet Specific Humidity Invalid";
BA_ "SignalType" SG_ 1489 EngInltSpcfcHmdty_DuD "ENM";
BA_ "SignalLongName" SG_ 1489 EngInltSpcfcHmdty_DuD "Engine Inlet Specific Humidity Don't Use Data";
BA_ "SignalType" SG_ 1489 SmrtCoolFan2FltActv "ENM";
BA_ "SignalLongName" SG_ 1489 SmrtCoolFan2FltActv "Smart Cooling Fan 2 Fault Active";
BA_ "SignalType" SG_ 1489 SmrtCoolFan1FltActv "ENM";
BA_ "SignalLongName" SG_ 1489 SmrtCoolFan1FltActv "Smart Cooling Fan 1 Fault Active";
BA_ "SignalType" SG_ 1489 EngCstFlCtOffAct "ENM";
BA_ "SignalLongName" SG_ 1489 EngCstFlCtOffAct "Engine Coast Fuel Cut Off Active";
BA_ "SignalType" SG_ 85 CSTATRS_ReqSts "ENM";
BA_ "SignalLongName" SG_ 85 CSTATRS_ReqSts "Chassis System Total Axle Torque Request Status : Request Status";
BA_ "SignalLongName" SG_ 85 CSTATRS_PV "Chassis System Total Axle Torque Request Status : Protection Value";
BA_ "SignalLongName" SG_ 85 CSTATRS_ARC "Chassis System Total Axle Torque Request Status : Alive Rolling Count";
BA_ "SignalType" SG_ 1260 OTARC_RejCrdntnECP_X1 "ENM";
BA_ "SignalLongName" SG_ 1260 OTARC_RejCrdntnECP_X1 "Over The Air Reject Coordination : Reject Coordination ECP_X1";
BA_ "SignalType" SG_ 1260 OTARC_RejCrdntnECP_S "ENM";
BA_ "SignalLongName" SG_ 1260 OTARC_RejCrdntnECP_S "Over The Air Reject Coordination : Reject Coordination ECP_S";
BA_ "SignalType" SG_ 1260 OTARC_RejCrdntnECP_MC "ENM";
BA_ "SignalLongName" SG_ 1260 OTARC_RejCrdntnECP_MC "Over The Air Reject Coordination : Reject Coordination ECP_MC";
BA_ "SignalType" SG_ 1260 OTARC_RejCrdntnECM "ENM";
BA_ "SignalLongName" SG_ 1260 OTARC_RejCrdntnECM "Over The Air Reject Coordination : Reject Coordination ECM";
BA_ "SignalType" SG_ 1260 OTARC_RejCrdntnEBCM "ENM";
BA_ "SignalLongName" SG_ 1260 OTARC_RejCrdntnEBCM "Over The Air Reject Coordination : Reject Coordination EBCM";
BA_ "SignalType" SG_ 1260 OTARC_RejCrdntnBSM_MH "ENM";
BA_ "SignalLongName" SG_ 1260 OTARC_RejCrdntnBSM_MH "Over The Air Reject Coordination : Reject Coordination BSM_MH";
BA_ "SignalType" SG_ 1260 OTARC_RejCrdntnBSM "ENM";
BA_ "SignalLongName" SG_ 1260 OTARC_RejCrdntnBSM "Over The Air Reject Coordination : Reject Coordination BSM";
BA_ "SignalType" SG_ 1260 OTARC_RejCrdntnBCM "ENM";
BA_ "SignalLongName" SG_ 1260 OTARC_RejCrdntnBCM "Over The Air Reject Coordination : Reject Coordination BCM";
BA_ "SignalType" SG_ 1260 OTARC_RejCrdntnECU_19 "ENM";
BA_ "SignalLongName" SG_ 1260 OTARC_RejCrdntnECU_19 "Over The Air Reject Coordination : Reject Coordination ECU_19";
BA_ "SignalType" SG_ 1260 OTARC_RejCrdntnECU_18 "ENM";
BA_ "SignalLongName" SG_ 1260 OTARC_RejCrdntnECU_18 "Over The Air Reject Coordination : Reject Coordination ECU_18";
BA_ "SignalType" SG_ 1260 OTARC_RejCrdntnECU_17 "ENM";
BA_ "SignalLongName" SG_ 1260 OTARC_RejCrdntnECU_17 "Over The Air Reject Coordination : Reject Coordination ECU_17";
BA_ "SignalType" SG_ 1260 OTARC_RejCrdntnECU_16 "ENM";
BA_ "SignalLongName" SG_ 1260 OTARC_RejCrdntnECU_16 "Over The Air Reject Coordination : Reject Coordination ECU_16";
BA_ "SignalType" SG_ 1260 OTARC_RejCrdntnECU_15 "ENM";
BA_ "SignalLongName" SG_ 1260 OTARC_RejCrdntnECU_15 "Over The Air Reject Coordination : Reject Coordination ECU_15";
BA_ "SignalType" SG_ 1260 OTARC_RejCrdntnSBM "ENM";
BA_ "SignalLongName" SG_ 1260 OTARC_RejCrdntnSBM "Over The Air Reject Coordination : Reject Coordination SBM";
BA_ "SignalType" SG_ 1260 OTARC_RejCrdntnCGM "ENM";
BA_ "SignalLongName" SG_ 1260 OTARC_RejCrdntnCGM "Over The Air Reject Coordination : Reject Coordination CGM";
BA_ "SignalType" SG_ 1260 OTARC_RejCrdntnECP_X2 "ENM";
BA_ "SignalLongName" SG_ 1260 OTARC_RejCrdntnECP_X2 "Over The Air Reject Coordination : Reject Coordination ECP_X2";
BA_ "SignalType" SG_ 1260 OTARC_RejCrdntnECU_27 "ENM";
BA_ "SignalLongName" SG_ 1260 OTARC_RejCrdntnECU_27 "Over The Air Reject Coordination : Reject Coordination ECU_27";
BA_ "SignalType" SG_ 1260 OTARC_RejCrdntnECU_26 "ENM";
BA_ "SignalLongName" SG_ 1260 OTARC_RejCrdntnECU_26 "Over The Air Reject Coordination : Reject Coordination ECU_26";
BA_ "SignalType" SG_ 1260 OTARC_RejCrdntnECU_25 "ENM";
BA_ "SignalLongName" SG_ 1260 OTARC_RejCrdntnECU_25 "Over The Air Reject Coordination : Reject Coordination ECU_25";
BA_ "SignalType" SG_ 1260 OTARC_RejCrdntnECU_24 "ENM";
BA_ "SignalLongName" SG_ 1260 OTARC_RejCrdntnECU_24 "Over The Air Reject Coordination : Reject Coordination ECU_24";
BA_ "SignalType" SG_ 1260 OTARC_RejCrdntnECU_23 "ENM";
BA_ "SignalLongName" SG_ 1260 OTARC_RejCrdntnECU_23 "Over The Air Reject Coordination : Reject Coordination ECU_23";
BA_ "SignalType" SG_ 1260 OTARC_RejCrdntnECU_22 "ENM";
BA_ "SignalLongName" SG_ 1260 OTARC_RejCrdntnECU_22 "Over The Air Reject Coordination : Reject Coordination ECU_22";
BA_ "SignalType" SG_ 1260 OTARC_RejCrdntnECU_21 "ENM";
BA_ "SignalLongName" SG_ 1260 OTARC_RejCrdntnECU_21 "Over The Air Reject Coordination : Reject Coordination ECU_21";
BA_ "SignalType" SG_ 1260 OTARC_RejCrdntnECU_20 "ENM";
BA_ "SignalLongName" SG_ 1260 OTARC_RejCrdntnECU_20 "Over The Air Reject Coordination : Reject Coordination ECU_20";
BA_ "SignalType" SG_ 1260 OTARC_RejCrdntnTCM "ENM";
BA_ "SignalLongName" SG_ 1260 OTARC_RejCrdntnTCM "Over The Air Reject Coordination : Reject Coordination TCM";
BA_ "SignalType" SG_ 1260 OTARC_RejCrdntnICCM "ENM";
BA_ "SignalLongName" SG_ 1260 OTARC_RejCrdntnICCM "Over The Air Reject Coordination : Reject Coordination ICCM";
BA_ "SignalType" SG_ 1260 OTARC_RejCrdntnFICM "ENM";
BA_ "SignalLongName" SG_ 1260 OTARC_RejCrdntnFICM "Over The Air Reject Coordination : Reject Coordination FICM";
BA_ "SignalType" SG_ 1260 OTARC_RejCrdntnECU_32 "ENM";
BA_ "SignalLongName" SG_ 1260 OTARC_RejCrdntnECU_32 "Over The Air Reject Coordination : Reject Coordination ECU_32";
BA_ "SignalType" SG_ 1260 OTARC_RejCrdntnECU_31 "ENM";
BA_ "SignalLongName" SG_ 1260 OTARC_RejCrdntnECU_31 "Over The Air Reject Coordination : Reject Coordination ECU_31";
BA_ "SignalType" SG_ 1260 OTARC_RejCrdntnECU_30 "ENM";
BA_ "SignalLongName" SG_ 1260 OTARC_RejCrdntnECU_30 "Over The Air Reject Coordination : Reject Coordination ECU_30";
BA_ "SignalType" SG_ 1260 OTARC_RejCrdntnECU_29 "ENM";
BA_ "SignalLongName" SG_ 1260 OTARC_RejCrdntnECU_29 "Over The Air Reject Coordination : Reject Coordination ECU_29";
BA_ "SignalType" SG_ 1260 OTARC_RejCrdntnECU_28 "ENM";
BA_ "SignalLongName" SG_ 1260 OTARC_RejCrdntnECU_28 "Over The Air Reject Coordination : Reject Coordination ECU_28";
BA_ "SignalType" SG_ 1806 DTCClrInhbd "ENM";
BA_ "SignalLongName" SG_ 1806 DTCClrInhbd "Diagnostic Trouble Code Clear Inhibited";
BA_ "SignalType" SG_ 56 PwrtrnShfLvrLckReqd "ENM";
BA_ "SignalLongName" SG_ 56 PwrtrnShfLvrLckReqd "Powertrain Shift Lever Lock Requested";
BA_ "SignalType" SG_ 935 DrvMode8Ovrrdn "ENM";
BA_ "SignalLongName" SG_ 935 DrvMode8Ovrrdn "Drive Mode 8 Override Flag";
BA_ "SignalType" SG_ 935 DrvMode7Ovrrdn "ENM";
BA_ "SignalLongName" SG_ 935 DrvMode7Ovrrdn "Drive Mode 7 Override Flag";
BA_ "SignalType" SG_ 935 DrvMode6Ovrrdn "ENM";
BA_ "SignalLongName" SG_ 935 DrvMode6Ovrrdn "Drive Mode 6 Override Flag";
BA_ "SignalType" SG_ 935 DrvMode5Ovrrdn "ENM";
BA_ "SignalLongName" SG_ 935 DrvMode5Ovrrdn "Drive Mode 5 Override Flag";
BA_ "SignalType" SG_ 935 DrvMode4Ovrrdn "ENM";
BA_ "SignalLongName" SG_ 935 DrvMode4Ovrrdn "Drive Mode 4 Override Flag";
BA_ "SignalType" SG_ 935 DrvMode3Ovrrdn "ENM";
BA_ "SignalLongName" SG_ 935 DrvMode3Ovrrdn "Drive Mode 3 Override Flag";
BA_ "SignalType" SG_ 935 DrvMode2Ovrrdn "ENM";
BA_ "SignalLongName" SG_ 935 DrvMode2Ovrrdn "Drive Mode 2 Override Flag";
BA_ "SignalType" SG_ 935 DrvMode1Ovrrdn "ENM";
BA_ "SignalLongName" SG_ 935 DrvMode1Ovrrdn "Drive Mode 1 Override Flag";
BA_ "SignalLongName" SG_ 1493 EngCoolFanSpd "Engine Cooling Fan Speed";
BA_ "SignalLongName" SG_ 1493 SD110_ARC "Serial Data 110 : Alive Rolling Count";
BA_ "SignalType" SG_ 1493 GenFld "ENM";
BA_ "SignalLongName" SG_ 1493 GenFld "Generator Failed";
BA_ "SignalType" SG_ 1493 ACCompCmnd "ENM";
BA_ "SignalLongName" SG_ 1493 ACCompCmnd "Serial Data 110 : Air Conditioning Compressor Command";
BA_ "SignalType" SG_ 1493 ACCompCmnd_Inv "ENM";
BA_ "SignalLongName" SG_ 1493 ACCompCmnd_Inv "Serial Data 110 : Air Conditioning Compressor Command Invalid";
BA_ "SignalLongName" SG_ 514 LIB1CurrRwVal "Lithium Ion Battery 1 Current Raw Value";
BA_ "SignalType" SG_ 514 LIB1CurrRwVal_Inv "ENM";
BA_ "SignalLongName" SG_ 514 LIB1CurrRwVal_Inv "Lithium Ion Battery 1 Current Raw Value Invalid";
BA_ "SignalType" SG_ 514 LIB1CurrRwVal_DuD "ENM";
BA_ "SignalLongName" SG_ 514 LIB1CurrRwVal_DuD "Lithium Ion Battery 1 Current Raw Value Don't Use Data";
BA_ "SignalLongName" SG_ 514 LIB1VltgUpprLim "Lithium Ion Battery 1 Voltage Upper Limit";
BA_ "SignalType" SG_ 514 LIB1CurrRwValMult_Inv "ENM";
BA_ "SignalLongName" SG_ 514 LIB1CurrRwValMult_Inv "Lithium Ion Battery 1 Current Raw Value Multiplier Invalid";
BA_ "SignalType" SG_ 514 LIB1CurrRwValMult_DuD "ENM";
BA_ "SignalLongName" SG_ 514 LIB1CurrRwValMult_DuD "Lithium Ion Battery 1 Current Raw Value Multiplier Don't Use Data";
BA_ "SignalType" SG_ 514 LIB1CurrRwValMult "ENM";
BA_ "SignalLongName" SG_ 514 LIB1CurrRwValMult "Lithium Ion Battery 1 Current Raw Value Multiplier";
BA_ "SignalType" SG_ 514 LIB1VltgUpprLim_Inv "ENM";
BA_ "SignalLongName" SG_ 514 LIB1VltgUpprLim_Inv "Lithium Ion Battery 1 Voltage Upper Limit Invalid";
BA_ "SignalType" SG_ 514 LIB1VltgUpprLim_DuD "ENM";
BA_ "SignalLongName" SG_ 514 LIB1VltgUpprLim_DuD "Lithium Ion Battery 1 Voltage Upper Limit Don't Use Data";
BA_ "SignalType" SG_ 514 LIB1CntctrOpnPrwrn "ENM";
BA_ "SignalLongName" SG_ 514 LIB1CntctrOpnPrwrn "Lithium Ion Battery 1 Contactor Opening Prewarning";
BA_ "SignalType" SG_ 514 LIB1CntctrOpnPrwrn_Inv "ENM";
BA_ "SignalLongName" SG_ 514 LIB1CntctrOpnPrwrn_Inv "Lithium Ion Battery 1 Contactor Opening Prewarning Invalid";
BA_ "SignalType" SG_ 514 LIB1CntctrSts_Inv "ENM";
BA_ "SignalLongName" SG_ 514 LIB1CntctrSts_Inv "Lithium Ion Battery 1 Contactor Status Invalid";
BA_ "SignalType" SG_ 514 LIB1CntctrSts_DuD "ENM";
BA_ "SignalLongName" SG_ 514 LIB1CntctrSts_DuD "Lithium Ion Battery 1 Contactor Status Don't Use Data";
BA_ "SignalType" SG_ 514 LIB1CntctrSts "ENM";
BA_ "SignalLongName" SG_ 514 LIB1CntctrSts "Lithium Ion Battery 1 Contactor Status";
BA_ "SignalLongName" SG_ 724 PrplDispBatPwr "Propulsion Display Battery Power";
BA_ "SignalLongName" SG_ 724 PrplDispEngPwr "Propulsion Display Engine Power";
BA_ "SignalType" SG_ 724 PrplDispBatPwr_Inv "ENM";
BA_ "SignalLongName" SG_ 724 PrplDispBatPwr_Inv "Propulsion Display Battery Power Invalid";
BA_ "SignalType" SG_ 724 PrplDispBatPwr_DuD "ENM";
BA_ "SignalLongName" SG_ 724 PrplDispBatPwr_DuD "Propulsion Display Battery Power Don't Use Data";
BA_ "SignalLongName" SG_ 724 PrplDispBatTrq "Propulsion Display Battery Torque";
BA_ "SignalType" SG_ 724 PrplDispEngPwr_Inv "ENM";
BA_ "SignalLongName" SG_ 724 PrplDispEngPwr_Inv "Propulsion Display Engine Power Invalid";
BA_ "SignalType" SG_ 724 PrplDispEngPwr_DuD "ENM";
BA_ "SignalLongName" SG_ 724 PrplDispEngPwr_DuD "Propulsion Display Engine Power Don't Use Data";
BA_ "SignalLongName" SG_ 724 BatPrplDispTrqLvlPct "Battery Propulsion Display Torque Level Percent";
BA_ "SignalType" SG_ 724 BatPrplDispTrqLvlPct_DuD "ENM";
BA_ "SignalLongName" SG_ 724 BatPrplDispTrqLvlPct_DuD "Battery Propulsion Display Torque Level Percent Don't Use Data";
BA_ "SignalType" SG_ 724 PrplDispBatTrq_Inv "ENM";
BA_ "SignalLongName" SG_ 724 PrplDispBatTrq_Inv "Propulsion Display Battery Torque Invalid";
BA_ "SignalType" SG_ 724 PrplDispBatTrq_DuD "ENM";
BA_ "SignalLongName" SG_ 724 PrplDispBatTrq_DuD "Propulsion Display Battery Torque Don't Use Data";
BA_ "SignalLongName" SG_ 724 InstDrvEff "Instantaneous Drive Efficiency";
BA_ "SignalLongName" SG_ 1438 CustNonUsblSOC "Customer Non Usable State of Charge";
BA_ "SignalLongName" SG_ 1438 CustUsblSOC "Customer Usable State of Charge";
BA_ "SignalType" SG_ 1438 CustNonUsblSOC_Inv "ENM";
BA_ "SignalLongName" SG_ 1438 CustNonUsblSOC_Inv "Customer Non Usable State of Charge Invalid";
BA_ "SignalType" SG_ 1438 CustNonUsblSOC_DuD "ENM";
BA_ "SignalLongName" SG_ 1438 CustNonUsblSOC_DuD "Customer Non Usable State of Charge Don't Use Data";
BA_ "SignalLongName" SG_ 1438 CustNonUsblSOCDispLvl "Customer Non Usable State of Charge Display Level";
BA_ "SignalType" SG_ 1438 CustUsblSOC_Inv "ENM";
BA_ "SignalLongName" SG_ 1438 CustUsblSOC_Inv "Customer Usable State of Charge Invalid";
BA_ "SignalType" SG_ 1438 CustUsblSOC_DuD "ENM";
BA_ "SignalLongName" SG_ 1438 CustUsblSOC_DuD "Customer Usable State of Charge Don't Use Data";
BA_ "SignalLongName" SG_ 1438 BatPrplDispPwrLvlPct "Battery Propulsion Display Power Level Percent";
BA_ "SignalType" SG_ 1438 BatPrplDispPwrLvlPct_DuD "ENM";
BA_ "SignalLongName" SG_ 1438 BatPrplDispPwrLvlPct_DuD "Battery Propulsion Display Power Level Percent Don't Use Data";
BA_ "SignalLongName" SG_ 1423 EAWDMPTR_Secs "Electric All Wheel Drive Maximum Power Time Remaining : Seconds";
BA_ "SignalLongName" SG_ 1423 EAWDMPTR_Mins "Electric All Wheel Drive Maximum Power Time Remaining : Minutes";
BA_ "SignalLongName" SG_ 1423 ElecMtrATach "Electric Motor A Tachometer";
BA_ "SignalType" SG_ 1423 ElecMtrATach_Inv "ENM";
BA_ "SignalLongName" SG_ 1423 ElecMtrATach_Inv "Electric Motor A Tachometer Invalid";
BA_ "SignalType" SG_ 1423 ElecMtrATach_DuD "ENM";
BA_ "SignalLongName" SG_ 1423 ElecMtrATach_DuD "Electric Motor A Tachometer Don't Use Data";
BA_ "SignalType" SG_ 1423 HiVltgBatAvgTemp_DuD "ENM";
BA_ "SignalLongName" SG_ 1423 HiVltgBatAvgTemp_DuD "High Voltage Battery Average Temperature Don't Use Data";
BA_ "SignalLongName" SG_ 1423 HiVltgBatAvgTemp "High Voltage Battery Average Temperature";
BA_ "SignalLongName" SG_ 1423 DischrgPwrLtdDispPct "Discharge Power Limited Display Percent";
BA_ "SignalType" SG_ 1423 HiVltgBatAvgTemp_Inv "ENM";
BA_ "SignalLongName" SG_ 1423 HiVltgBatAvgTemp_Inv "High Voltage Battery Average Temperature Invalid";
BA_ "SignalLongName" SG_ 1423 EngPrplDispPwrLvlPct "Engine Propulsion Display Power Level Percent";
BA_ "SignalType" SG_ 1423 EngPrplDispPwrLvlPct_DuD "ENM";
BA_ "SignalLongName" SG_ 1423 EngPrplDispPwrLvlPct_DuD "Engine Propulsion Display Power Level Percent Don't Use Data";
BA_ "SignalLongName" SG_ 1423 EstdEleclPrplCpblty "Estimated Electrical Propulsion Capability";
BA_ "SignalType" SG_ 1423 EngRnngDueToVehSpdIndOn "ENM";
BA_ "SignalLongName" SG_ 1423 EngRnngDueToVehSpdIndOn "Engine Running Due to Vehicle Speed Indication On";
BA_ "SignalType" SG_ 1423 ElecAllWhlDrvIndOn "ENM";
BA_ "SignalLongName" SG_ 1423 ElecAllWhlDrvIndOn "Electric All Wheel Drive Indication On";
BA_ "SignalType" SG_ 1423 DischrgPwrLtdIndOn "ENM";
BA_ "SignalLongName" SG_ 1423 DischrgPwrLtdIndOn "Discharge Power Limited Indication On";
BA_ "SignalType" SG_ 1423 DischrgPwrLtdDispPctVsbl "ENM";
BA_ "SignalLongName" SG_ 1423 DischrgPwrLtdDispPctVsbl "Discharge Power Limited Display Percent Visible";
BA_ "SignalType" SG_ 1423 HiVltgBatLmtnDueToTempInd "ENM";
BA_ "SignalLongName" SG_ 1423 HiVltgBatLmtnDueToTempInd "High Voltage Battery Limitation Due to Temperature Indication";
BA_ "SignalLongName" SG_ 1439 HTD1_DistTrvld "Hybrid Trip Data 1 : Distance Traveled";
BA_ "SignalLongName" SG_ 1439 HTD1_FuelAvdd "Hybrid Trip Data 1 : Fuel Avoided";
BA_ "SignalType" SG_ 1439 HybModeDisp "ENM";
BA_ "SignalLongName" SG_ 1439 HybModeDisp "Hybrid Mode Display";
BA_ "SignalType" SG_ 1439 HTD1_FuelAvdd_DuD "ENM";
BA_ "SignalLongName" SG_ 1439 HTD1_FuelAvdd_DuD "Hybrid Trip Data 1 : Fuel Avoided Don't Use Data";
BA_ "SignalType" SG_ 1439 InstnsFuelEconHybOvrrdReq "ENM";
BA_ "SignalLongName" SG_ 1439 InstnsFuelEconHybOvrrdReq "Instantaneous Fuel Economy Hybrid Override Request";
BA_ "SignalType" SG_ 1439 HybModeDispVehCfg "ENM";
BA_ "SignalLongName" SG_ 1439 HybModeDispVehCfg "Hybrid Mode Display Vehicle Configuration";
BA_ "SignalType" SG_ 1439 HiVltgChrgrSysSts "ENM";
BA_ "SignalLongName" SG_ 1439 HiVltgChrgrSysSts "High Voltage Charger System Status";
BA_ "SignalType" SG_ 1439 HybShfToPrkIndOn "ENM";
BA_ "SignalLongName" SG_ 1439 HybShfToPrkIndOn "Hybrid Shift to Park Indication On";
BA_ "SignalType" SG_ 1439 HiVltgSysDsbld "ENM";
BA_ "SignalLongName" SG_ 1439 HiVltgSysDsbld "High Voltage System Disabled";
BA_ "SignalType" SG_ 1439 JmpStrtSts "ENM";
BA_ "SignalLongName" SG_ 1439 JmpStrtSts "Jump Start Status";
BA_ "SignalLongName" SG_ 1440 HTD2_BatEngyDplyd "Hybrid Trip Data 2 : Battery Energy Deployed";
BA_ "SignalLongName" SG_ 1440 HTD2_BatEngyRegntd "Hybrid Trip Data 2 : Battery Energy Regenerated";
BA_ "SignalLongName" SG_ 1440 PrplDispTotPwr "Propulsion Display Total Power";
BA_ "SignalType" SG_ 1440 PrplDispTotPwr_DuD "ENM";
BA_ "SignalLongName" SG_ 1440 PrplDispTotPwr_DuD "Propulsion Display Total Power Don't Use Data";
BA_ "SignalLongName" SG_ 1440 PrplCpbltyDispOprtgPstn "Propulsion Capability Display Operating Position";
BA_ "SignalType" SG_ 1440 PrplDispTotPwr_Inv "ENM";
BA_ "SignalLongName" SG_ 1440 PrplDispTotPwr_Inv "Propulsion Display Total Power Invalid";
BA_ "SignalType" SG_ 1440 ServHybSysIndOn "ENM";
BA_ "SignalLongName" SG_ 1440 ServHybSysIndOn "Service Hybrid System Indication On";
BA_ "SignalType" SG_ 1440 RegenPwrLimdIndOn "ENM";
BA_ "SignalLongName" SG_ 1440 RegenPwrLimdIndOn "Regenerative Power Limited Indication On";
BA_ "SignalType" SG_ 1440 RegenPwrLimdDispPctVsbl "ENM";
BA_ "SignalLongName" SG_ 1440 RegenPwrLimdDispPctVsbl "Regenerative Power Limited Display Percent Visible";
BA_ "SignalType" SG_ 1440 PrplDispTotPwrUntDisp "ENM";
BA_ "SignalLongName" SG_ 1440 PrplDispTotPwrUntDisp "Propulsion Display Total Power Unit Display";
BA_ "SignalType" SG_ 1440 LossOfPrplIndOn "ENM";
BA_ "SignalLongName" SG_ 1440 LossOfPrplIndOn "Loss Of Propulsion Indication On";
BA_ "SignalType" SG_ 1440 ServHiVltgBatIndReq "ENM";
BA_ "SignalLongName" SG_ 1440 ServHiVltgBatIndReq "Service High Voltage Battery Indication Request";
BA_ "SignalLongName" SG_ 1483 BrkPadLifeFrtDistRmn "Brake Pad Life Status Information : Brake Pad Life Front Distance Remaining";
BA_ "SignalLongName" SG_ 1483 BrkPadLifeRrDistRmn "Brake Pad Life Status Information : Brake Pad Life Rear Distance Remaining";
BA_ "SignalType" SG_ 1483 BrkPadLifeFrtDistWrnIndReq "ENM";
BA_ "SignalLongName" SG_ 1483 BrkPadLifeFrtDistWrnIndReq "Brake Pad Life Status Information : Brake Pad Life Front Distance Warning Indication Request";
BA_ "SignalLongName" SG_ 1483 ESCSpdLtdCntdwnVal "Electronic Stability Control Information : Electronic Stability Control Speed Limited Countdown Value";
BA_ "SignalType" SG_ 1483 BrkPadLifeStsIndReq "ENM";
BA_ "SignalLongName" SG_ 1483 BrkPadLifeStsIndReq "Brake Pad Life Status Information : Brake Pad Life Status Indication Request";
BA_ "SignalType" SG_ 1483 BrkPadLifeRrDistWrnIndReq "ENM";
BA_ "SignalLongName" SG_ 1483 BrkPadLifeRrDistWrnIndReq "Brake Pad Life Status Information : Brake Pad Life Rear Distance Warning Indication Request";
BA_ "SignalLongName" SG_ 1483 ESCVehTopSpdLimDispVal "Electronic Stability Control Information : Electronic Stability Control Vehicle Top Speed Limit Display Value";
BA_ "SignalType" SG_ 1483 ESCSpdLtdIndReq "ENM";
BA_ "SignalLongName" SG_ 1483 ESCSpdLtdIndReq "Electronic Stability Control Information : Electronic Stability Control Speed Limited Indication Request";
BA_ "SignalType" SG_ 1483 HillDscntCtlRdcVehSpdIndOn "ENM";
BA_ "SignalLongName" SG_ 1483 HillDscntCtlRdcVehSpdIndOn "Hill Descent Control Information : Hill Descent Control Reduce Vehicle Speed Indication On";
BA_ "SignalType" SG_ 1483 HillDscntCtlDispActvIndOn "ENM";
BA_ "SignalLongName" SG_ 1483 HillDscntCtlDispActvIndOn "Hill Descent Control Information : Hill Descent Control Display Active Indication On";
BA_ "SignalLongName" SG_ 1483 HillDscntCtlTgtSetSpd "Hill Descent Control Information : Hill Descent Control Target Set Speed";
BA_ "SignalType" SG_ 1483 BrkPadLifeFrtCnfrmRplcmtIndOn "ENM";
BA_ "SignalLongName" SG_ 1483 BrkPadLifeFrtCnfrmRplcmtIndOn "Brake Pad Life Front Confirm Replacement Indication On";
BA_ "SignalType" SG_ 1483 BrkOvrhtdIndOn "ENM";
BA_ "SignalLongName" SG_ 1483 BrkOvrhtdIndOn "Brakes Overheated Indication On";
BA_ "SignalType" SG_ 1483 AllWhlDrvRcmndIndOn "ENM";
BA_ "SignalLongName" SG_ 1483 AllWhlDrvRcmndIndOn "All Wheel Drive Recommended Indication On";
BA_ "SignalType" SG_ 1483 CrwlModeDndRsnIndReq "ENM";
BA_ "SignalLongName" SG_ 1483 CrwlModeDndRsnIndReq "Crawl Mode Denied Reason Indication Request";
BA_ "SignalType" SG_ 1483 BrksOvrht "ENM";
BA_ "SignalLongName" SG_ 1483 BrksOvrht "Brakes Overheated";
BA_ "SignalType" SG_ 1483 BrkSysTwoFtdDrvDtdIndOn "ENM";
BA_ "SignalLongName" SG_ 1483 BrkSysTwoFtdDrvDtdIndOn "Brake System Two Footed Driving Detected Indication On";
BA_ "SignalType" SG_ 1483 BrkSysHillStrtAsstAvl "ENM";
BA_ "SignalLongName" SG_ 1483 BrkSysHillStrtAsstAvl "Brake System Hill Start Assist Available";
BA_ "SignalType" SG_ 1483 BrkPadWrnIO "ENM";
BA_ "SignalLongName" SG_ 1483 BrkPadWrnIO "Brake Pad Worn Indication On";
BA_ "SignalType" SG_ 1483 BrkPadLifeRrCnfrmRplcmtIndOn "ENM";
BA_ "SignalLongName" SG_ 1483 BrkPadLifeRrCnfrmRplcmtIndOn "Brake Pad Life Rear Confirm Replacement Indication On";
VAL_ 710 Sig4473 0 "FALSE" 1 "TRUE" ;
VAL_ 710 Sig4472 0 "FALSE" 1 "TRUE" ;
VAL_ 710 Sig4471 0 "Relay Off" 1 "Relay On" ;
VAL_ 710 Sig2591 0 "FALSE" 1 "TRUE" ;
VAL_ 710 Sig4475 0 "FALSE" 1 "TRUE" ;
VAL_ 710 Sig2615 0 "FALSE" 1 "TRUE" ;
VAL_ 710 Sig6780 0 "FALSE" 1 "TRUE" ;
VAL_ 710 PwrtrnAutoVehHldEnbld 0 "FALSE" 1 "TRUE" ;
VAL_ 710 PwrtrnAutoVehHldActv 0 "FALSE" 1 "TRUE" ;
VAL_ 710 Sig3620 0 "FALSE" 1 "TRUE" ;
VAL_ 710 Sig2592 0 "FALSE" 1 "TRUE" ;
VAL_ 710 Sig2614 0 "None" 1 "Shift Out of High Range" 2 "Shift Out of Low Range" 3 "Shift Out of Neutral Range" ;
VAL_ 948 Sig2548 0 "All cylinders" 1 "Half Cylinders" ;
VAL_ 948 BarPrsAbs_Inv 0 "FALSE" 1 "TRUE" ;
VAL_ 948 Sig2642 0 "FALSE" 1 "TRUE" ;
VAL_ 1486 Sig2557 0 "No Indication" 1 "Complete" 2 "Phase 1" 3 "Phase 2" 4 "Phase 3" 5 "Skip Phase 2" ;
VAL_ 1486 Sig2440 0 "North America" 1 "Europe" ;
VAL_ 1486 Sig2444 0 "No Indication" 1 "Warning Level 1" 2 "Warning Level 2" 3 "Warning Level 3" 4 "Warning Level 4" 5 "Warning Level 5" 6 "Warning Level 6" 7 "Warning Level 7" ;
VAL_ 1801 Sig2627 0 "FALSE" 1 "TRUE" ;
VAL_ 1801 Sig5019 0 "FALSE" 1 "TRUE" ;
VAL_ 1801 Sig5018 0 "FALSE" 1 "TRUE" ;
VAL_ 1801 Sig2576 0 "FALSE" 1 "TRUE" ;
VAL_ 1801 Sig2575 0 "FALSE" 1 "TRUE" ;
VAL_ 1801 Sig2574 0 "FALSE" 1 "TRUE" ;
VAL_ 1801 Sig2573 0 "FALSE" 1 "TRUE" ;
VAL_ 1801 Sig2572 0 "FALSE" 1 "TRUE" ;
VAL_ 1801 Sig0599 0 "None" 1 "Level1" 2 "Level2" 3 "Level3" ;
VAL_ 1801 Sig2579 0 "FALSE" 1 "TRUE" ;
VAL_ 1801 Sig2578 0 "FALSE" 1 "TRUE" ;
VAL_ 1801 Sig2577 0 "FALSE" 1 "TRUE" ;
VAL_ 934 DrvrTkModeCmnd 0 "FALSE" 1 "TRUE" ;
VAL_ 934 DrvrSprtModeCmnd 0 "FALSE" 1 "TRUE" ;
VAL_ 934 DrvrMtnModeCmnd 0 "FALSE" 1 "TRUE" ;
VAL_ 934 DrvrHldModeCmnd 0 "FALSE" 1 "TRUE" ;
VAL_ 934 DrvrExhBrkModeCmnd 0 "FALSE" 1 "TRUE" ;
VAL_ 934 DrvrEconModeCmnd 0 "FALSE" 1 "TRUE" ;
VAL_ 934 DrvrCrwlModeCmnd 0 "FALSE" 1 "TRUE" ;
VAL_ 934 DrvrChrgPlusModeCmnd 0 "FALSE" 1 "TRUE" ;
VAL_ 934 GrdBrkgDsblModeCmnd 0 "FALSE" 1 "TRUE" ;
VAL_ 934 DrvrWntrModeCmnd 0 "FALSE" 1 "TRUE" ;
VAL_ 934 DrvrTowHaulModeCmnd 0 "FALSE" 1 "TRUE" ;
VAL_ 934 PrplSysPriAxlTrqReqStsChsSys 0 "No Request" 1 "Request Honored" 2 "Lost Arbitration" 3 "Serial Data Failure Temporary" 4 "Serial Data Failure Permanent" 5 "Control System Failure Temporary" 6 "Control System Failure Permanent" ;
VAL_ 934 FourCrnrLvlgTopSpdLimRespTyp 0 "Inactive" 1 "Faulted" 2 "Safety_woBrake" 3 "Safety_wBrake" 4 "OBD" 5 "nonOBD" 6 "Legislated" ;
VAL_ 934 AccKdwnDtctd 0 "FALSE" 1 "TRUE" ;
VAL_ 1490 VhSpdCntlSystmTyp 0 "No Vehicle Speed Control" 1 "Conventional Cruise Control" 2 "Adaptive Cruise Control" ;
VAL_ 1490 DrvrSeltdSpdLmtrIndReq 0 "No Action" 1 "Driver Selected Speed Limiter Telltale Off" 2 "Driver Selected Speed Limiter Unavailable Telltale On" 3 "Driver Selected Speed Limiter White Telltale On" 4 "Driver Selected Speed Limiter Green Telltale On" ;
VAL_ 1490 EngNEmsnsRltMlfnAct 0 "FALSE" 1 "TRUE" ;
VAL_ 1490 DrSlctdSpdLmtrEnbld 0 "FALSE" 1 "TRUE" ;
VAL_ 1490 DrSlctdSpdLmtrActv 0 "FALSE" 1 "TRUE" ;
VAL_ 1264 VhGrdSnsrBsd_Inv 0 "FALSE" 1 "TRUE" ;
VAL_ 52 TrnsOvrllEstTrqRt_Inv 0 "FALSE" 1 "TRUE" ;
VAL_ 1491 TrnsOilTmp_Inv 0 "FALSE" 1 "TRUE" ;
VAL_ 1491 TrnsOlTmpSnsPrs 0 "FALSE" 1 "TRUE" ;
VAL_ 1491 Sig7786 0 "FALSE" 1 "TRUE" ;
VAL_ 1491 Sig7800 0 "Normal" 1 "Countermeasures Active" 2 "Driver Intervention Requested" ;
VAL_ 203 RegVltgCtlPwrtrnOvrrdInhbd 0 "FALSE" 1 "TRUE" ;
VAL_ 936 GenStptDtCycPtOvrAct 0 "FALSE" 1 "TRUE" ;
VAL_ 714 ElecShfLckdBcklPsngrStBltIndOn 0 "FALSE" 1 "TRUE" ;
VAL_ 714 ElecShfLckdBcklDrvrStBltIndOn 0 "FALSE" 1 "TRUE" ;
VAL_ 714 DCCnvStblznErrIndOn 0 "FALSE" 1 "TRUE" ;
VAL_ 714 RegVltgCtlEngyRcvryActv 0 "FALSE" 1 "TRUE" ;
VAL_ 714 NoKeyDtdElecShfDndIndOn 0 "FALSE" 1 "TRUE" ;
VAL_ 714 ElecShfUnlckdBrkToShfIndOn 0 "FALSE" 1 "TRUE" ;
VAL_ 1492 ElecShfPriTransCtlrMalfIndOn 0 "FALSE" 1 "TRUE" ;
VAL_ 1492 ElecShfPriShfToDrvTryAgnIndOn 0 "FALSE" 1 "TRUE" ;
VAL_ 1492 ElecShfPriRdcSpdForReqdShfIndOn 0 "FALSE" 1 "TRUE" ;
VAL_ 1492 AirCndOffIO 0 "FALSE" 1 "TRUE" ;
VAL_ 1492 EngCmptHotWrnIndReq 0 "Off" 1 "Service" 2 "Hot Idle" 3 "Hot" ;
VAL_ 1492 ElecShftPrTwoGrsSelIndRq 0 "OFF" 1 "PARK" 2 "NEUTRAL" 3 "DRIVE" ;
VAL_ 1492 ElecShftPrLtdPrfMdIO 0 "FALSE" 1 "TRUE" ;
VAL_ 1492 ElecShftPrHldShftLevEngRngIO 0 "FALSE" 1 "TRUE" ;
VAL_ 1492 ElecShftPrDrPrkIntShftAtmpIO 0 "FALSE" 1 "TRUE" ;
VAL_ 1492 ElecShftPrDrIntShftAtmpIO 0 "FALSE" 1 "TRUE" ;
VAL_ 1492 ElecShftPrDrExitIO 0 "FALSE" 1 "TRUE" ;
VAL_ 1492 ElecShftPrDrDoorStIndIO 0 "FALSE" 1 "TRUE" ;
VAL_ 1492 ElecShftPrAtPrkIO 0 "FALSE" 1 "TRUE" ;
VAL_ 1492 ElecShfPriTrnVehOffForPrkIndOn 0 "FALSE" 1 "TRUE" ;
VAL_ 1492 ElecShftrLckdHldBrkToOvrrdIndOn 0 "FALSE" 1 "TRUE" ;
VAL_ 1492 ElecShftPrTrnMlfIO 0 "FALSE" 1 "TRUE" ;
VAL_ 1492 ElecShftPrRngInvRqIO 0 "FALSE" 1 "TRUE" ;
VAL_ 1492 ElecShftPrPrkInvRqIO 0 "FALSE" 1 "TRUE" ;
VAL_ 1494 ECERDTC_ECP_E_SysDes 0 "P0_Powertrain Codes SAE Controlled" 1 "P1_Powertrain Codes MFG Controlled" 2 "P2_Powertrain Codes Reserved" 3 "P3_Powertrain Codes Reserved" 4 "C0_Chassis Codes SAE Controlled" 5 "C1_Chassis Codes MFG Controlled" 6 "C2_Chassis Codes Reserved" 7 "C3_Chassis Codes Reserved" 8 "B0_Body Codes SAE Controlled" 9 "B1_Body Codes MFG Controlled" 10 "B2_Body Codes Reserved" 11 "B3_Body Codes Reserved" 12 "U0_Network Codes SAE Controlled" 13 "U1_Network Codes MFG Controlled" 14 "U2_Network Codes Reserved" 15 "U3_Network Codes Reserved" ;
VAL_ 1494 ElecAllWhlDrvESCTTFlshgActv 0 "FALSE" 1 "TRUE" ;
VAL_ 1494 ElecCtlPrcsrEmsRltMlfAtv_ECP_E 0 "FALSE" 1 "TRUE" ;
VAL_ 1803 DrvMtrInvrtMaxTemp_Inv 0 "FALSE" 1 "TRUE" ;
VAL_ 42 HybChrgModeStat 0 "Charge Depleting" 1 "Charge Sustaining" ;
VAL_ 42 HiVltgActvDischrgCmnd 0 "FALSE" 1 "TRUE" ;
VAL_ 42 ElecDischrgActr2DischrgSts 0 "Inactive" 1 "Operational" 2 "Unavilable" ;
VAL_ 42 Sig3621 0 "FALSE" 1 "TRUE" ;
VAL_ 42 ElecMtrATrqAchvd_Inv 0 "FALSE" 1 "TRUE" ;
VAL_ 732 ElecMtrASttrTemp_Inv 0 "FALSE" 1 "TRUE" ;
VAL_ 43 ElecDischrgActr4DischrgSts 0 "Inactive" 1 "Operational" 2 "Unavailable" ;
VAL_ 1263 PIMRI_ECP_S2_PrmntDTCInd 0 "FALSE" 1 "TRUE" ;
VAL_ 1263 PIMRI_ECP_S2_FltsPrsntInd 0 "FALSE" 1 "TRUE" ;
VAL_ 1263 DMCM3EmsRltMlfAtv 0 "FALSE" 1 "TRUE" ;
VAL_ 1263 DMCM3ERDTC_SysDes 0 "P0-Powertrain Codes SAE Controlled" 1 "P1-Powertrain Codes MFG Controlled" 2 "P2-Powertrain Codes Reserved" 3 "P3-Powertrain Codes Reserved" 4 "C0-Chassis Codes SAE Controlled" 5 "C1-Chassis Codes MFG Controlled" 6 "C2-Chassis Codes Reserved" 7 "C3-Chassis Codes Reserved" 8 "B0-Body Codes SAE Controlled" 9 "B1-Body Codes MFG Controlled" 10 "B2-Body Codes Reserved" 11 "B3-Body Codes Reserved" 12 "U0-Network Codes SAE Controlled" 13 "U1-Network Codes MFG Controlled" 14 "U2- Network Codes Reserved" 15 "U3-Network Codes Reserved" ;
VAL_ 113 Sig0503 0 "FALSE" 1 "TRUE" ;
VAL_ 113 Sig0505 0 "FALSE" 1 "TRUE" ;
VAL_ 113 Sig0508 0 "FALSE" 1 "TRUE" ;
VAL_ 113 Sig0510 0 "FALSE" 1 "TRUE" ;
VAL_ 113 Sig0506 0 "Power Stage Inactive" 1 "Power Stage Active" ;
VAL_ 113 Sig0501 0 "Disable Normal Power Stage" 1 "Torque Control" 2 "Shutdown Initiated" 3 "Disable Immediate" 4 "Normal Charge with Internal Setpoint" 5 "Normal Charge with External Setpoint" ;
VAL_ 733 Sig0512 0 "FALSE" 1 "TRUE" ;
VAL_ 1495 Sig2505 0 "P0_Powertrain Codes SAE Controlled" 1 "P1_Powertrain Codes MFG Controlled" 2 "P2_Powertrain Codes Reserved" 3 "P3_Powertrain Codes Reserved" 4 "C0_Chassis Codes SAE Controlled" 5 "C1_Chassis Codes MFG Controlled" 6 "C2_Chassis Codes Reserved" 7 "C3_Chassis Codes Reserved" 8 "B0_Body Codes SAE Controlled" 9 "B1_Body Codes MFG Controlled" 10 "B2_Body Codes Reserved" 11 "B3_Body Codes Reserved" 12 "U0_Network Codes SAE Controlled" 13 "U1_Network Codes MFG Controlled" 14 "U2_Network Codes Reserved" 15 "U3_Network Codes Reserved" ;
VAL_ 1495 Sig2566 0 "FALSE" 1 "TRUE" ;
VAL_ 1262 Sig4456 0 "FALSE" 1 "TRUE" ;
VAL_ 1262 Sig4455 0 "FALSE" 1 "TRUE" ;
VAL_ 41 ElecDischrgActr3DischrgSts 0 "Inactive" 1 "Operational" 2 "Unavailable" ;
VAL_ 1804 ECPSERDTC_SysDes 0 "P0-Powertrain Codes SAE Controlled" 1 "P1-Powertrain Codes MFG Controlled" 2 "P2-Powertrain Codes Reserved" 3 "P3-Powertrain Codes Reserved" 4 "C0-Chassis Codes SAE Controlled" 5 "C1-Chassis Codes MFG Controlled" 6 "C2-Chassis Codes Reserved" 7 "C3-Chassis Codes Reserved" 8 "B0-Body Codes SAE Controlled" 9 "B1-Body Codes MFG Controlled" 10 "B2-Body Codes Reserved" 11 "B3-Body Codes Reserved" 12 "U0-Network Codes SAE Controlled" 13 "U1-Network Codes MFG Controlled" 14 "U2- Network Codes Reserved" 15 "U3-Network Codes Reserved" ;
VAL_ 1804 DrvMtrInvrt2MaxTemp_Inv 0 "FALSE" 1 "TRUE" ;
VAL_ 1804 ECPSEmsRltMlfAtv 0 "FALSE" 1 "TRUE" ;
VAL_ 1804 PIMRI_ECP_S_PrmntDTCInd 0 "FALSE" 1 "TRUE" ;
VAL_ 1804 PIMRI_ECP_S_FltsPrsntInd 0 "FALSE" 1 "TRUE" ;
VAL_ 1804 DMCM2EmsRltMlfAtv 0 "FALSE" 1 "TRUE" ;
VAL_ 1804 DMCM2ERDTC_SysDes 0 "P0-Powertrain Codes SAE Controlled" 1 "P1-Powertrain Codes MFG Controlled" 2 "P2-Powertrain Codes Reserved" 3 "P3-Powertrain Codes Reserved" 4 "C0-Chassis Codes SAE Controlled" 5 "C1-Chassis Codes MFG Controlled" 6 "C2-Chassis Codes Reserved" 7 "C3-Chassis Codes Reserved" 8 "B0-Body Codes SAE Controlled" 9 "B1-Body Codes MFG Controlled" 10 "B2-Body Codes Reserved" 11 "B3-Body Codes Reserved" 12 "U0-Network Codes SAE Controlled" 13 "U1-Network Codes MFG Controlled" 14 "U2- Network Codes Reserved" 15 "U3-Network Codes Reserved" ;
VAL_ 734 ElecMtrARotrTemp_Inv 0 "FALSE" 1 "TRUE" ;
VAL_ 1497 Sig2564 0 "No Indication" 1 "Limited" 2 "Faulted" ;
VAL_ 1497 Sig2563 0 "Normal" 1 "Temporarily Unavailable" 2 "Unavailable" ;
VAL_ 1415 HtdStrgWhlDrvOutStsGtd 0 "Off-Normal Operation" 1 "On-Normal Operation-Temp Status Indeterminate" 2 "On-Normal Operation-Temp Status Increasing" 3 "On-Normal Operation-Temp Reached" 4 "On-Degraded Operation-Temp not Reached" 5 "On-Faulted Operation-Power Limited" 6 "Off-Faulted Operation-Output Control Fault not Present" 7 "Off-Faulted Operation-Output Control Fault Present" ;
VAL_ 1415 HtdStrgWhlDrvOutStsGtd_Inv 0 "FALSE" 1 "TRUE" ;
VAL_ 1415 LnCntrWrnIndRqst 0 "No Indication" 1 "Can not See Lanes" 2 "Tight Curve" 3 "Freeway Ends" 4 "Construction" 5 "Excessive Speed" 6 "Vehicles Too Close" 7 "Canceled Take Steering" 8 "Can not See Eyes" 9 "Due to Weather" 10 "Take Steering" 11 "Take Vehicle Control" 12 "Service Driver Assist System" 13 "Lane Following Locked Out" 14 "TJA Max Speed Reached" 15 "TJA Available" 16 "TJA Active" ;
VAL_ 1415 LnFllwgHzrdLgtsReq 0 "No Request" 1 "Active Override Allowed" 2 "Active Override Not Allowed" ;
VAL_ 1415 LnCntrEsclnSts 0 "None" 1 "Driver Not Looking to Roadway" 2 "Limited Condition" 3 "System Faulted" ;
VAL_ 1415 HtdStrgWhlStkSwGtd 0 "FALSE" 1 "TRUE" ;
VAL_ 1415 HtdStrgWhlStkSwGtd_Inv 0 "FALSE" 1 "TRUE" ;
VAL_ 1415 HtdStrgWhlExtrnFltPrsntGtd 0 "FALSE" 1 "TRUE" ;
VAL_ 1415 HtdStrgWhlExtrnFltPrsntGtd_Inv 0 "FALSE" 1 "TRUE" ;
VAL_ 1415 CIBAutoBrkRelIndOn 0 "FALSE" 1 "TRUE" ;
VAL_ 1415 RIMIntCllnChmEvStat 0 "NO_ACTION" 1 "ACTIVE" 2 "CANCEL_CHIM" ;
VAL_ 1415 RIMBrkPlsChEvStat 0 "NO_ACTION" 1 "ACTIVE" 2 "CANCEL_CHIM" ;
VAL_ 1415 ManHtdStrgWhlReqdGtd 0 "FALSE" 1 "TRUE" ;
VAL_ 1415 ManHtdStrgWhlReqdGtd_Inv 0 "FALSE" 1 "TRUE" ;
VAL_ 1415 RIM_BrkPrfllReq 0 "FALSE" 1 "TRUE" ;
VAL_ 1415 RIMUnIndOn 0 "FALSE" 1 "TRUE" ;
VAL_ 1415 RIMONIndOn 0 "FALSE" 1 "TRUE" ;
VAL_ 1415 RIMOFFIndOn 0 "FALSE" 1 "TRUE" ;
VAL_ 1415 LnCntrMisuseCond 0 "FALSE" 1 "TRUE" ;
VAL_ 1415 LnCntrDrvAwrIndOn 0 "FALSE" 1 "TRUE" ;
VAL_ 1415 HtdStrgWhlSwActvGtd 0 "FALSE" 1 "TRUE" ;
VAL_ 1415 FIM_CIS_BrkPrfllReq 0 "FALSE" 1 "TRUE" ;
VAL_ 1415 SuprRmtPrkSptSeltnRmtReq 0 "Hidden" 1 "Disabled" 2 "Enabled" 3 "Highlighted" ;
VAL_ 1415 SuprRmtPrkSptSeltnKeepLkReq 0 "Hidden" 1 "Disabled" 2 "Enabled" 3 "Highlighted" ;
VAL_ 1415 SuprRmtPrkSptSeltnAcceptReq 0 "Hidden" 1 "Disabled" 2 "Enabled" 3 "Highlighted" ;
VAL_ 1415 TnDrvRIMOFFUnvIndOn 0 "FALSE" 1 "TRUE" ;
VAL_ 1415 RrVirtBmpAutoBrkRelIndOn 0 "FALSE" 1 "TRUE" ;
VAL_ 1415 RIM_BrkPulsReq 0 "FALSE" 1 "TRUE" ;
VAL_ 1415 SuprRmtPrkUnabletoCnctTryAgnReq 0 "Hidden" 1 "Disabled" 2 "Enabled" 3 "Highlighted" ;
VAL_ 1415 SuprRmtPrkUnabletoCnctExtReq 0 "Hidden" 1 "Disabled" 2 "Enabled" 3 "Highlighted" ;
VAL_ 1431 LnChgDmndMomtryLnChgDsbl 0 "FALSE" 1 "TRUE" ;
VAL_ 1431 LnChgDmndLnChgReq 0 "No_Activation" 1 "Left" 2 "Right" ;
VAL_ 1499 LnCntrArrwBlck1Act 0 "FALSE" 1 "TRUE" ;
VAL_ 1499 LnCntrSpchPrmtReq 0 "No Prompt" 1 "Take Steering" 2 "Take Vehicle Control" ;
VAL_ 1499 LnCntrCnvMsgIndRqst 0 "No Indication" 1 "Behind Slow Vehicle" 2 "Being Passed on Left" 3 "Being Passed on Right" 4 "Tailgater Detected" 5 "Left Blind Spot Occupied" 6 "Right Blind Spot Occupied" 7 "Heavy Traffic" 8 "Merging Vehicle" 9 "Slow Moving Traffic in Left Lane" 10 "Slow Moving Traffic Ahead" 11 "Slow Moving Traffic in Right Lane" 12 "Major Road Interchange Ahead" 13 "Road Exit Detected Ahead" 14 "Exit Only Lane Ahead" 15 "Lane Ending Ahead" 16 "Road Detour Detected" 17 "Take Time to Look at Road" 18 "Show Fuel Level" 19 "Show Fuel Range Normal" 20 "Show Fuel Range Low" 21 "Take Steering Active With Muting" ;
VAL_ 1499 RIMObjAtchdIndOn 0 "FALSE" 1 "TRUE" ;
VAL_ 1499 RIMElecPrkBrkRelIndOn 0 "FALSE" 1 "TRUE" ;
VAL_ 1499 LnCntrArrwBlck5Act 0 "FALSE" 1 "TRUE" ;
VAL_ 1499 LnCntrArrwBlck4Act 0 "FALSE" 1 "TRUE" ;
VAL_ 1499 LnCntrArrwBlck3Act 0 "FALSE" 1 "TRUE" ;
VAL_ 1499 LnCntrArrwBlck2Act 0 "FALSE" 1 "TRUE" ;
VAL_ 181 FCAR_FCAImntCruzCtlCnclReqd 0 "FALSE" 1 "TRUE" ;
VAL_ 1416 LKALnMrkgIndLt 0 "Off" 1 "White" 2 "Green" 3 "Amber" 4 "Amber Flashing" ;
VAL_ 1416 GoNotfrCstCrStVal 0 "SETTING_UNKNOWN" 1 "OFF" 2 "ON" 3 "RESERVED_3" 4 "RESERVED_4" 5 "RESERVED_5" 6 "RESERVED_6" 7 "RESERVED_7" ;
VAL_ 1416 FrwdVhImAlrtIndRqst 0 "OFF" 1 "ON" 2 "0.5_Hz" 3 "1_Hz" 4 "2_Hz" 5 "4_Hz" 6 "RESERVED_1" 7 "RESERVED_2" ;
VAL_ 1416 LnDtWrnCntrlVsAlrtCmdGnc 0 "OFF" 1 "NOT READY TO ASSIST" 2 "READY TO ASSIST" 3 "ALERT" 4 "INTERVENTION" ;
VAL_ 1416 LnDtWrnCntrlFtrSt 0 "OFF" 1 "STANDBY" 2 "READY TO ASSIST" 3 "FAILED" 4 "ALERT AND CONTROL" ;
VAL_ 1416 LKALnMrkgIndRt 0 "Off" 1 "White" 2 "Green" 3 "Amber" 4 "Amber Flashing" ;
VAL_ 1416 LDWCtrlHndOff1ChmEvntStat 0 "NO_ACTION" 1 "ACTIVE" 2 "CANCEL_CHIME" ;
VAL_ 1416 FrwdCllsnAlrtImAlrtDrIntAlrtChmE 0 "NO_ACTION" 1 "ACTIVE" 2 "CANCEL_CHIME" ;
VAL_ 1416 FrntPCMChmEvntStat 0 "NO_ACTION" 1 "ACTIVE" 2 "CANCEL_CHIME" ;
VAL_ 1416 LDWCtrlRtHndSdChmEvntStat 0 "NO_ACTION" 1 "ACTIVE" 2 "CANCEL_CHIME" ;
VAL_ 1416 LDWCtrlLtHndSdChmEvntStat 0 "NO_ACTION" 1 "ACTIVE" 2 "CANCEL_CHIME" ;
VAL_ 1416 LDWCtrlHndOff3ChmEvntStat 0 "NO_ACTION" 1 "ACTIVE" 2 "CANCEL_CHIME" ;
VAL_ 1416 LDWCtrlHndOff2ChmEvntStat 0 "NO_ACTION" 1 "ACTIVE" 2 "CANCEL_CHIME" ;
VAL_ 1416 LDWCtrlAudAttnReqd 0 "FALSE" 1 "TRUE" ;
VAL_ 1416 GoNotfrCstStAvl 0 "FALSE" 1 "TRUE" ;
VAL_ 1416 FrwdVhHdwyAlrtIndOn 0 "FALSE" 1 "TRUE" ;
VAL_ 1416 FCA_BrkPrfllReq 0 "FALSE" 1 "TRUE" ;
VAL_ 1416 AdptCrsCntrlEngd 0 "FALSE" 1 "TRUE" ;
VAL_ 1500 ACCTrlrGapSetIndOn 0 "FALSE" 1 "TRUE" ;
VAL_ 1500 FllwgTmDsplyMd 0 "NO DISPLAY" 1 "DEFAULT" 2 "NORMAL" 3 "LESS THAN MINIMUM" 4 "GREATER THAN MAXIMUM" ;
VAL_ 1500 FrwdHdwyVisIndCtl 0 "FCA" 1 "ACC" 2 "None" ;
VAL_ 1500 FCA_ACCGapSetIndOn 0 "FALSE" 1 "TRUE" ;
VAL_ 1500 FCAACCGapSeltn 0 "Far" 1 "Medium" 2 "Near" 3 "Off" 4 "Unknown" ;
VAL_ 1500 LAOA_LatAsstHoLFOptAval 0 "FALSE" 1 "TRUE" ;
VAL_ 1500 AdpAndCnvntlCruzCtlIndReq 0 "No Action" 1 "Cruise Control and Adaptive Cruise Control Telltale Off" 2 "Cruise Control Unavailable Telltale On" 3 "Cruise Control White Telltale On" 4 "Cruise Control Green Telltale On" 5 "Cruise Control Blue Telltale On" 6 "Adaptive Cruise Control Unavailable Telltale On" 7 "Adaptive Cruise Control White Telltale On" 8 "Adaptive Cruise Control Green Telltale On" 9 "Adaptive Cruise Control Blue Telltale On" ;
VAL_ 1500 LtAstStsIndRq 0 "No Indication" 1 "Off" 2 "LDW" 3 "LKA" 4 "HoLF" ;
VAL_ 1500 FCAGpSet 0 "FAR" 1 "MEDIUM" 2 "NEAR" 3 "OFF" 4 "UNKNOWN" 5 "FAULTED" ;
VAL_ 1500 LAOA_LatAsstOffOptAval 0 "FALSE" 1 "TRUE" ;
VAL_ 1500 LAOA_LatAsstLKAOptAval 0 "FALSE" 1 "TRUE" ;
VAL_ 1500 LAOA_LatAsstLDWOptAval 0 "FALSE" 1 "TRUE" ;
VAL_ 1500 PdWrnIndRqst 0 "OFF" 1 "PEDESTRIAN ADVISORY" 2 "PEDESTRIAN ALERT" 3 "RESERVED" ;
VAL_ 1500 LnDprtrWrnCtlSdThrtRtMirIndReq 0 "Off" 1 "Solid" 2 "Flashing" 3 "No Action" ;
VAL_ 1500 LnDprtrWrnCtlSdThrtLtMirIndReq 0 "Off" 1 "Solid" 2 "Flashing" 3 "No Action" ;
VAL_ 1500 ACCHdwySttng 0 "FAR" 1 "MEDIUM" 2 "NEAR" ;
VAL_ 1500 FrtPedtrnBrkgWrnIndOn 0 "FALSE" 1 "TRUE" ;
VAL_ 1500 ACCTmpUnvIndOn 0 "FALSE" 1 "TRUE" ;
VAL_ 1500 ACCSysSlctdMdDspIndOn 0 "FALSE" 1 "TRUE" ;
VAL_ 1500 ACCShftToPrkBfrExIndOn 0 "FALSE" 1 "TRUE" ;
VAL_ 1500 ACCRtSpdAdVsIndOn 0 "FALSE" 1 "TRUE" ;
VAL_ 1500 ACCHdwySttngIndOn 0 "FALSE" 1 "TRUE" ;
VAL_ 1500 ACCDsngIndOn 0 "FALSE" 1 "TRUE" ;
VAL_ 1500 SrvDvrAsstSystVslMsgRqstOn 0 "FALSE" 1 "TRUE" ;
VAL_ 1500 LnKpAsstUnAvIndOn 0 "FALSE" 1 "TRUE" ;
VAL_ 1500 LnDprtrWrngUnAvIndOn 0 "FALSE" 1 "TRUE" ;
VAL_ 1500 FrwdClsnSysIndOn 0 "FALSE" 1 "TRUE" ;
VAL_ 1500 FrwdCllsnSysUnIndOn 0 "FALSE" 1 "TRUE" ;
VAL_ 1500 FrwdCllsnSysRdIndOn 0 "FALSE" 1 "TRUE" ;
VAL_ 1500 FrwdCllsnSysOffIndOn 0 "FALSE" 1 "TRUE" ;
VAL_ 1500 FrwdCllsnAlrtOffIndOn 0 "FALSE" 1 "TRUE" ;
VAL_ 1500 TnDrvGapAdjUnvIndOn 0 "FALSE" 1 "TRUE" ;
VAL_ 1500 TeenDrvrLnDprtrWrnOffUnvIndOn 0 "FALSE" 1 "TRUE" ;
VAL_ 1500 SrvFrwdCllsnSysIndOn 0 "FALSE" 1 "TRUE" ;
VAL_ 941 HstVehTrlrDtd 0 "Unknown" 1 "Trailer Not Detected" 2 "Trailer Detected" 3 "Unsupported Trailer Detected" ;
VAL_ 1261 Sig6920 0 "FALSE" 1 "TRUE" ;
VAL_ 1261 Sig6921 0 "FALSE" 1 "TRUE" ;
VAL_ 1261 Sig6924 0 "FALSE" 1 "TRUE" ;
VAL_ 1261 Sig6923 0 "FALSE" 1 "TRUE" ;
VAL_ 1261 Sig6928 0 "FALSE" 1 "TRUE" ;
VAL_ 1261 Sig6927 0 "FALSE" 1 "TRUE" ;
VAL_ 1261 Sig6931 0 "FALSE" 1 "TRUE" ;
VAL_ 1261 Sig6930 0 "FALSE" 1 "TRUE" ;
VAL_ 1261 Sig6934 0 "FALSE" 1 "TRUE" ;
VAL_ 1261 Sig6933 0 "FALSE" 1 "TRUE" ;
VAL_ 1418 LSCMB_BrkPrfllReq 0 "FALSE" 1 "TRUE" ;
VAL_ 1418 Sig4119 0 "FALSE" 1 "TRUE" ;
VAL_ 735 FOPPriGridVltgOvrrdPrty 0 "None" 1 "Low" 2 "Medium" 3 "High" ;
VAL_ 735 Sig3234 0 "Not Commanded" 1 "Commanded Open" 2 "Commanded Closed" ;
VAL_ 735 FOPGridIsltnSwStat 0 "Indeterminate" 1 "Closed" 2 "Open" 3 "Reserved" ;
VAL_ 735 Sig3237 0 "FALSE" 1 "TRUE" ;
VAL_ 735 Sig3236 0 "FALSE" 1 "TRUE" ;
VAL_ 735 EE46ecGridVltgOvrrdActv 0 "FALSE" 1 "TRUE" ;
VAL_ 663 LIB1PackIntrnlVltg_Inv 0 "FALSE" 1 "TRUE" ;
VAL_ 663 LIB1CellMaxVltg_Inv 0 "FALSE" 1 "TRUE" ;
VAL_ 663 LIB1CellMaxVltg_DuD 0 "FALSE" 1 "TRUE" ;
VAL_ 663 LIB1CellMinVltg_Inv 0 "FALSE" 1 "TRUE" ;
VAL_ 663 LIB1SOH_Inv 0 "FALSE" 1 "TRUE" ;
VAL_ 663 Sig4000 0 "FALSE" 1 "TRUE" ;
VAL_ 663 Sig4002 0 "FALSE" 1 "TRUE" ;
VAL_ 663 Sig4006 0 "FALSE" 1 "TRUE" ;
VAL_ 663 Sig4004 0 "FALSE" 1 "TRUE" ;
VAL_ 663 LIB1CntctrSlfTstRslts 0 "All results passed" 1 "Contactor stuck open" 2 "Contactor stuck closed" ;
VAL_ 663 LIB1CntctrSlfTstRslts_Inv 0 "FALSE" 1 "TRUE" ;
VAL_ 663 LIB1EOLFlt 0 "No Fault Detected" 1 "End of Life" 2 "Reserved1" 3 "Reserved2" ;
VAL_ 663 LIB1EOLFlt_Inv 0 "FALSE" 1 "TRUE" ;
VAL_ 663 LIB1TempFlt_Inv 0 "FALSE" 1 "TRUE" ;
VAL_ 663 LIB1TempFlt_DuD 0 "FALSE" 1 "TRUE" ;
VAL_ 663 LIB1TempFlt 0 "No Fault" 1 "Low Severity" 2 "Medium Severity" 3 "High Severity" ;
VAL_ 663 LIB1CurrFlt 0 "FALSE" 1 "TRUE" ;
VAL_ 663 LIB1CurrFlt_Inv 0 "FALSE" 1 "TRUE" ;
VAL_ 663 Sig3997 0 "FALSE" 1 "TRUE" ;
VAL_ 663 Sig3998 0 "FALSE" 1 "TRUE" ;
VAL_ 1807 LIB1SOCReconfRdnes_Inv 0 "FALSE" 1 "TRUE" ;
VAL_ 1807 LIB1SOCReconfRdnes_DuD 0 "FALSE" 1 "TRUE" ;
VAL_ 1807 LIB1SOCReconfRdnes 0 "None" 1 "Pre-Alert" 2 "Override Status" 3 "Priority Status" ;
VAL_ 1433 Sig4422 0 "No Action" 1 "Min" 2 "Default-2" 3 "Default-1" 4 "Default" 5 "Default+1" 6 "Default+2" 7 "Max" ;
VAL_ 1433 Sig4420 0 "No Action" 1 "Min" 2 "Default-2" 3 "Default-1" 4 "Default" 5 "Default+1" 6 "Default+2" 7 "Max" ;
VAL_ 1433 NghtVsnSysStat 0 "UNKNOWN" 1 "INITIALIZING" 2 "INACTIVE" 3 "ACTIVE" 4 "NEEDS SERVICE" 5 "NOT DARK" 6 "TEMPORARILY UNAVAILABLE" 7 "NEEDS HEADLIGHTS" ;
VAL_ 1433 Sig4418 0 "FALSE" 1 "TRUE" ;
VAL_ 1433 Sig4419 0 "Normal" 1 "Limited" 2 "Unavailable" 3 "Invalid" ;
VAL_ 1433 NtVsnAnmlWrnIndReq 0 "Unknown" 1 "Off" 2 "Advisory" 3 "Alert" ;
VAL_ 1433 NghtVsnPdWrnIndRqst 0 "Unknown" 1 "Off" 2 "Pedestrian Advisory" 3 "Pedestrian Alert" ;
VAL_ 1434 Sig3405 0 "No Action" 1 "No Indication" 2 "For 4WD Low Shift Transmission To Neutral" 3 "To Exit 4WD Low Shift Transmission to Neutral" 4 "For 4WD Low Reduce Speed" 5 "To Exit 4WD Low Reduce Speed" 6 "Reminder Vehicle Still In 4WD Low" 7 "4WD Shift in Progress" 8 "4WD Shift Not Allowed Engine Warming Up" 9 "4WD Shift Not Allowed Mismatched Tire" 10 "4WD Shift Not Allowed In Park" 11 "Apply Brake For 4WD Shift" 12 "No 4WD Shifts Allowed" 13 "Reduce Speed For 4WD Shift" 14 "Turn off Engine for 4WD Shift" 15 "For 4WD Shift Transmission Neutral" ;
VAL_ 1502 SecAxlThrmCapPrtRqAct 0 "FALSE" 1 "TRUE" ;
VAL_ 111 Sig7793 0 "FALSE" 1 "TRUE" ;
VAL_ 111 Sig7795 0 "FALSE" 1 "TRUE" ;
VAL_ 111 Sig7773 0 "FALSE" 1 "TRUE" ;
VAL_ 111 Sig7792 0 "FALSE" 1 "TRUE" ;
VAL_ 111 AtTrnsGrSftDrct 0 "No Shift in Progress" 1 "Upshift in Progress" 2 "Downshift in Progress" ;
VAL_ 196 Sig0589 0 "FALSE" 1 "TRUE" ;
VAL_ 196 Sig0588 0 "FALSE" 1 "TRUE" ;
VAL_ 196 Sig0587 0 "FALSE" 1 "TRUE" ;
VAL_ 196 Sig0586 0 "FALSE" 1 "TRUE" ;
VAL_ 196 Sig0585 0 "FALSE" 1 "TRUE" ;
VAL_ 196 Sig0584 0 "FALSE" 1 "TRUE" ;
VAL_ 196 Sig0583 0 "FALSE" 1 "TRUE" ;
VAL_ 196 Sig0582 0 "FALSE" 1 "TRUE" ;
VAL_ 196 Sig0597 0 "FALSE" 1 "TRUE" ;
VAL_ 196 Sig0596 0 "FALSE" 1 "TRUE" ;
VAL_ 196 Sig0595 0 "FALSE" 1 "TRUE" ;
VAL_ 196 Sig0594 0 "FALSE" 1 "TRUE" ;
VAL_ 196 Sig0593 0 "FALSE" 1 "TRUE" ;
VAL_ 196 Sig0592 0 "FALSE" 1 "TRUE" ;
VAL_ 196 Sig0591 0 "FALSE" 1 "TRUE" ;
VAL_ 196 Sig0590 0 "FALSE" 1 "TRUE" ;
VAL_ 196 Sig7621 0 "FALSE" 1 "TRUE" ;
VAL_ 196 Sig7801 0 "Unlocked" 1 "Transitioning" 2 "Controlled Slip" 3 "Locked" 4 "Not Supported" ;
VAL_ 196 Sig7802 0 "FALSE" 1 "TRUE" ;
VAL_ 196 Sig7628 0 "FALSE" 1 "TRUE" ;
VAL_ 719 Sig7775 0 "FALSE" 1 "TRUE" ;
VAL_ 937 Sig7784 0 "FALSE" 1 "TRUE" ;
VAL_ 937 TrnsTUTDMdSt 0 "No Activation" 1 "Driver Shift Control Active" 2 "Electronic Range Select Active" ;
VAL_ 937 Sig2416 0 "Unknown" 1 "First Gear" 2 "Second Gear" 3 "Third Gear" 4 "Fourth Gear" 5 "Fifth Gear" 6 "Sixth Gear" 7 "Seventh Gear" 8 "Eighth Gear" 9 "Ninth Gear" 10 "Tenth Gear" ;
VAL_ 937 DrvShftCntrlReqDndIO 0 "FALSE" 1 "TRUE" ;
VAL_ 937 Sig7796 0 "No Range Inhibit Active" 1 "Transmission Inhibit Active" 2 "Transmission Range Re-Selection Req" 3 "Driveline Not Engaged" 4 "Diagnostic Inhibit Active" ;
VAL_ 937 Sig2421 0 "Normal Stability" 1 "Level 1" 2 "Level 2" 3 "Level 3" ;
VAL_ 937 Sig7783 0 "Disengaged" 1 "Engaging" 2 "Engaged" 3 "Disengaging" 4 "Controlled Slip" 5 "Reserved" 6 "Reserved" 7 "Not Supported" ;
VAL_ 937 Sig7643 0 "No Override" 1 "Override To Not Economy" 2 "Override To Economy" 3 "No Action" ;
VAL_ 937 Sig7642 0 "No Override" 1 "Override to Not Crawl" 2 "Override to Crawl" ;
VAL_ 937 Sig7630 0 "Not Ready" 1 "Ready to Increase Fraction" 2 "Ready to Reduce Fraction" 3 "Force Maximum Fraction" ;
VAL_ 937 Sig3595 0 "No Activation" 1 "Increment Switch Active" 2 "Decrement Switch Active" 3 "Increment and Decrement Switches Active" ;
VAL_ 937 Sig7647 0 "No Override" 1 "Override To Not Track" 2 "Override To Track" 3 "No Action" ;
VAL_ 937 Sig7646 0 "No Override" 1 "Override To Not Sport" 2 "Override To Sport" 3 "No Action" ;
VAL_ 937 Sig7645 0 "No Override" 1 "To Not Grade Braking Disable" 2 "To Grade Braking Disable" 3 "No Action" ;
VAL_ 937 Sig7644 0 "No Override" 1 "Override To Not Exhaust Brake" 2 "Override To Exhaust Brake" 3 "No Action" ;
VAL_ 937 Sig7782 0 "No Override" 1 "Engine On" 2 "Engine Off" ;
VAL_ 937 Sig7774 0 "Not Ready" 1 "Ready for All Cylinders" 2 "Ready for Half of TotalCylinders" ;
VAL_ 937 Sig7649 0 "No Override" 1 "Override To Not Winter" 2 "Override To Winter" 3 "No Action" ;
VAL_ 937 Sig7648 0 "No Override" 1 "Override To Not Tow Haul" 2 "Override To Tow Haul" 3 "No Action" ;
VAL_ 937 Sig0436 0 "FALSE" 1 "TRUE" ;
VAL_ 937 Sig7797 0 "FALSE" 1 "TRUE" ;
VAL_ 937 Sig7781 0 "FALSE" 1 "TRUE" ;
VAL_ 937 Sig7779 0 "FALSE" 1 "TRUE" ;
VAL_ 937 Sig7641 0 "FALSE" 1 "TRUE" ;
VAL_ 937 Sig7640 0 "FALSE" 1 "TRUE" ;
VAL_ 937 Sig2588 0 "FALSE" 1 "TRUE" ;
VAL_ 937 DCTLnchCtlAllwd 0 "FALSE" 1 "TRUE" ;
VAL_ 1256 Sig7520 0 "No Action" 1 "No Indication" 2 "Warm" 3 "Increase Speed or Apply Brake" 4 "Ready for Drive Away" 5 "Please Wait" 6 "Apply and Hold Brake" 7 "Cool Down" 8 "Creep Disabled" ;
VAL_ 1256 Sig7529 0 "P0-Powertrain Codes SAE Controlled" 1 "P1-Powertrain Codes MFG Controlled" 2 "P2-Powertrain Codes Reserved" 3 "P3-Powertrain Codes Reserved" 4 "C0-Chassis Codes SAE Controlled" 5 "C1-Chassis Codes MFG Controlled" 6 "C2-Chassis Codes Reserved" 7 "C3-Chassis Codes Reserved" 8 "B0-Body Codes SAE Controlled" 9 "B1-Body Codes MFG Controlled" 10 "B2-Body Codes Reserved" 11 "B3-Body Codes Reserved" 12 "U0-Network Codes SAE Controlled" 13 "U1-Network Codes MFG Controlled" 14 "U2-Network Codes Reserved" 15 "U3-Network Codes Reserved" ;
VAL_ 1256 Sig7639 0 "No Request" 1 "Default Gear Active" 2 "Hot Modes Active" 3 "Binary Pump Failed" 4 "Engine Speed Limit Active" ;
VAL_ 1256 Sig3509 0 "FALSE" 1 "TRUE" ;
VAL_ 1256 Sig7798 0 "No Override Mode" 1 "Performance Mode" 2 "Lift-Foot Cornering Mode" 3 "Automatic Grade Braking Mode" ;
VAL_ 1256 Sig7650 0 "Unknown" 1 "Low Efficiency" 2 "High Efficiency" 3 "Operation Degraded" 4 "Reliability Degraded" 5 "Reserved" 6 "Reserved" ;
VAL_ 1256 Sig7790 0 "FALSE" 1 "TRUE" ;
VAL_ 1256 Sig7787 0 "FALSE" 1 "TRUE" ;
VAL_ 1256 Sig7776 0 "FALSE" 1 "TRUE" ;
VAL_ 1258 Sig4462 0 "FALSE" 1 "TRUE" ;
VAL_ 1258 Sig4461 0 "FALSE" 1 "TRUE" ;
VAL_ 737 APMLoVltgEnblCmd 0 "Off" 1 "NormalOp" 2 "Precharge" 3 "Preflux" 4 "KeyCrank" 5 "JumpStartInProgress" 6 "JumpStartComplete" 7 "BatteryMaint1" 8 "BatteryMaint2" 9 "BatteryMaint3" 10 "BatteryMaint4" 11 "DevCntrlOn" 12 "DevCntrlOff" 13 "12VGenMode" ;
VAL_ 1808 VICMERDTC_SysDes 0 "P0-Powertrain Codes SAE Controlled" 1 "P1-Powertrain Codes MFG Controlled" 2 "P2-Powertrain Codes Reserved" 3 "P3-Powertrain Codes Reserved" 4 "C0-Chassis Codes SAE Controlled" 5 "C1-Chassis Codes MFG Controlled" 6 "C2-Chassis Codes Reserved" 7 "C3-Chassis Codes Reserved" 8 "B0-Body Codes SAE Controlled" 9 "B1-Body Codes MFG Controlled" 10 "B2-Body Codes Reserved" 11 "B3-Body Codes Reserved" 12 "U0-Network Codes SAE Controlled" 13 "U1-Network Codes MFG Controlled" 14 "U2- Network Codes Reserved" 15 "U3-Network Codes Reserved" ;
VAL_ 1808 VICMEmsRltMlfAtv 0 "FALSE" 1 "TRUE" ;
VAL_ 1808 PIMRI_VICM_PrmntDTCInd 0 "FALSE" 1 "TRUE" ;
VAL_ 1808 PIMRI_VICM_FltsPrsntInd 0 "FALSE" 1 "TRUE" ;
VAL_ 1469 SuprCruzSbscrptnActv 0 "FALSE" 1 "TRUE" ;
VAL_ 1482 AutoVehMdCmdMdReqd 0 "Normal" 1 "Powertrain Sport" 2 "Chassis Sport" 3 "Eco" 4 "Mountain" 5 "Hold" 6 "Snow Ice" 7 "Start Stop" 8 "Tow Haul" 9 "Grade Braking Disable" 10 "Speed Matching" 11 "Track" 12 "Exhaust Brake" 13 "Normal AWD" 14 "Reserved 1" 15 "Reserved 2" 16 "Reserved 3" 17 "Reserved 4" 18 "Reserved 5" 19 "Reserved 6" 20 "Reserved 7" 21 "Reserved 8" 22 "Reserved 9" 23 "Reserved 10" 24 "Reserved 11" 25 "Reserved 12" 26 "Reserved 13" 27 "Reserved 14" 28 "Reserved 15" 29 "Reserved 16" 30 "No Mode Change Requested" 31 "Critically Disabled" ;
VAL_ 1482 BrkSysAirDflctrCoolReq 0 "No Action" 1 "Max Cooling" 2 "Reserved 1" 3 "Reserved 2" ;
VAL_ 1482 ActvAerodynsPerfModeReq 0 "No Action" 1 "Normal" 2 "Sport" 3 "Track" 4 "Show" 5 "Top Speed" 6 "Performance Mode 6" 7 "Performance Mode 7" ;
VAL_ 1482 TrcCntrlSysPr 0 "FALSE" 1 "TRUE" ;
VAL_ 1482 CustmStbCtlRdctReqIndOn 0 "FALSE" 1 "TRUE" ;
VAL_ 1482 ABSPr 0 "FALSE" 1 "TRUE" ;
VAL_ 1482 VehMassEstSts 0 "Undetermined" 1 "Degraded" 2 "Normal" ;
VAL_ 1805 EngOilTmp_Inv 0 "FALSE" 1 "TRUE" ;
VAL_ 1805 Sig7579 0 "FALSE" 1 "TRUE" ;
VAL_ 1805 Sig3481 0 "No Indication" 1 "Range" 2 "Low Fuel and Range" ;
VAL_ 1487 Sig2442 0 "No Indication" 1 "Warning Level 1" 2 "Warning Level 2" 3 "Warning Level 3" 4 "Warning Level 4" 5 "Warning Level 5" 6 "Warning Level 6" 7 "Warning Level 7" 8 "Warning Level 8" 9 "Warning Level 9" 10 "Warning Level 10" 11 "Warning Level 11" 12 "Warning Level 12" 13 "Warning Level 13" 14 "Warning Level 14" 15 "Warning Level 15" ;
VAL_ 1487 Sig2441 0 "No Indication" 1 "Warning Level 1" 2 "Warning Level 2" 3 "Warning Level 3" 4 "Warning Level 4" 5 "Warning Level 5" 6 "Warning Level 6" 7 "Warning Level 7" 8 "Warning Level 8" 9 "Warning Level 9" 10 "Warning Level 10" 11 "Warning Level 11" 12 "Warning Level 12" 13 "Warning Level 13" 14 "Warning Level 14" 15 "Warning Level 15" ;
VAL_ 1487 Sig2447 0 "No Indication" 1 "Warning Level 1" 2 "Warning Level 2" 3 "Warning Level 3" 4 "Warning Level 4" 5 "Warning Level 5" 6 "Warning Level 6" 7 "Warning Level 7" 8 "Warning Level 8" 9 "Warning Level 9" 10 "Warning Level 10" 11 "Warning Level 11" 12 "Warning Level 12" 13 "Warning Level 13" 14 "Warning Level 14" 15 "Warning Level 15" ;
VAL_ 1487 Sig2443 0 "No Indication" 1 "Warning Level 1" 2 "Warning Level 2" 3 "Warning Level 3" 4 "Warning Level 4" 5 "Warning Level 5" 6 "Warning Level 6" 7 "Warning Level 7" 8 "Warning Level 8" 9 "Warning Level 9" 10 "Warning Level 10" 11 "Warning Level 11" 12 "Warning Level 12" 13 "Warning Level 13" 14 "Warning Level 14" 15 "Warning Level 15" ;
VAL_ 1487 Sig2451 0 "FALSE" 1 "TRUE" ;
VAL_ 1487 Sig2452 0 "No Indication" 1 "Warning Level 1" 2 "Warning Level 2" 3 "Warning Level 3" 4 "Warning Level 4" 5 "Warning Level 5" 6 "Warning Level 6" 7 "Warning Level 7" 8 "Warning Level 8" 9 "Warning Level 9" 10 "Warning Level 10" 11 "Warning Level 11" 12 "Warning Level 12" 13 "Warning Level 13" 14 "Warning Level 14" 15 "Warning Level 15" ;
VAL_ 1487 Sig0309 0 "FALSE" 1 "TRUE" ;
VAL_ 1487 Sig0308 0 "FALSE" 1 "TRUE" ;
VAL_ 1487 Sig0307 0 "FALSE" 1 "TRUE" ;
VAL_ 1487 Sig0306 0 "FALSE" 1 "TRUE" ;
VAL_ 1487 Sig0305 0 "FALSE" 1 "TRUE" ;
VAL_ 1487 Sig0626 0 "FALSE" 1 "TRUE" ;
VAL_ 1487 Sig0614 0 "FALSE" 1 "TRUE" ;
VAL_ 1487 Sig0434 0 "FALSE" 1 "TRUE" ;
VAL_ 1487 Sig0312 0 "FALSE" 1 "TRUE" ;
VAL_ 1487 Sig0311 0 "FALSE" 1 "TRUE" ;
VAL_ 1487 Sig0310 0 "FALSE" 1 "TRUE" ;
VAL_ 1488 Sig4815 0 "Setting Unknown" 1 "RPM 1100" 2 "RPM 1200" 3 "RPM 1300" 4 "RPM 1400" 5 "RPM 1500" 6 "RPM 1600" 7 "RPM 1700" 8 "RPM 1800" 9 "RPM 1900" 10 "RPM 2000" 11 "RPM 2100" 12 "RPM 2200" 13 "RPM 2300" 14 "RPM 2400" 15 "RPM 2500" ;
VAL_ 1488 Sig4610 0 "Setting Unknown" 1 "Min 10" 2 "Min 30" 3 "Min 90" 4 "Min 120" 5 "Min 150" 6 "Min 180" 7 "Min 210" 8 "Min 240" 9 "Min 270" 10 "Min 300" 11 "Min 330" 12 "Min 360" 13 "Min 390" 14 "Min 420" 15 "Min 450" ;
VAL_ 1488 Sig4250 0 "No Indication" 1 "Indication 1" 2 "Indication 2" 3 "Indication 3" ;
VAL_ 1488 Sig2586 0 "OK" 1 "Replace Air Filter Soon" 2 "Replace Air Filter Now" 3 "Fault Present" 4 "Disabled" 5 "No Action" ;
VAL_ 1488 Sig4838 0 "Setting Unknown" 1 "RPM 1700" 2 "RPM 1800" 3 "RPM 1900" 4 "RPM 2000" 5 "RPM 2100" 6 "RPM 2200" 7 "RPM 2300" 8 "RPM 2400" 9 "RPM 2500" 10 "RPM 2600" 11 "RPM 2700" 12 "RPM 2800" 13 "RPM 2900" 14 "RPM 3000" 15 "RPM 3100" ;
VAL_ 1488 Sig4885 0 "Setting Unknown" 1 "RPM 5" 2 "RPM 10" 3 "RPM 25" 4 "RPM 50" 5 "RPM 100" 6 "RPM 250" 7 "RPM 500" ;
VAL_ 1488 Sig4863 0 "Setting Unknown" 1 "RPM 900" 2 "RPM 1000" 3 "RPM 1100" 4 "RPM 1200" 5 "RPM 1300" 6 "RPM 1400" 7 "RPM 1500" ;
VAL_ 1488 Sig2621 0 "FALSE" 1 "TRUE" ;
VAL_ 1488 Sig2620 0 "FALSE" 1 "TRUE" ;
VAL_ 1488 Sig4689 0 "Setting Unknown" 1 "Standard" 2 "Remote" ;
VAL_ 1488 Sig4638 0 "No Indication" 1 "Continuous Indication" 2 "Slow Flashing Indication" 3 "Fast Flashing Indication" ;
VAL_ 1488 Sig4627 0 "Setting Unknown" 1 "Preset" 2 "Variable" ;
VAL_ 1488 Sig2671 0 "FALSE" 1 "TRUE" ;
VAL_ 1488 Sig2668 0 "FALSE" 1 "TRUE" ;
VAL_ 1488 Sig2667 0 "FALSE" 1 "TRUE" ;
VAL_ 1488 Sig2644 0 "FALSE" 1 "TRUE" ;
VAL_ 1488 Sig2641 0 "FALSE" 1 "TRUE" ;
VAL_ 1488 Sig2639 0 "FALSE" 1 "TRUE" ;
VAL_ 1488 Sig2637 0 "FALSE" 1 "TRUE" ;
VAL_ 1488 Sig2636 0 "FALSE" 1 "TRUE" ;
VAL_ 1488 Sig4675 0 "FALSE" 1 "TRUE" ;
VAL_ 1488 Sig4636 0 "FALSE" 1 "TRUE" ;
VAL_ 1488 Sig4629 0 "FALSE" 1 "TRUE" ;
VAL_ 1488 Sig4612 0 "FALSE" 1 "TRUE" ;
VAL_ 1488 Sig4539 0 "FALSE" 1 "TRUE" ;
VAL_ 1488 Sig4496 0 "FALSE" 1 "TRUE" ;
VAL_ 1488 Sig4481 0 "FALSE" 1 "TRUE" ;
VAL_ 1488 Sig4479 0 "FALSE" 1 "TRUE" ;
VAL_ 1488 Sig4840 0 "FALSE" 1 "TRUE" ;
VAL_ 1488 Sig4817 0 "FALSE" 1 "TRUE" ;
VAL_ 1488 Sig4798 0 "FALSE" 1 "TRUE" ;
VAL_ 1488 Sig4730 0 "FALSE" 1 "TRUE" ;
VAL_ 1488 Sig4728 0 "FALSE" 1 "TRUE" ;
VAL_ 1488 Sig4726 0 "FALSE" 1 "TRUE" ;
VAL_ 1488 Sig4712 0 "FALSE" 1 "TRUE" ;
VAL_ 1488 Sig4691 0 "FALSE" 1 "TRUE" ;
VAL_ 1488 Sig7799 0 "FALSE" 1 "TRUE" ;
VAL_ 1488 Sig6769 0 "FALSE" 1 "TRUE" ;
VAL_ 1488 Sig4906 0 "FALSE" 1 "TRUE" ;
VAL_ 1488 Sig4893 0 "FALSE" 1 "TRUE" ;
VAL_ 1488 Sig4887 0 "FALSE" 1 "TRUE" ;
VAL_ 1488 Sig4865 0 "FALSE" 1 "TRUE" ;
VAL_ 1488 Sig4846 0 "FALSE" 1 "TRUE" ;
VAL_ 939 TrcCntrlSysEnbld 0 "FALSE" 1 "TRUE" ;
VAL_ 939 EnhdDrvrSeltdMdSwChsUseReq 0 "FALSE" 1 "TRUE" ;
VAL_ 939 AutoVehMdCmdMdFtrEnbld 0 "FALSE" 1 "TRUE" ;
VAL_ 711 ThrPstn_Inv 0 "FALSE" 1 "TRUE" ;
VAL_ 711 EngIntAirTmp_Inv 0 "FALSE" 1 "TRUE" ;
VAL_ 711 EngIntAirTmp_DuD 0 "FALSE" 1 "TRUE" ;
VAL_ 711 HybStatElecVehModeOvrrd 0 "Undetermined" 1 "No Override" 2 "Too Cold" 3 "Battery Low" 4 "Speed too High" 5 "Generic Override" 6 "Grade too High" 7 "Accelerator Pedal Threshold Exceeded" ;
VAL_ 711 EngCntrlDtrmdTrfCRng 0 "High" 1 "Low" 2 "Unused and Reserved" 3 "Neutral" ;
VAL_ 711 EngCntrlDtrmdTrfCRng_Inv 0 "FALSE" 1 "TRUE" ;
VAL_ 711 PTHiElecLdReqd 0 "FALSE" 1 "TRUE" ;
VAL_ 711 ACCmCltEngd 0 "FALSE" 1 "TRUE" ;
VAL_ 711 HybStatShtlModeOvrrd 0 "Undetermined" 1 "No Override" 2 "Too Cold" 3 "Battery Low" 4 "Speed too High" 5 "Generic Override" 6 "Grade too High" 7 "Accelerator Pedal Threshold Exceeded" ;
VAL_ 1489 ArbdEngTemp_Inv 0 "FALSE" 1 "TRUE" ;
VAL_ 1489 EngInltSpcfcHmdty_Inv 0 "FALSE" 1 "TRUE" ;
VAL_ 1489 EngInltSpcfcHmdty_DuD 0 "FALSE" 1 "TRUE" ;
VAL_ 1489 SmrtCoolFan2FltActv 0 "FALSE" 1 "TRUE" ;
VAL_ 1489 SmrtCoolFan1FltActv 0 "FALSE" 1 "TRUE" ;
VAL_ 1489 EngCstFlCtOffAct 0 "FALSE" 1 "TRUE" ;
VAL_ 85 CSTATRS_ReqSts 0 "No Request" 1 "Request Honored" 2 "Lost Arbitration" 3 "Serial Data Failure Temporary" 4 "Serial Data Failure Permanent" 5 "Control System Failure Temporary" 6 "Control System Failure Permanent" ;
VAL_ 1260 OTARC_RejCrdntnECP_X1 0 "FALSE" 1 "TRUE" ;
VAL_ 1260 OTARC_RejCrdntnECP_S 0 "FALSE" 1 "TRUE" ;
VAL_ 1260 OTARC_RejCrdntnECP_MC 0 "FALSE" 1 "TRUE" ;
VAL_ 1260 OTARC_RejCrdntnECM 0 "FALSE" 1 "TRUE" ;
VAL_ 1260 OTARC_RejCrdntnEBCM 0 "FALSE" 1 "TRUE" ;
VAL_ 1260 OTARC_RejCrdntnBSM_MH 0 "FALSE" 1 "TRUE" ;
VAL_ 1260 OTARC_RejCrdntnBSM 0 "FALSE" 1 "TRUE" ;
VAL_ 1260 OTARC_RejCrdntnBCM 0 "FALSE" 1 "TRUE" ;
VAL_ 1260 OTARC_RejCrdntnECU_19 0 "FALSE" 1 "TRUE" ;
VAL_ 1260 OTARC_RejCrdntnECU_18 0 "FALSE" 1 "TRUE" ;
VAL_ 1260 OTARC_RejCrdntnECU_17 0 "FALSE" 1 "TRUE" ;
VAL_ 1260 OTARC_RejCrdntnECU_16 0 "FALSE" 1 "TRUE" ;
VAL_ 1260 OTARC_RejCrdntnECU_15 0 "FALSE" 1 "TRUE" ;
VAL_ 1260 OTARC_RejCrdntnSBM 0 "FALSE" 1 "TRUE" ;
VAL_ 1260 OTARC_RejCrdntnCGM 0 "FALSE" 1 "TRUE" ;
VAL_ 1260 OTARC_RejCrdntnECP_X2 0 "FALSE" 1 "TRUE" ;
VAL_ 1260 OTARC_RejCrdntnECU_27 0 "FALSE" 1 "TRUE" ;
VAL_ 1260 OTARC_RejCrdntnECU_26 0 "FALSE" 1 "TRUE" ;
VAL_ 1260 OTARC_RejCrdntnECU_25 0 "FALSE" 1 "TRUE" ;
VAL_ 1260 OTARC_RejCrdntnECU_24 0 "FALSE" 1 "TRUE" ;
VAL_ 1260 OTARC_RejCrdntnECU_23 0 "FALSE" 1 "TRUE" ;
VAL_ 1260 OTARC_RejCrdntnECU_22 0 "FALSE" 1 "TRUE" ;
VAL_ 1260 OTARC_RejCrdntnECU_21 0 "FALSE" 1 "TRUE" ;
VAL_ 1260 OTARC_RejCrdntnECU_20 0 "FALSE" 1 "TRUE" ;
VAL_ 1260 OTARC_RejCrdntnTCM 0 "FALSE" 1 "TRUE" ;
VAL_ 1260 OTARC_RejCrdntnICCM 0 "FALSE" 1 "TRUE" ;
VAL_ 1260 OTARC_RejCrdntnFICM 0 "FALSE" 1 "TRUE" ;
VAL_ 1260 OTARC_RejCrdntnECU_32 0 "FALSE" 1 "TRUE" ;
VAL_ 1260 OTARC_RejCrdntnECU_31 0 "FALSE" 1 "TRUE" ;
VAL_ 1260 OTARC_RejCrdntnECU_30 0 "FALSE" 1 "TRUE" ;
VAL_ 1260 OTARC_RejCrdntnECU_29 0 "FALSE" 1 "TRUE" ;
VAL_ 1260 OTARC_RejCrdntnECU_28 0 "FALSE" 1 "TRUE" ;
VAL_ 1806 DTCClrInhbd 0 "FALSE" 1 "TRUE" ;
VAL_ 56 PwrtrnShfLvrLckReqd 0 "FALSE" 1 "TRUE" ;
VAL_ 935 DrvMode8Ovrrdn 0 "FALSE" 1 "TRUE" ;
VAL_ 935 DrvMode7Ovrrdn 0 "FALSE" 1 "TRUE" ;
VAL_ 935 DrvMode6Ovrrdn 0 "FALSE" 1 "TRUE" ;
VAL_ 935 DrvMode5Ovrrdn 0 "FALSE" 1 "TRUE" ;
VAL_ 935 DrvMode4Ovrrdn 0 "FALSE" 1 "TRUE" ;
VAL_ 935 DrvMode3Ovrrdn 0 "FALSE" 1 "TRUE" ;
VAL_ 935 DrvMode2Ovrrdn 0 "FALSE" 1 "TRUE" ;
VAL_ 935 DrvMode1Ovrrdn 0 "FALSE" 1 "TRUE" ;
VAL_ 1493 GenFld 0 "FALSE" 1 "TRUE" ;
VAL_ 1493 ACCompCmnd 0 "Off" 1 "On" ;
VAL_ 1493 ACCompCmnd_Inv 0 "FALSE" 1 "TRUE" ;
VAL_ 514 LIB1CurrRwVal_Inv 0 "FALSE" 1 "TRUE" ;
VAL_ 514 LIB1CurrRwVal_DuD 0 "FALSE" 1 "TRUE" ;
VAL_ 514 LIB1CurrRwValMult_Inv 0 "FALSE" 1 "TRUE" ;
VAL_ 514 LIB1CurrRwValMult_DuD 0 "FALSE" 1 "TRUE" ;
VAL_ 514 LIB1CurrRwValMult 0 "Multiplier factor 1" 1 "Multiplier factor 8" 2 "Multiplier factor 64" 3 "Multiplier factor 256" ;
VAL_ 514 LIB1VltgUpprLim_Inv 0 "FALSE" 1 "TRUE" ;
VAL_ 514 LIB1VltgUpprLim_DuD 0 "FALSE" 1 "TRUE" ;
VAL_ 514 LIB1CntctrOpnPrwrn 0 "FALSE" 1 "TRUE" ;
VAL_ 514 LIB1CntctrOpnPrwrn_Inv 0 "FALSE" 1 "TRUE" ;
VAL_ 514 LIB1CntctrSts_Inv 0 "FALSE" 1 "TRUE" ;
VAL_ 514 LIB1CntctrSts_DuD 0 "FALSE" 1 "TRUE" ;
VAL_ 514 LIB1CntctrSts 0 "Closed" 1 "Open" ;
VAL_ 724 PrplDispBatPwr_Inv 0 "FALSE" 1 "TRUE" ;
VAL_ 724 PrplDispBatPwr_DuD 0 "FALSE" 1 "TRUE" ;
VAL_ 724 PrplDispEngPwr_Inv 0 "FALSE" 1 "TRUE" ;
VAL_ 724 PrplDispEngPwr_DuD 0 "FALSE" 1 "TRUE" ;
VAL_ 724 BatPrplDispTrqLvlPct_DuD 0 "FALSE" 1 "TRUE" ;
VAL_ 724 PrplDispBatTrq_Inv 0 "FALSE" 1 "TRUE" ;
VAL_ 724 PrplDispBatTrq_DuD 0 "FALSE" 1 "TRUE" ;
VAL_ 1438 CustNonUsblSOC_Inv 0 "FALSE" 1 "TRUE" ;
VAL_ 1438 CustNonUsblSOC_DuD 0 "FALSE" 1 "TRUE" ;
VAL_ 1438 CustUsblSOC_Inv 0 "FALSE" 1 "TRUE" ;
VAL_ 1438 CustUsblSOC_DuD 0 "FALSE" 1 "TRUE" ;
VAL_ 1438 BatPrplDispPwrLvlPct_DuD 0 "FALSE" 1 "TRUE" ;
VAL_ 1423 ElecMtrATach_Inv 0 "FALSE" 1 "TRUE" ;
VAL_ 1423 ElecMtrATach_DuD 0 "FALSE" 1 "TRUE" ;
VAL_ 1423 HiVltgBatAvgTemp_DuD 0 "FALSE" 1 "TRUE" ;
VAL_ 1423 HiVltgBatAvgTemp_Inv 0 "FALSE" 1 "TRUE" ;
VAL_ 1423 EngPrplDispPwrLvlPct_DuD 0 "FALSE" 1 "TRUE" ;
VAL_ 1423 EngRnngDueToVehSpdIndOn 0 "FALSE" 1 "TRUE" ;
VAL_ 1423 ElecAllWhlDrvIndOn 0 "FALSE" 1 "TRUE" ;
VAL_ 1423 DischrgPwrLtdIndOn 0 "FALSE" 1 "TRUE" ;
VAL_ 1423 DischrgPwrLtdDispPctVsbl 0 "FALSE" 1 "TRUE" ;
VAL_ 1423 HiVltgBatLmtnDueToTempInd 0 "Normal" 1 "Cold" 2 "Hot" ;
VAL_ 1439 HybModeDisp 0 "No Action" 1 "Battery Power" 2 "Engine Power" 3 "Hybrid Power" 4 "Charging with Engine Off" 5 "Charging with Engine On" 6 "Neutral Engine On" 7 "Neutral Engine Off" 8 "Engine Charging" 9 "Engine Power Rear with Battery Front" 10 "Engine Power Rear with Front Wheel Regen" 11 "Undetermined" 12 "Default and Accessory" 13 "Engine Idle" 14 "Reserved 1" 15 "Reserved 2" 16 "Reserved 3" ;
VAL_ 1439 HTD1_FuelAvdd_DuD 0 "FALSE" 1 "TRUE" ;
VAL_ 1439 InstnsFuelEconHybOvrrdReq 0 "No Action" 1 "Min Fuel Economy" 2 "Max Fuel Economy" 3 "Auto Stop" 4 "EV" ;
VAL_ 1439 HybModeDispVehCfg 0 "No Action" 1 "Not in Motion" 2 "FWD" 3 "RWD" 4 "4WD" ;
VAL_ 1439 HiVltgChrgrSysSts 0 "Default" 1 "Idle" 2 "Initializing" 3 "Active" 4 "Complete" 5 "Aborted" 6 "Utility Override Active" 7 "Utility Override Reduced Power" 8 "Pause Due to Update" 9 "Connection Unpowered" 10 "Unconnected" 11 "Offboard Energy Transfer Active" ;
VAL_ 1439 HybShfToPrkIndOn 0 "FALSE" 1 "TRUE" ;
VAL_ 1439 HiVltgSysDsbld 0 "FALSE" 1 "TRUE" ;
VAL_ 1439 JmpStrtSts 0 "Inactive" 1 "In Progress" 2 "Complete" 3 "Power Mode" 4 "Disabled" ;
VAL_ 1440 PrplDispTotPwr_DuD 0 "FALSE" 1 "TRUE" ;
VAL_ 1440 PrplDispTotPwr_Inv 0 "FALSE" 1 "TRUE" ;
VAL_ 1440 ServHybSysIndOn 0 "FALSE" 1 "TRUE" ;
VAL_ 1440 RegenPwrLimdIndOn 0 "FALSE" 1 "TRUE" ;
VAL_ 1440 RegenPwrLimdDispPctVsbl 0 "FALSE" 1 "TRUE" ;
VAL_ 1440 PrplDispTotPwrUntDisp 0 "kilowatt" 1 "Horsepower" ;
VAL_ 1440 LossOfPrplIndOn 0 "FALSE" 1 "TRUE" ;
VAL_ 1440 ServHiVltgBatIndReq 0 "No Indication" 1 "Shut Down Soon" 2 "No Restart" ;
VAL_ 1483 BrkPadLifeFrtDistWrnIndReq 0 "No Action" 1 "Low" 2 "Display Distance" ;
VAL_ 1483 BrkPadLifeStsIndReq 0 "No Action" 1 "Not Present" 2 "Ok" 3 "Change Soon" 4 "Change Now" 5 "Disabled" 6 "Service" ;
VAL_ 1483 BrkPadLifeRrDistWrnIndReq 0 "No Action" 1 "Low" 2 "Display Distance" ;
VAL_ 1483 ESCSpdLtdIndReq 0 "No Indication" 1 "Countdown" 2 "Limited" ;
VAL_ 1483 HillDscntCtlRdcVehSpdIndOn 0 "FALSE" 1 "TRUE" ;
VAL_ 1483 HillDscntCtlDispActvIndOn 0 "FALSE" 1 "TRUE" ;
VAL_ 1483 BrkPadLifeFrtCnfrmRplcmtIndOn 0 "FALSE" 1 "TRUE" ;
VAL_ 1483 BrkOvrhtdIndOn 0 "FALSE" 1 "TRUE" ;
VAL_ 1483 AllWhlDrvRcmndIndOn 0 "FALSE" 1 "TRUE" ;
VAL_ 1483 CrwlModeDndRsnIndReq 0 "No Indication" 1 "Unavailable" 2 "Brakes Overtemp" 3 "Shift to 4 High" 4 "Reduce Speed" ;
VAL_ 1483 BrksOvrht 0 "FALSE" 1 "TRUE" ;
VAL_ 1483 BrkSysTwoFtdDrvDtdIndOn 0 "FALSE" 1 "TRUE" ;
VAL_ 1483 BrkSysHillStrtAsstAvl 0 "FALSE" 1 "TRUE" ;
VAL_ 1483 BrkPadWrnIO 0 "FALSE" 1 "TRUE" ;
VAL_ 1483 BrkPadLifeRrCnfrmRplcmtIndOn 0 "FALSE" 1 "TRUE" ;
